VERSION ""

NS_ :

BS_:

BU_:

BO_ 2566642942 DC4: 8 Vector__XXX
 SG_ EnableStatusofDoor21 : 4|2@1+ (1,0) [0|3] "" Vector__XXX
 SG_ EnableStatusofDoor22 : 10|2@1+ (1,0) [0|3] "" Vector__XXX
 SG_ EnableStatusofDoor23 : 16|2@1+ (1,0) [0|3] "" Vector__XXX
 SG_ EnableStatusofDoor24 : 22|2@1+ (1,0) [0|3] "" Vector__XXX
 SG_ EnableStatusofDoor25 : 28|2@1+ (1,0) [0|3] "" Vector__XXX
 SG_ EnableStatusofDoor26 : 34|2@1+ (1,0) [0|3] "" Vector__XXX
 SG_ EnableStatusofDoor27 : 40|2@1+ (1,0) [0|3] "" Vector__XXX
 SG_ EnableStatusofDoor28 : 46|2@1+ (1,0) [0|3] "" Vector__XXX
 SG_ EnableStatusofDoor29 : 52|2@1+ (1,0) [0|3] "" Vector__XXX
 SG_ EnableStatusofDoor30 : 58|2@1+ (1,0) [0|3] "" Vector__XXX
 SG_ LockStatusofDoor21 : 0|2@1+ (1,0) [0|3] "" Vector__XXX
 SG_ LockStatusofDoor22 : 6|2@1+ (1,0) [0|3] "" Vector__XXX
 SG_ LockStatusofDoor23 : 12|2@1+ (1,0) [0|3] "" Vector__XXX
 SG_ LockStatusofDoor24 : 18|2@1+ (1,0) [0|3] "" Vector__XXX
 SG_ LockStatusofDoor25 : 24|2@1+ (1,0) [0|3] "" Vector__XXX
 SG_ LockStatusofDoor26 : 30|2@1+ (1,0) [0|3] "" Vector__XXX
 SG_ LockStatusofDoor27 : 36|2@1+ (1,0) [0|3] "" Vector__XXX
 SG_ LockStatusofDoor28 : 42|2@1+ (1,0) [0|3] "" Vector__XXX
 SG_ LockStatusofDoor29 : 48|2@1+ (1,0) [0|3] "" Vector__XXX
 SG_ LockStatusofDoor30 : 54|2@1+ (1,0) [0|3] "" Vector__XXX
 SG_ OpenStatusofDoor21 : 2|2@1+ (1,0) [0|3] "" Vector__XXX
 SG_ OpenStatusofDoor22 : 8|2@1+ (1,0) [0|3] "" Vector__XXX
 SG_ OpenStatusofDoor23 : 14|2@1+ (1,0) [0|3] "" Vector__XXX
 SG_ OpenStatusofDoor24 : 20|2@1+ (1,0) [0|3] "" Vector__XXX
 SG_ OpenStatusofDoor25 : 26|2@1+ (1,0) [0|3] "" Vector__XXX
 SG_ OpenStatusofDoor26 : 32|2@1+ (1,0) [0|3] "" Vector__XXX
 SG_ OpenStatusofDoor27 : 38|2@1+ (1,0) [0|3] "" Vector__XXX
 SG_ OpenStatusofDoor28 : 44|2@1+ (1,0) [0|3] "" Vector__XXX
 SG_ OpenStatusofDoor29 : 50|2@1+ (1,0) [0|3] "" Vector__XXX
 SG_ OpenStatusofDoor30 : 56|2@1+ (1,0) [0|3] "" Vector__XXX

BO_ 2566643198 DC3: 8 Vector__XXX
 SG_ EnableStatusofDoor11 : 4|2@1+ (1,0) [0|3] "" Vector__XXX
 SG_ EnableStatusofDoor12 : 10|2@1+ (1,0) [0|3] "" Vector__XXX
 SG_ EnableStatusofDoor13 : 16|2@1+ (1,0) [0|3] "" Vector__XXX
 SG_ EnableStatusofDoor14 : 22|2@1+ (1,0) [0|3] "" Vector__XXX
 SG_ EnableStatusofDoor15 : 28|2@1+ (1,0) [0|3] "" Vector__XXX
 SG_ EnableStatusofDoor16 : 34|2@1+ (1,0) [0|3] "" Vector__XXX
 SG_ EnableStatusofDoor17 : 40|2@1+ (1,0) [0|3] "" Vector__XXX
 SG_ EnableStatusofDoor18 : 46|2@1+ (1,0) [0|3] "" Vector__XXX
 SG_ EnableStatusofDoor19 : 52|2@1+ (1,0) [0|3] "" Vector__XXX
 SG_ EnableStatusofDoor20 : 58|2@1+ (1,0) [0|3] "" Vector__XXX
 SG_ LockStatusofDoor11 : 0|2@1+ (1,0) [0|3] "" Vector__XXX
 SG_ LockStatusofDoor12 : 6|2@1+ (1,0) [0|3] "" Vector__XXX
 SG_ LockStatusofDoor13 : 12|2@1+ (1,0) [0|3] "" Vector__XXX
 SG_ LockStatusofDoor14 : 18|2@1+ (1,0) [0|3] "" Vector__XXX
 SG_ LockStatusofDoor15 : 24|2@1+ (1,0) [0|3] "" Vector__XXX
 SG_ LockStatusofDoor16 : 30|2@1+ (1,0) [0|3] "" Vector__XXX
 SG_ LockStatusofDoor17 : 36|2@1+ (1,0) [0|3] "" Vector__XXX
 SG_ LockStatusofDoor18 : 42|2@1+ (1,0) [0|3] "" Vector__XXX
 SG_ LockStatusofDoor19 : 48|2@1+ (1,0) [0|3] "" Vector__XXX
 SG_ LockStatusofDoor20 : 54|2@1+ (1,0) [0|3] "" Vector__XXX
 SG_ OpenStatusofDoor11 : 2|2@1+ (1,0) [0|3] "" Vector__XXX
 SG_ OpenStatusofDoor12 : 8|2@1+ (1,0) [0|3] "" Vector__XXX
 SG_ OpenStatusofDoor13 : 14|2@1+ (1,0) [0|3] "" Vector__XXX
 SG_ OpenStatusofDoor14 : 20|2@1+ (1,0) [0|3] "" Vector__XXX
 SG_ OpenStatusofDoor15 : 26|2@1+ (1,0) [0|3] "" Vector__XXX
 SG_ OpenStatusofDoor16 : 32|2@1+ (1,0) [0|3] "" Vector__XXX
 SG_ OpenStatusofDoor17 : 38|2@1+ (1,0) [0|3] "" Vector__XXX
 SG_ OpenStatusofDoor18 : 44|2@1+ (1,0) [0|3] "" Vector__XXX
 SG_ OpenStatusofDoor19 : 50|2@1+ (1,0) [0|3] "" Vector__XXX
 SG_ OpenStatusofDoor20 : 56|2@1+ (1,0) [0|3] "" Vector__XXX

BO_ 2566643454 ET6: 8 Vector__XXX
 SG_ EngineIntakeCoolantTemperature : 32|16@1+ (0.03125,-273) [-273|1734.96875] "degC" Vector__XXX
 SG_ EngnChrgArClrIntkClntTmprtr : 0|16@1+ (0.03125,-273) [-273|1734.96875] "degC" Vector__XXX
 SG_ EngnChrgArClrOtltClntTmprtr : 16|16@1+ (0.03125,-273) [-273|1734.96875] "degC" Vector__XXX

BO_ 2566643710 IC3: 8 Vector__XXX
 SG_ EngineMixer1IntakePressure : 0|16@1+ (0.1,0) [0|6425.5] "kPa" Vector__XXX
 SG_ EngineMixer2IntakePressure : 16|16@1+ (0.1,0) [0|6425.5] "kPa" Vector__XXX

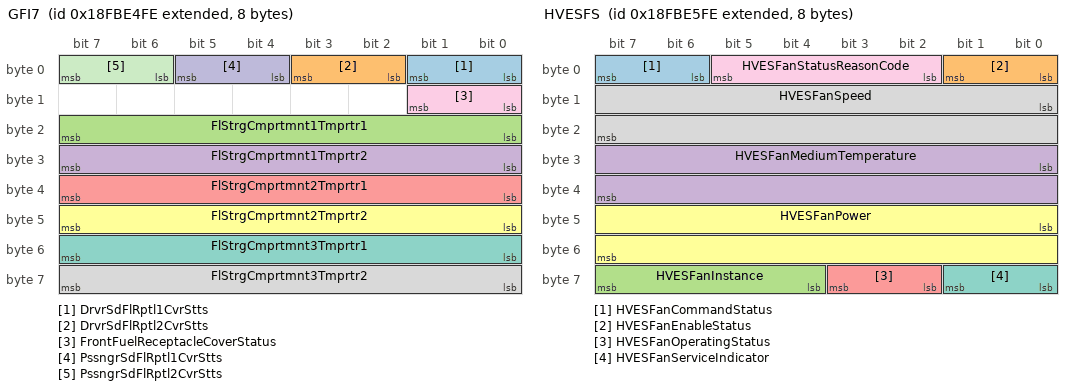
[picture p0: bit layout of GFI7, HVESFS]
BO_ 2566644990 GFI7: 8 Vector__XXX
 SG_ DrvrSdFlRptl1CvrStts : 0|2@1+ (1,0) [0|3] "" Vector__XXX
 SG_ DrvrSdFlRptl2CvrStts : 2|2@1+ (1,0) [0|3] "" Vector__XXX
 SG_ FlStrgCmprtmnt1Tmprtr1 : 16|8@1+ (1,-40) [-40|210] "degC" Vector__XXX
 SG_ FlStrgCmprtmnt1Tmprtr2 : 24|8@1+ (1,-40) [-40|210] "degC" Vector__XXX
 SG_ FlStrgCmprtmnt2Tmprtr1 : 32|8@1+ (1,-40) [-40|210] "degC" Vector__XXX
 SG_ FlStrgCmprtmnt2Tmprtr2 : 40|8@1+ (1,-40) [-40|210] "degC" Vector__XXX
 SG_ FlStrgCmprtmnt3Tmprtr1 : 48|8@1+ (1,-40) [-40|210] "degC" Vector__XXX
 SG_ FlStrgCmprtmnt3Tmprtr2 : 56|8@1+ (1,-40) [-40|210] "degC" Vector__XXX
 SG_ FrontFuelReceptacleCoverStatus : 8|2@1+ (1,0) [0|3] "" Vector__XXX
 SG_ PssngrSdFlRptl1CvrStts : 4|2@1+ (1,0) [0|3] "" Vector__XXX
 SG_ PssngrSdFlRptl2CvrStts : 6|2@1+ (1,0) [0|3] "" Vector__XXX

BO_ 2566645246 HVESFS: 8 Vector__XXX
 SG_ HVESFanCommandStatus : 6|2@1+ (1,0) [0|3] "" Vector__XXX
 SG_ HVESFanEnableStatus : 0|2@1+ (1,0) [0|3] "" Vector__XXX
 SG_ HVESFanInstance : 60|4@1+ (1,0) [0|15] "" Vector__XXX
 SG_ HVESFanMediumTemperature : 24|16@1+ (0.03125,-273) [-273|1734.96875] "degC" Vector__XXX
 SG_ HVESFanOperatingStatus : 58|2@1+ (1,0) [0|3] "" Vector__XXX
 SG_ HVESFanPower : 40|16@1+ (0.5,0) [0|32127.5] "W" Vector__XXX
 SG_ HVESFanServiceIndicator : 56|2@1+ (1,0) [0|3] "" Vector__XXX
 SG_ HVESFanSpeed : 8|16@1+ (0.5,0) [0|32127.5] "rpm" Vector__XXX
 SG_ HVESFanStatusReasonCode : 2|4@1+ (1,0) [0|15] "" Vector__XXX

BO_ 2566646782 ODMCF12: 8 Vector__XXX
 SG_ OlDrsMntrFrrsBn1Cnt : 8|24@1+ (1,0) [0|1.64495E+07] "count" Vector__XXX
 SG_ OlDrsMntrFrrsBn2Cnt : 32|24@1+ (1,0) [0|1.64495E+07] "count" Vector__XXX
 SG_ OlDrsMntrFrrsBns1nd2IdntftnNmr : 0|8@1+ (1,0) [0|250] "count" Vector__XXX

BO_ 2566647038 ODMCF34: 8 Vector__XXX
 SG_ OlDrsMntrFrrsBn3Cnt : 8|24@1+ (1,0) [0|1.64495E+07] "count" Vector__XXX
 SG_ OlDrsMntrFrrsBn4Cnt : 32|24@1+ (1,0) [0|1.64495E+07] "count" Vector__XXX
 SG_ OlDrsMntrFrrsBns3nd4IdntftnNmr : 0|8@1+ (1,0) [0|250] "count" Vector__XXX

BO_ 2566647294 ODMCF56: 8 Vector__XXX
 SG_ OlDrsMntrFrrsBn5Cnt : 8|24@1+ (1,0) [0|1.64495E+07] "count" Vector__XXX
 SG_ OlDrsMntrFrrsBn6Cnt : 32|24@1+ (1,0) [0|1.64495E+07] "count" Vector__XXX
 SG_ OlDrsMntrFrrsBns5nd6IdntftnNmr : 0|8@1+ (1,0) [0|250] "count" Vector__XXX

BO_ 2566647550 ODMCNF12: 8 Vector__XXX
 SG_ ODsMtNFsBs1d2IdttN : 0|8@1+ (1,0) [0|250] "count" Vector__XXX
 SG_ OlDrsMntrNnFrrsBn1Cnt : 8|24@1+ (1,0) [0|1.64495E+07] "count" Vector__XXX
 SG_ OlDrsMntrNnFrrsBn2Cnt : 32|24@1+ (1,0) [0|1.64495E+07] "count" Vector__XXX

BO_ 2566647806 ODMCNF34: 8 Vector__XXX
 SG_ ODsMtNFsBs3d4IdttN : 0|8@1+ (1,0) [0|250] "count" Vector__XXX
 SG_ OlDrsMntrNnFrrsBn3Cnt : 8|24@1+ (1,0) [0|1.64495E+07] "count" Vector__XXX
 SG_ OlDrsMntrNnFrrsBn4Cnt : 32|24@1+ (1,0) [0|1.64495E+07] "count" Vector__XXX

BO_ 2566648062 ODMCNF56: 8 Vector__XXX
 SG_ ODsMtNFsBs5d6IdttN : 0|8@1+ (1,0) [0|250] "count" Vector__XXX
 SG_ OlDrsMntrNnFrrsBn5Cnt : 8|24@1+ (1,0) [0|1.64495E+07] "count" Vector__XXX
 SG_ OlDrsMntrNnFrrsBn6Cnt : 32|24@1+ (1,0) [0|1.64495E+07] "count" Vector__XXX

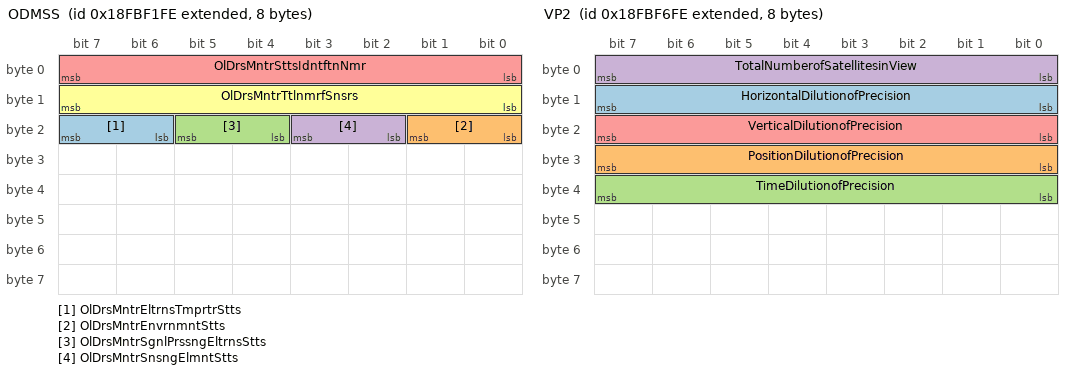
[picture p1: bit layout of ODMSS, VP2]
BO_ 2566648318 ODMSS: 8 Vector__XXX
 SG_ OlDrsMntrEltrnsTmprtrStts : 22|2@1+ (1,0) [0|3] "" Vector__XXX
 SG_ OlDrsMntrEnvrnmntStts : 16|2@1+ (1,0) [0|3] "" Vector__XXX
 SG_ OlDrsMntrSgnlPrssngEltrnsStts : 20|2@1+ (1,0) [0|3] "" Vector__XXX
 SG_ OlDrsMntrSnsngElmntStts : 18|2@1+ (1,0) [0|3] "" Vector__XXX
 SG_ OlDrsMntrSttsIdntftnNmr : 0|8@1+ (1,0) [0|250] "count" Vector__XXX
 SG_ OlDrsMntrTtlnmrfSnsrs : 8|8@1+ (1,0) [0|250] "count" Vector__XXX

BO_ 2566649086 A2DOC2: 8 Vector__XXX
 SG_ Atttt2DOCIttDPFOttDtPss : 32|16@1+ (0.1,0) [0|6425.5] "kPa" Vector__XXX
 SG_ Atttt2DsOxdtCtstItPss : 0|16@1+ (0.1,0) [0|6425.5] "kPa" Vector__XXX
 SG_ Atttt2DsOxdtCtstOttPss : 16|16@1+ (0.1,0) [0|6425.5] "kPa" Vector__XXX

BO_ 2566649342 A1DOC2: 8 Vector__XXX
 SG_ Atttt1DOCIttDPFOttDtPss : 32|16@1+ (0.1,0) [0|6425.5] "kPa" Vector__XXX
 SG_ Atttt1DsOxdtCtstItPss : 0|16@1+ (0.1,0) [0|6425.5] "kPa" Vector__XXX
 SG_ Atttt1DsOxdtCtstOttPss : 16|16@1+ (0.1,0) [0|6425.5] "kPa" Vector__XXX

BO_ 2566649598 VP2: 8 Vector__XXX
 SG_ HorizontalDilutionofPrecision : 8|8@1+ (0.1,0) [0|25] "Ratio" Vector__XXX
 SG_ PositionDilutionofPrecision : 24|8@1+ (0.1,0) [0|25] "Ratio" Vector__XXX
 SG_ TimeDilutionofPrecision : 32|8@1+ (0.1,0) [0|25] "Ratio" Vector__XXX
 SG_ TotalNumberofSatellitesinView : 0|8@1+ (1,0) [0|250] "count" Vector__XXX
 SG_ VerticalDilutionofPrecision : 16|8@1+ (0.1,0) [0|25] "Ratio" Vector__XXX

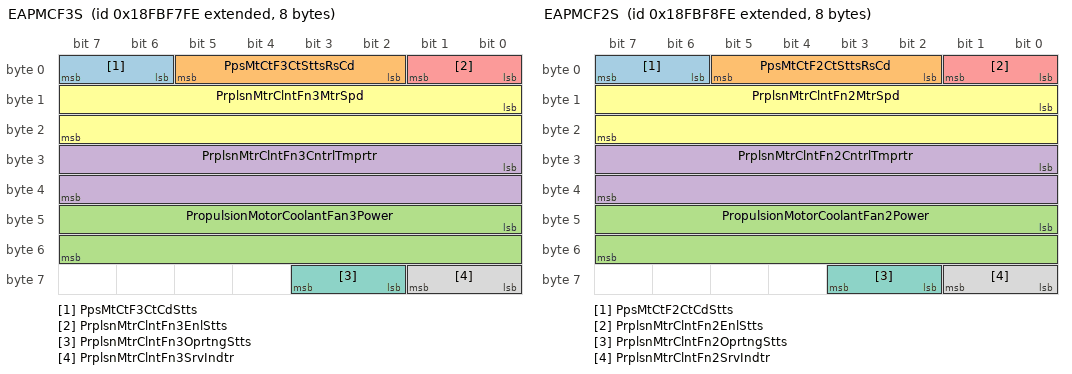
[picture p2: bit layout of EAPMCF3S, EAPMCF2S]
BO_ 2566649854 EAPMCF3S: 8 Vector__XXX
 SG_ PpsMtCtF3CtCdStts : 6|2@1+ (1,0) [0|3] "" Vector__XXX
 SG_ PpsMtCtF3CtSttsRsCd : 2|4@1+ (1,0) [0|15] "" Vector__XXX
 SG_ PropulsionMotorCoolantFan3Power : 40|16@1+ (0.5,0) [0|32127.5] "W" Vector__XXX
 SG_ PrplsnMtrClntFn3CntrlTmprtr : 24|16@1+ (0.03125,-273) [-273|1734.96875] "degC" Vector__XXX
 SG_ PrplsnMtrClntFn3EnlStts : 0|2@1+ (1,0) [0|3] "" Vector__XXX
 SG_ PrplsnMtrClntFn3MtrSpd : 8|16@1+ (0.5,0) [0|32127.5] "rpm" Vector__XXX
 SG_ PrplsnMtrClntFn3OprtngStts : 58|2@1+ (1,0) [0|3] "" Vector__XXX
 SG_ PrplsnMtrClntFn3SrvIndtr : 56|2@1+ (1,0) [0|3] "" Vector__XXX

BO_ 2566650110 EAPMCF2S: 8 Vector__XXX
 SG_ PpsMtCtF2CtCdStts : 6|2@1+ (1,0) [0|3] "" Vector__XXX
 SG_ PpsMtCtF2CtSttsRsCd : 2|4@1+ (1,0) [0|15] "" Vector__XXX
 SG_ PropulsionMotorCoolantFan2Power : 40|16@1+ (0.5,0) [0|32127.5] "W" Vector__XXX
 SG_ PrplsnMtrClntFn2CntrlTmprtr : 24|16@1+ (0.03125,-273) [-273|1734.96875] "degC" Vector__XXX
 SG_ PrplsnMtrClntFn2EnlStts : 0|2@1+ (1,0) [0|3] "" Vector__XXX
 SG_ PrplsnMtrClntFn2MtrSpd : 8|16@1+ (0.5,0) [0|32127.5] "rpm" Vector__XXX
 SG_ PrplsnMtrClntFn2OprtngStts : 58|2@1+ (1,0) [0|3] "" Vector__XXX
 SG_ PrplsnMtrClntFn2SrvIndtr : 56|2@1+ (1,0) [0|3] "" Vector__XXX

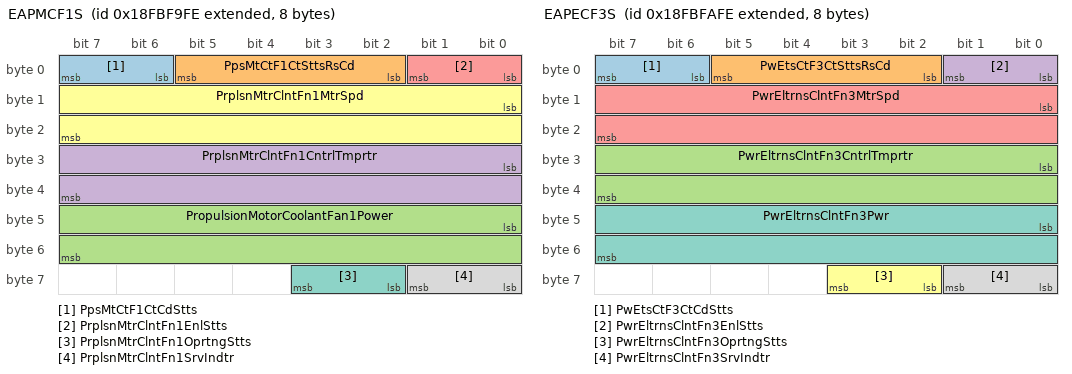
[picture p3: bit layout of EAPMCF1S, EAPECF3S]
BO_ 2566650366 EAPMCF1S: 8 Vector__XXX
 SG_ PpsMtCtF1CtCdStts : 6|2@1+ (1,0) [0|3] "" Vector__XXX
 SG_ PpsMtCtF1CtSttsRsCd : 2|4@1+ (1,0) [0|15] "" Vector__XXX
 SG_ PropulsionMotorCoolantFan1Power : 40|16@1+ (0.5,0) [0|32127.5] "W" Vector__XXX
 SG_ PrplsnMtrClntFn1CntrlTmprtr : 24|16@1+ (0.03125,-273) [-273|1734.96875] "degC" Vector__XXX
 SG_ PrplsnMtrClntFn1EnlStts : 0|2@1+ (1,0) [0|3] "" Vector__XXX
 SG_ PrplsnMtrClntFn1MtrSpd : 8|16@1+ (0.5,0) [0|32127.5] "rpm" Vector__XXX
 SG_ PrplsnMtrClntFn1OprtngStts : 58|2@1+ (1,0) [0|3] "" Vector__XXX
 SG_ PrplsnMtrClntFn1SrvIndtr : 56|2@1+ (1,0) [0|3] "" Vector__XXX

BO_ 2566650622 EAPECF3S: 8 Vector__XXX
 SG_ PwEtsCtF3CtCdStts : 6|2@1+ (1,0) [0|3] "" Vector__XXX
 SG_ PwEtsCtF3CtSttsRsCd : 2|4@1+ (1,0) [0|15] "" Vector__XXX
 SG_ PwrEltrnsClntFn3CntrlTmprtr : 24|16@1+ (0.03125,-273) [-273|1734.96875] "degC" Vector__XXX
 SG_ PwrEltrnsClntFn3EnlStts : 0|2@1+ (1,0) [0|3] "" Vector__XXX
 SG_ PwrEltrnsClntFn3MtrSpd : 8|16@1+ (0.5,0) [0|32127.5] "rpm" Vector__XXX
 SG_ PwrEltrnsClntFn3OprtngStts : 58|2@1+ (1,0) [0|3] "" Vector__XXX
 SG_ PwrEltrnsClntFn3Pwr : 40|16@1+ (0.5,0) [0|32127.5] "W" Vector__XXX
 SG_ PwrEltrnsClntFn3SrvIndtr : 56|2@1+ (1,0) [0|3] "" Vector__XXX

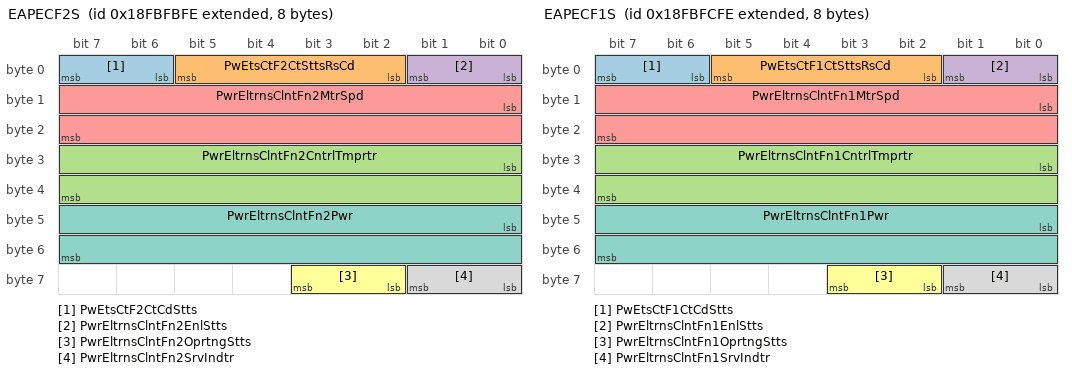
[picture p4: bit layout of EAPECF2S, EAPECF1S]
BO_ 2566650878 EAPECF2S: 8 Vector__XXX
 SG_ PwEtsCtF2CtCdStts : 6|2@1+ (1,0) [0|3] "" Vector__XXX
 SG_ PwEtsCtF2CtSttsRsCd : 2|4@1+ (1,0) [0|15] "" Vector__XXX
 SG_ PwrEltrnsClntFn2CntrlTmprtr : 24|16@1+ (0.03125,-273) [-273|1734.96875] "degC" Vector__XXX
 SG_ PwrEltrnsClntFn2EnlStts : 0|2@1+ (1,0) [0|3] "" Vector__XXX
 SG_ PwrEltrnsClntFn2MtrSpd : 8|16@1+ (0.5,0) [0|32127.5] "rpm" Vector__XXX
 SG_ PwrEltrnsClntFn2OprtngStts : 58|2@1+ (1,0) [0|3] "" Vector__XXX
 SG_ PwrEltrnsClntFn2Pwr : 40|16@1+ (0.5,0) [0|32127.5] "W" Vector__XXX
 SG_ PwrEltrnsClntFn2SrvIndtr : 56|2@1+ (1,0) [0|3] "" Vector__XXX

BO_ 2566651134 EAPECF1S: 8 Vector__XXX
 SG_ PwEtsCtF1CtCdStts : 6|2@1+ (1,0) [0|3] "" Vector__XXX
 SG_ PwEtsCtF1CtSttsRsCd : 2|4@1+ (1,0) [0|15] "" Vector__XXX
 SG_ PwrEltrnsClntFn1CntrlTmprtr : 24|16@1+ (0.03125,-273) [-273|1734.96875] "degC" Vector__XXX
 SG_ PwrEltrnsClntFn1EnlStts : 0|2@1+ (1,0) [0|3] "" Vector__XXX
 SG_ PwrEltrnsClntFn1MtrSpd : 8|16@1+ (0.5,0) [0|32127.5] "rpm" Vector__XXX
 SG_ PwrEltrnsClntFn1OprtngStts : 58|2@1+ (1,0) [0|3] "" Vector__XXX
 SG_ PwrEltrnsClntFn1Pwr : 40|16@1+ (0.5,0) [0|32127.5] "W" Vector__XXX
 SG_ PwrEltrnsClntFn1SrvIndtr : 56|2@1+ (1,0) [0|3] "" Vector__XXX

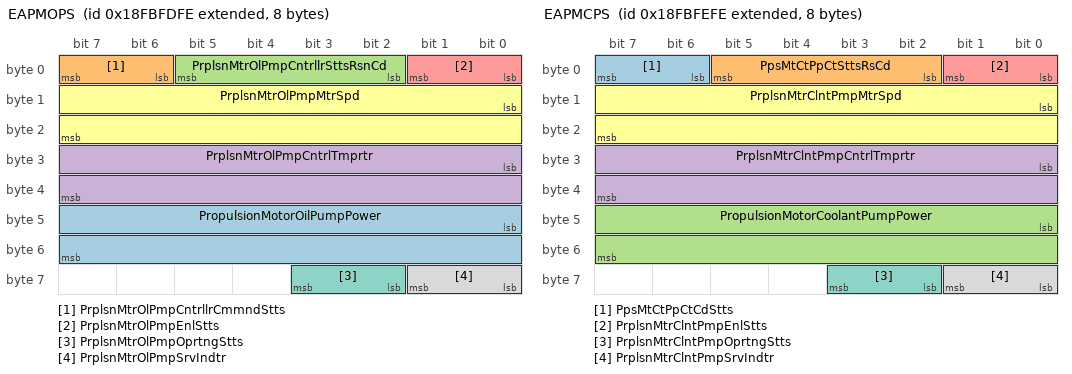
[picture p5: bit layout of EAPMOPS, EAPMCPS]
BO_ 2566651390 EAPMOPS: 8 Vector__XXX
 SG_ PropulsionMotorOilPumpPower : 40|16@1+ (0.5,0) [0|32127.5] "W" Vector__XXX
 SG_ PrplsnMtrOlPmpCntrllrCmmndStts : 6|2@1+ (1,0) [0|3] "" Vector__XXX
 SG_ PrplsnMtrOlPmpCntrllrSttsRsnCd : 2|4@1+ (1,0) [0|15] "" Vector__XXX
 SG_ PrplsnMtrOlPmpCntrlTmprtr : 24|16@1+ (0.03125,-273) [-273|1734.96875] "degC" Vector__XXX
 SG_ PrplsnMtrOlPmpEnlStts : 0|2@1+ (1,0) [0|3] "" Vector__XXX
 SG_ PrplsnMtrOlPmpMtrSpd : 8|16@1+ (0.5,0) [0|32127.5] "rpm" Vector__XXX
 SG_ PrplsnMtrOlPmpOprtngStts : 58|2@1+ (1,0) [0|3] "" Vector__XXX
 SG_ PrplsnMtrOlPmpSrvIndtr : 56|2@1+ (1,0) [0|3] "" Vector__XXX

BO_ 2566651646 EAPMCPS: 8 Vector__XXX
 SG_ PpsMtCtPpCtCdStts : 6|2@1+ (1,0) [0|3] "" Vector__XXX
 SG_ PpsMtCtPpCtSttsRsCd : 2|4@1+ (1,0) [0|15] "" Vector__XXX
 SG_ PropulsionMotorCoolantPumpPower : 40|16@1+ (0.5,0) [0|32127.5] "W" Vector__XXX
 SG_ PrplsnMtrClntPmpCntrlTmprtr : 24|16@1+ (0.03125,-273) [-273|1734.96875] "degC" Vector__XXX
 SG_ PrplsnMtrClntPmpEnlStts : 0|2@1+ (1,0) [0|3] "" Vector__XXX
 SG_ PrplsnMtrClntPmpMtrSpd : 8|16@1+ (0.5,0) [0|32127.5] "rpm" Vector__XXX
 SG_ PrplsnMtrClntPmpOprtngStts : 58|2@1+ (1,0) [0|3] "" Vector__XXX
 SG_ PrplsnMtrClntPmpSrvIndtr : 56|2@1+ (1,0) [0|3] "" Vector__XXX

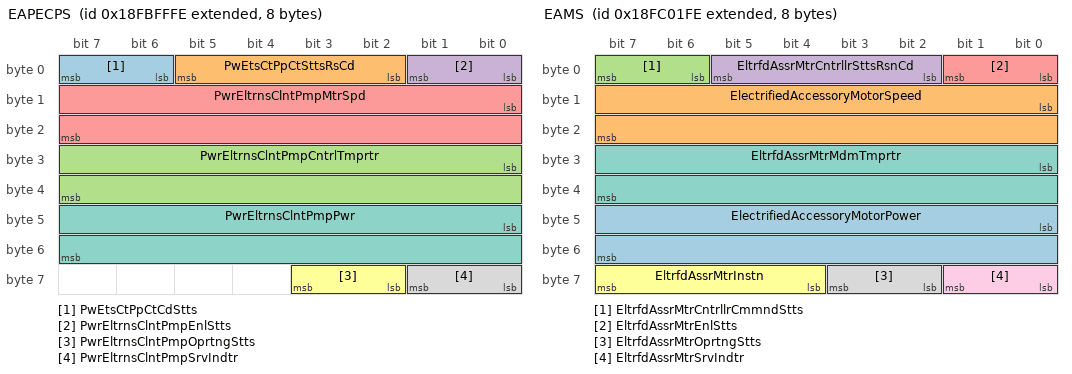
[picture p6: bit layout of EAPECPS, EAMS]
BO_ 2566651902 EAPECPS: 8 Vector__XXX
 SG_ PwEtsCtPpCtCdStts : 6|2@1+ (1,0) [0|3] "" Vector__XXX
 SG_ PwEtsCtPpCtSttsRsCd : 2|4@1+ (1,0) [0|15] "" Vector__XXX
 SG_ PwrEltrnsClntPmpCntrlTmprtr : 24|16@1+ (0.03125,-273) [-273|1734.96875] "degC" Vector__XXX
 SG_ PwrEltrnsClntPmpEnlStts : 0|2@1+ (1,0) [0|3] "" Vector__XXX
 SG_ PwrEltrnsClntPmpMtrSpd : 8|16@1+ (0.5,0) [0|32127.5] "rpm" Vector__XXX
 SG_ PwrEltrnsClntPmpOprtngStts : 58|2@1+ (1,0) [0|3] "" Vector__XXX
 SG_ PwrEltrnsClntPmpPwr : 40|16@1+ (0.5,0) [0|32127.5] "W" Vector__XXX
 SG_ PwrEltrnsClntPmpSrvIndtr : 56|2@1+ (1,0) [0|3] "" Vector__XXX

BO_ 2566652414 EAMS: 8 Vector__XXX
 SG_ ElectrifiedAccessoryMotorPower : 40|16@1+ (0.5,0) [0|32127.5] "W" Vector__XXX
 SG_ ElectrifiedAccessoryMotorSpeed : 8|16@1+ (0.5,0) [0|32127.5] "rpm" Vector__XXX
 SG_ EltrfdAssrMtrCntrllrCmmndStts : 6|2@1+ (1,0) [0|3] "" Vector__XXX
 SG_ EltrfdAssrMtrCntrllrSttsRsnCd : 2|4@1+ (1,0) [0|15] "" Vector__XXX
 SG_ EltrfdAssrMtrEnlStts : 0|2@1+ (1,0) [0|3] "" Vector__XXX
 SG_ EltrfdAssrMtrInstn : 60|4@1+ (1,0) [0|15] "" Vector__XXX
 SG_ EltrfdAssrMtrMdmTmprtr : 24|16@1+ (0.03125,-273) [-273|1734.96875] "degC" Vector__XXX
 SG_ EltrfdAssrMtrOprtngStts : 58|2@1+ (1,0) [0|3] "" Vector__XXX
 SG_ EltrfdAssrMtrSrvIndtr : 56|2@1+ (1,0) [0|3] "" Vector__XXX

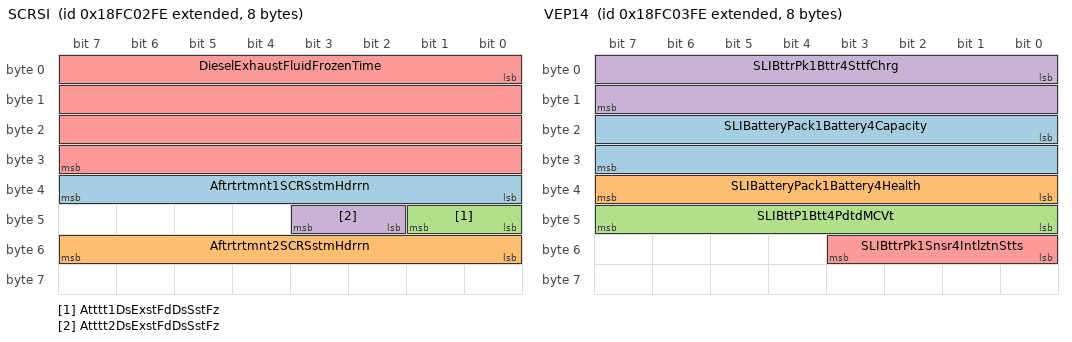
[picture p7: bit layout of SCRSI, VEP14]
BO_ 2566652670 SCRSI: 8 Vector__XXX
 SG_ Aftrtrtmnt1SCRSstmHdrrn : 32|8@1+ (1,0) [0|250] "%" Vector__XXX
 SG_ Aftrtrtmnt2SCRSstmHdrrn : 48|8@1+ (1,0) [0|250] "%" Vector__XXX
 SG_ Atttt1DsExstFdDsSstFz : 40|2@1+ (1,0) [0|3] "" Vector__XXX
 SG_ Atttt2DsExstFdDsSstFz : 42|2@1+ (1,0) [0|3] "" Vector__XXX
 SG_ DieselExhaustFluidFrozenTime : 0|32@1+ (1,0) [0|4.21108E+09] "s" Vector__XXX

BO_ 2566652926 VEP14: 8 Vector__XXX
 SG_ SLIBatteryPack1Battery4Capacity : 16|16@1+ (1,0) [0|64255] "Ah" Vector__XXX
 SG_ SLIBatteryPack1Battery4Health : 32|8@1+ (0.5,0) [0|125] "%" Vector__XXX
 SG_ SLIBttP1Btt4PdtdMCVt : 40|8@1+ (0.2,0) [0|50] "V" Vector__XXX
 SG_ SLIBttrPk1Bttr4SttfChrg : 0|16@1+ (0.0025,0) [0|160.6375] "%" Vector__XXX
 SG_ SLIBttrPk1Snsr4IntlztnStts : 48|4@1+ (1,0) [0|15] "" Vector__XXX

BO_ 2566653182 VEP13: 8 Vector__XXX
 SG_ SLIBatteryPack1Battery4Voltage : 24|16@1+ (0.05,0) [0|3212.75] "V" Vector__XXX
 SG_ SLIBttrPk1Bttr4NtCrrnt : 0|16@1+ (0.05,-1600) [-1600|1612.75] "A" Vector__XXX
 SG_ SLIBttrPk1Bttr4Tmprtr : 16|8@1+ (1,-40) [-40|210] "degC" Vector__XXX

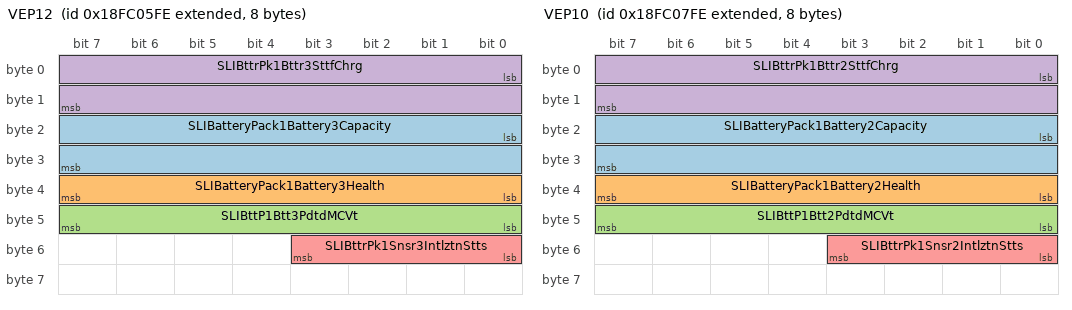
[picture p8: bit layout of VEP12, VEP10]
BO_ 2566653438 VEP12: 8 Vector__XXX
 SG_ SLIBatteryPack1Battery3Capacity : 16|16@1+ (1,0) [0|64255] "Ah" Vector__XXX
 SG_ SLIBatteryPack1Battery3Health : 32|8@1+ (0.5,0) [0|125] "%" Vector__XXX
 SG_ SLIBttP1Btt3PdtdMCVt : 40|8@1+ (0.2,0) [0|50] "V" Vector__XXX
 SG_ SLIBttrPk1Bttr3SttfChrg : 0|16@1+ (0.0025,0) [0|160.6375] "%" Vector__XXX
 SG_ SLIBttrPk1Snsr3IntlztnStts : 48|4@1+ (1,0) [0|15] "" Vector__XXX

BO_ 2566653694 VEP11: 8 Vector__XXX
 SG_ SLIBatteryPack1Battery3Voltage : 24|16@1+ (0.05,0) [0|3212.75] "V" Vector__XXX
 SG_ SLIBttrPk1Bttr3NtCrrnt : 0|16@1+ (0.05,-1600) [-1600|1612.75] "A" Vector__XXX
 SG_ SLIBttrPk1Bttr3Tmprtr : 16|8@1+ (1,-40) [-40|210] "degC" Vector__XXX

BO_ 2566653950 VEP10: 8 Vector__XXX
 SG_ SLIBatteryPack1Battery2Capacity : 16|16@1+ (1,0) [0|64255] "Ah" Vector__XXX
 SG_ SLIBatteryPack1Battery2Health : 32|8@1+ (0.5,0) [0|125] "%" Vector__XXX
 SG_ SLIBttP1Btt2PdtdMCVt : 40|8@1+ (0.2,0) [0|50] "V" Vector__XXX
 SG_ SLIBttrPk1Bttr2SttfChrg : 0|16@1+ (0.0025,0) [0|160.6375] "%" Vector__XXX
 SG_ SLIBttrPk1Snsr2IntlztnStts : 48|4@1+ (1,0) [0|15] "" Vector__XXX

BO_ 2566654206 VEP9: 8 Vector__XXX
 SG_ SLIBatteryPack1Battery2Voltage : 24|16@1+ (0.05,0) [0|3212.75] "V" Vector__XXX
 SG_ SLIBttrPk1Bttr2NtCrrnt : 0|16@1+ (0.05,-1600) [-1600|1612.75] "A" Vector__XXX
 SG_ SLIBttrPk1Bttr2Tmprtr : 16|8@1+ (1,-40) [-40|210] "degC" Vector__XXX

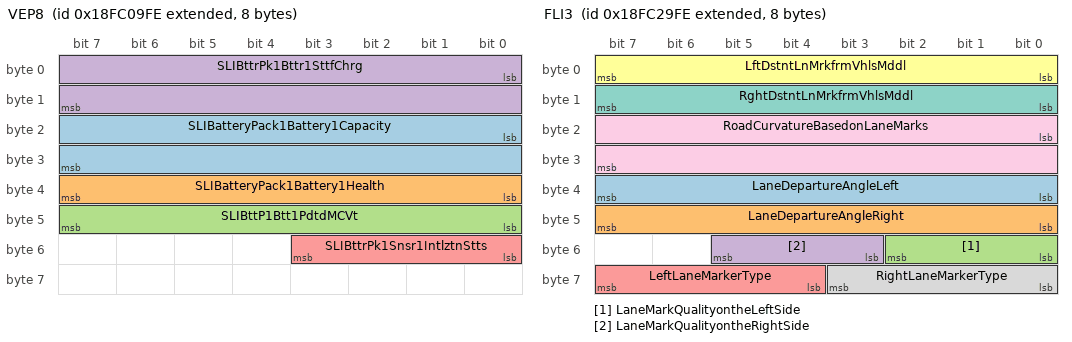
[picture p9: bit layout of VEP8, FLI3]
BO_ 2566654462 VEP8: 8 Vector__XXX
 SG_ SLIBatteryPack1Battery1Capacity : 16|16@1+ (1,0) [0|64255] "Ah" Vector__XXX
 SG_ SLIBatteryPack1Battery1Health : 32|8@1+ (0.5,0) [0|125] "%" Vector__XXX
 SG_ SLIBttP1Btt1PdtdMCVt : 40|8@1+ (0.2,0) [0|50] "V" Vector__XXX
 SG_ SLIBttrPk1Bttr1SttfChrg : 0|16@1+ (0.0025,0) [0|160.6375] "%" Vector__XXX
 SG_ SLIBttrPk1Snsr1IntlztnStts : 48|4@1+ (1,0) [0|15] "" Vector__XXX

BO_ 2566654718 VEP7: 8 Vector__XXX
 SG_ SLIBatteryPack1Battery1Voltage : 24|16@1+ (0.05,0) [0|3212.75] "V" Vector__XXX
 SG_ SLIBttrPk1Bttr1NtCrrnt : 0|16@1+ (0.05,-1600) [-1600|1612.75] "A" Vector__XXX
 SG_ SLIBttrPk1Bttr1Tmprtr : 16|8@1+ (1,-40) [-40|210] "degC" Vector__XXX

BO_ 2566654974 EEC20: 8 Vector__XXX
 SG_ AtlMxmmAvllEngnPrntFl : 16|8@1+ (0.4,0) [0|100] "%" Vector__XXX
 SG_ EsttdEPstLsssPtTqHRst : 0|16@1+ (0.0015625,0) [0|100.3984375] "%" Vector__XXX

BO_ 2566655742 PHRPS: 8 Vector__XXX
 SG_ RearHitchPitchSensitivity : 8|8@1+ (0.4,0) [0|100] "%" Vector__XXX
 SG_ RearHitchRollSensitivity : 0|8@1+ (0.4,0) [0|100] "%" Vector__XXX

BO_ 2566656254 AMB3: 8 Vector__XXX
 SG_ BarometricAbsolutePressure2 : 0|16@1+ (0.1,0) [0|6425.5] "kPa" Vector__XXX
 SG_ EngineIntake2AirTemperature : 16|8@1+ (1,-40) [-40|210] "degC" Vector__XXX

BO_ 2566656510 TGFI: 8 Vector__XXX
 SG_ EngnTtlGssFlVlmUsd : 0|32@1+ (0.5,0) [0|2105540607.5] "m*m*m" Vector__XXX
 SG_ EngnTtlGssIdlFlVlmUsd : 32|32@1+ (0.5,0) [0|2105540607.5] "m*m*m" Vector__XXX

BO_ 2566658302 PLST2: 8 Vector__XXX
 SG_ TotalPayloadTransactionCount : 0|32@1+ (1,0) [0|4.21108E+09] "count" Vector__XXX

BO_ 2566658558 PLST1: 8 Vector__XXX
 SG_ TotalDeliveredPayloadWeight : 0|32@1+ (100,0) [0|4E+11] "kg" Vector__XXX
 SG_ TotalHaulCycleCount : 32|32@1+ (1,0) [0|4.21108E+09] "count" Vector__XXX

BO_ 2566661118 LFC2: 8 Vector__XXX
 SG_ EngineTotalDieselFuelDemand : 0|32@1+ (0.5,0) [0|2105540607.5] "l" Vector__XXX

BO_ 2566661374 AT2T1I2: 8 Vector__XXX
 SG_ Aftrtrtmnt2DslExhstFldTnkHtr2 : 16|8@1+ (0.4,0) [0|100] "%" Vector__XXX
 SG_ Aftrtrtmnt2DslExhstFldTnkVlm2 : 0|8@1+ (0.4,0) [0|100] "%" Vector__XXX
 SG_ Atttt2DsExstFdTTpt2 : 8|8@1+ (1,-40) [-40|210] "degC" Vector__XXX

BO_ 2566661630 AT1T1I2: 8 Vector__XXX
 SG_ Aftrtrtmnt1DslExhstFldTnkHtr2 : 16|8@1+ (0.4,0) [0|100] "%" Vector__XXX
 SG_ Aftrtrtmnt1DslExhstFldTnkVlm2 : 0|8@1+ (0.4,0) [0|100] "%" Vector__XXX
 SG_ Atttt1DsExstFdTTpt2 : 8|8@1+ (1,-40) [-40|210] "degC" Vector__XXX

BO_ 2566661886 A2DEFI2: 8 Vector__XXX
 SG_ Atttt2DsExstFdCt2Tpt : 8|8@1+ (1,-40) [-40|210] "degC" Vector__XXX
 SG_ Atttt2DsExstFdCtTpt : 0|8@1+ (1,-40) [-40|210] "degC" Vector__XXX

BO_ 2566662142 A1DEFI2: 8 Vector__XXX
 SG_ Atttt1DsExstFdCt1Tpt : 0|8@1+ (1,-40) [-40|210] "degC" Vector__XXX
 SG_ Atttt1DsExstFdCt2Tpt : 8|8@1+ (1,-40) [-40|210] "degC" Vector__XXX

BO_ 2566662654 FLI3: 8 Vector__XXX
 SG_ LaneDepartureAngleLeft : 32|8@1+ (0.1,-12.5) [-12.5|12.5] "deg" Vector__XXX
 SG_ LaneDepartureAngleRight : 40|8@1+ (0.1,-12.5) [-12.5|12.5] "deg" Vector__XXX
 SG_ LaneMarkQualityontheLeftSide : 48|3@1+ (1,0) [0|7] "" Vector__XXX
 SG_ LaneMarkQualityontheRightSide : 51|3@1+ (1,0) [0|7] "" Vector__XXX
 SG_ LeftLaneMarkerType : 60|4@1+ (1,0) [0|15] "" Vector__XXX
 SG_ LftDstntLnMrkfrmVhlsMddl : 0|8@1+ (0.02,0) [0|5] "m" Vector__XXX
 SG_ RghtDstntLnMrkfrmVhlsMddl : 8|8@1+ (0.02,0) [0|5] "m" Vector__XXX
 SG_ RightLaneMarkerType : 56|4@1+ (1,0) [0|15] "" Vector__XXX
 SG_ RoadCurvatureBasedonLaneMarks : 16|16@1+ (0.0078125,-250) [-250|251.992] "1/km" Vector__XXX

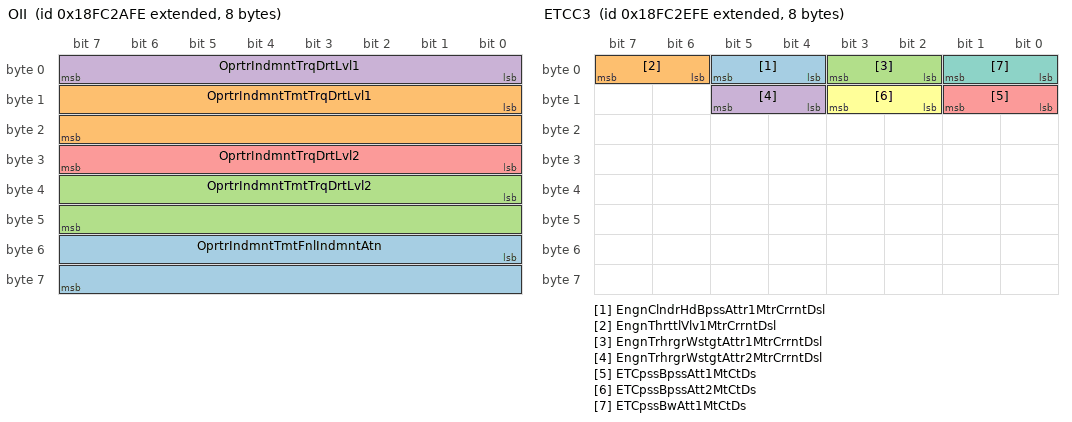
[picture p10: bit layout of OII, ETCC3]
BO_ 2566662910 OII: 8 Vector__XXX
 SG_ OprtrIndmntTmtFnlIndmntAtn : 48|16@1+ (1,0) [0|64255] "min" Vector__XXX
 SG_ OprtrIndmntTmtTrqDrtLvl1 : 8|16@1+ (1,0) [0|64255] "min" Vector__XXX
 SG_ OprtrIndmntTmtTrqDrtLvl2 : 32|16@1+ (1,0) [0|64255] "min" Vector__XXX
 SG_ OprtrIndmntTrqDrtLvl1 : 0|8@1+ (1,0) [0|250] "%" Vector__XXX
 SG_ OprtrIndmntTrqDrtLvl2 : 24|8@1+ (1,0) [0|250] "%" Vector__XXX

BO_ 2566663166 CCVS4: 8 Vector__XXX
 SG_ AppldVhlSpdLmtHghRsltn : 0|16@1+ (0.00390625,0) [0|250.996] "km/h" Vector__XXX
 SG_ CrsCntrlAdjstdMxmmSpd : 16|16@1+ (0.00390625,0) [0|250.996] "km/h" Vector__XXX
 SG_ EngnExtrnlIdlRqstFdk : 32|2@1+ (1,0) [0|3] "" Vector__XXX
 SG_ SAddssCtDvSttCsCt : 40|8@1+ (1,0) [0|255] "SA" Vector__XXX

BO_ 2566663422 BCLC: 8 Vector__XXX
 SG_ TrlrBrkClprLnngClrnAxl1Lft : 20|2@1+ (1,0) [0|3] "" Vector__XXX
 SG_ TrlrBrkClprLnngClrnAxl1Rght : 22|2@1+ (1,0) [0|3] "" Vector__XXX
 SG_ TrlrBrkClprLnngClrnAxl2Lft : 24|2@1+ (1,0) [0|3] "" Vector__XXX
 SG_ TrlrBrkClprLnngClrnAxl2Rght : 26|2@1+ (1,0) [0|3] "" Vector__XXX
 SG_ TrlrBrkClprLnngClrnAxl3Lft : 28|2@1+ (1,0) [0|3] "" Vector__XXX
 SG_ TrlrBrkClprLnngClrnAxl3Rght : 30|2@1+ (1,0) [0|3] "" Vector__XXX
 SG_ TrlrBrkClprLnngClrnAxl4Lft : 32|2@1+ (1,0) [0|3] "" Vector__XXX
 SG_ TrlrBrkClprLnngClrnAxl4Rght : 34|2@1+ (1,0) [0|3] "" Vector__XXX
 SG_ TrlrBrkClprLnngClrnAxl5Lft : 36|2@1+ (1,0) [0|3] "" Vector__XXX
 SG_ TrlrBrkClprLnngClrnAxl5Rght : 38|2@1+ (1,0) [0|3] "" Vector__XXX
 SG_ TrtrBrkClprLnngClrnAxl1Lft : 0|2@1+ (1,0) [0|3] "" Vector__XXX
 SG_ TrtrBrkClprLnngClrnAxl1Rght : 2|2@1+ (1,0) [0|3] "" Vector__XXX
 SG_ TrtrBrkClprLnngClrnAxl2Lft : 4|2@1+ (1,0) [0|3] "" Vector__XXX
 SG_ TrtrBrkClprLnngClrnAxl2Rght : 6|2@1+ (1,0) [0|3] "" Vector__XXX
 SG_ TrtrBrkClprLnngClrnAxl3Lft : 8|2@1+ (1,0) [0|3] "" Vector__XXX
 SG_ TrtrBrkClprLnngClrnAxl3Rght : 10|2@1+ (1,0) [0|3] "" Vector__XXX
 SG_ TrtrBrkClprLnngClrnAxl4Lft : 12|2@1+ (1,0) [0|3] "" Vector__XXX
 SG_ TrtrBrkClprLnngClrnAxl4Rght : 14|2@1+ (1,0) [0|3] "" Vector__XXX
 SG_ TrtrBrkClprLnngClrnAxl5Lft : 16|2@1+ (1,0) [0|3] "" Vector__XXX
 SG_ TrtrBrkClprLnngClrnAxl5Rght : 18|2@1+ (1,0) [0|3] "" Vector__XXX

BO_ 2566663678 AF5: 8 Vector__XXX
 SG_ EngnFl2InjtrMtrngRl1Tmprtr2 : 32|8@1+ (1,-40) [-40|210] "degC" Vector__XXX
 SG_ LNGTank1VaporPressure : 0|16@1+ (0.1,0) [0|6425.5] "kPa" Vector__XXX
 SG_ LNGTank2VaporPressure : 16|16@1+ (0.1,0) [0|6425.5] "kPa" Vector__XXX

BO_ 2566663934 ETCC3: 8 Vector__XXX
 SG_ EngnClndrHdBpssAttr1MtrCrrntDsl : 4|2@1+ (1,0) [0|3] "" Vector__XXX
 SG_ EngnThrttlVlv1MtrCrrntDsl : 6|2@1+ (1,0) [0|3] "" Vector__XXX
 SG_ EngnTrhrgrWstgtAttr1MtrCrrntDsl : 2|2@1+ (1,0) [0|3] "" Vector__XXX
 SG_ EngnTrhrgrWstgtAttr2MtrCrrntDsl : 12|2@1+ (1,0) [0|3] "" Vector__XXX
 SG_ ETCpssBpssAtt1MtCtDs : 8|2@1+ (1,0) [0|3] "" Vector__XXX
 SG_ ETCpssBpssAtt2MtCtDs : 10|2@1+ (1,0) [0|3] "" Vector__XXX
 SG_ ETCpssBwAtt1MtCtDs : 0|2@1+ (1,0) [0|3] "" Vector__XXX

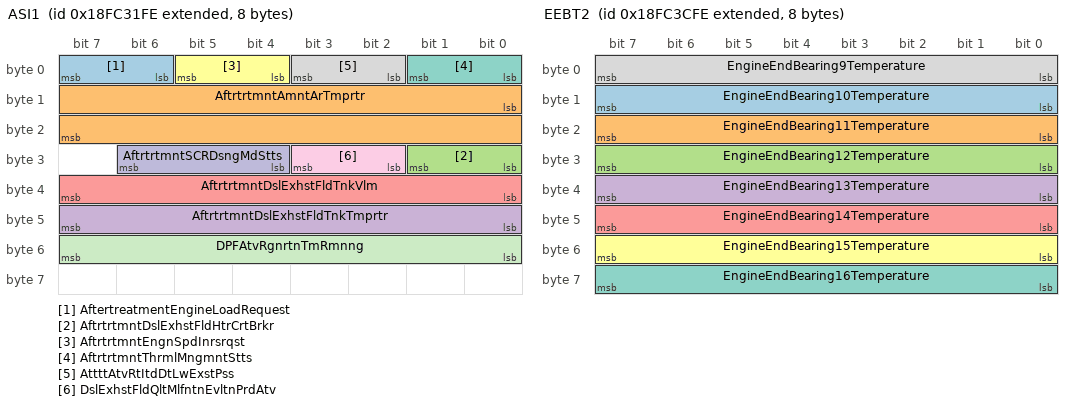
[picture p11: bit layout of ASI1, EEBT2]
BO_ 2566664702 ASI1: 8 Vector__XXX
 SG_ AftertreatmentEngineLoadRequest : 6|2@1+ (1,0) [0|3] "" Vector__XXX
 SG_ AftrtrtmntAmntArTmprtr : 8|16@1+ (0.03125,-273) [-273|1734.96875] "degC" Vector__XXX
 SG_ AftrtrtmntDslExhstFldHtrCrtBrkr : 24|2@1+ (1,0) [0|3] "" Vector__XXX
 SG_ AftrtrtmntDslExhstFldTnkTmprtr : 40|8@1+ (1,-40) [-40|210] "degC" Vector__XXX
 SG_ AftrtrtmntDslExhstFldTnkVlm : 32|8@1+ (0.4,0) [0|100] "%" Vector__XXX
 SG_ AftrtrtmntEngnSpdInrsrqst : 4|2@1+ (1,0) [0|3] "" Vector__XXX
 SG_ AftrtrtmntThrmlMngmntStts : 0|2@1+ (1,0) [0|3] "" Vector__XXX
 SG_ AttttAtvRtItdDtLwExstPss : 2|2@1+ (1,0) [0|3] "" Vector__XXX
 SG_ DslExhstFldQltMlfntnEvltnPrdAtv : 26|2@1+ (1,0) [0|3] "" Vector__XXX
 SG_ AftrtrtmntSCRDsngMdStts : 28|3@1+ (1,0) [0|7] "" Vector__XXX
 SG_ DPFAtvRgnrtnTmRmnng : 48|8@1+ (1,0) [0|250] "min" Vector__XXX

BO_ 2566665726 AT2P1I: 8 Vector__XXX
 SG_ Aftrtrtmnt2DslExhstFldPmpHtr : 0|8@1+ (0.4,0) [0|100] "%" Vector__XXX
 SG_ Atttt2DsExstFdPp2MtSpd : 8|16@1+ (0.5,0) [0|32127.5] "rpm" Vector__XXX

BO_ 2566667262 EEBT3: 8 Vector__XXX
 SG_ EngineEndBearing17Temperature : 0|8@1+ (1,-40) [-40|210] "degC" Vector__XXX
 SG_ EngineEndBearing18Temperature : 8|8@1+ (1,-40) [-40|210] "degC" Vector__XXX
 SG_ EngineEndBearing19Temperature : 16|8@1+ (1,-40) [-40|210] "degC" Vector__XXX
 SG_ EngineEndBearing20Temperature : 24|8@1+ (1,-40) [-40|210] "degC" Vector__XXX

BO_ 2566667518 EEBT2: 8 Vector__XXX
 SG_ EngineEndBearing10Temperature : 8|8@1+ (1,-40) [-40|210] "degC" Vector__XXX
 SG_ EngineEndBearing11Temperature : 16|8@1+ (1,-40) [-40|210] "degC" Vector__XXX
 SG_ EngineEndBearing12Temperature : 24|8@1+ (1,-40) [-40|210] "degC" Vector__XXX
 SG_ EngineEndBearing13Temperature : 32|8@1+ (1,-40) [-40|210] "degC" Vector__XXX
 SG_ EngineEndBearing14Temperature : 40|8@1+ (1,-40) [-40|210] "degC" Vector__XXX
 SG_ EngineEndBearing15Temperature : 48|8@1+ (1,-40) [-40|210] "degC" Vector__XXX
 SG_ EngineEndBearing16Temperature : 56|8@1+ (1,-40) [-40|210] "degC" Vector__XXX
 SG_ EngineEndBearing9Temperature : 0|8@1+ (1,-40) [-40|210] "degC" Vector__XXX

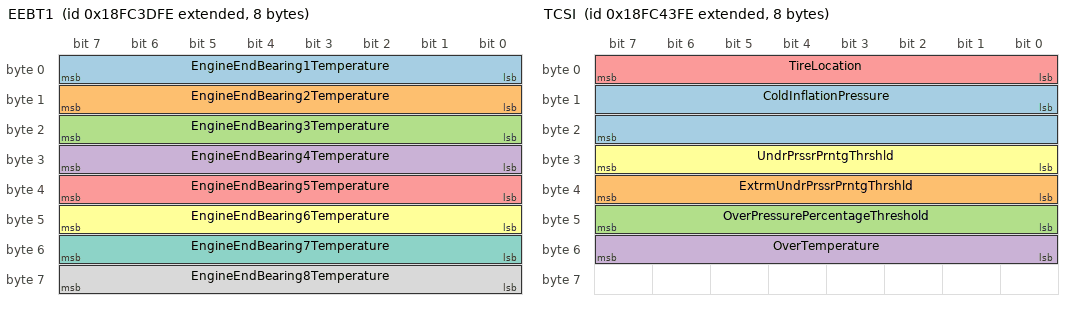
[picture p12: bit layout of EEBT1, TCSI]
BO_ 2566667774 EEBT1: 8 Vector__XXX
 SG_ EngineEndBearing1Temperature : 0|8@1+ (1,-40) [-40|210] "degC" Vector__XXX
 SG_ EngineEndBearing2Temperature : 8|8@1+ (1,-40) [-40|210] "degC" Vector__XXX
 SG_ EngineEndBearing3Temperature : 16|8@1+ (1,-40) [-40|210] "degC" Vector__XXX
 SG_ EngineEndBearing4Temperature : 24|8@1+ (1,-40) [-40|210] "degC" Vector__XXX
 SG_ EngineEndBearing5Temperature : 32|8@1+ (1,-40) [-40|210] "degC" Vector__XXX
 SG_ EngineEndBearing6Temperature : 40|8@1+ (1,-40) [-40|210] "degC" Vector__XXX
 SG_ EngineEndBearing7Temperature : 48|8@1+ (1,-40) [-40|210] "degC" Vector__XXX
 SG_ EngineEndBearing8Temperature : 56|8@1+ (1,-40) [-40|210] "degC" Vector__XXX

BO_ 2566668030 HEDPI: 8 Vector__XXX
 SG_ HeatExchangerDebrisPurgeStatus : 0|2@1+ (1,0) [0|3] "" Vector__XXX
 SG_ HtExhngrDrsPrgApprhng : 2|2@1+ (1,0) [0|3] "" Vector__XXX

BO_ 2566668286 ETCC2: 8 Vector__XXX
 SG_ EngnStgdTrhrgrSlndStts : 0|8@1+ (0.4,0) [0|100] "%" Vector__XXX

BO_ 2566668542 EHF2PC: 8 Vector__XXX
 SG_ EngnFl2PmpHdrlDrtnlVlv : 16|8@1+ (0.4,0) [0|100] "%" Vector__XXX
 SG_ EngnFl2PmpHdrlFlwCntrlVlv : 0|8@1+ (0.4,0) [0|100] "%" Vector__XXX
 SG_ EngnFl2PmpHdrlPrssr : 24|16@1+ (2,0) [0|128510] "kPa" Vector__XXX
 SG_ EngnFl2PmpHdrlSwshPltAngl : 8|8@1+ (0.4,0) [0|100] "%" Vector__XXX

BO_ 2566668798 AF4: 8 Vector__XXX
 SG_ EngnFl2InjtrMtrngRl1Prssr : 0|16@1+ (2,0) [0|128510] "kPa" Vector__XXX
 SG_ EngnFl2InjtrMtrngRl1Prssr2 : 48|16@1+ (2,0) [0|128510] "kPa" Vector__XXX
 SG_ EngnFl2InjtrMtrngRl1Tmprtr : 32|8@1+ (1,-40) [-40|210] "degC" Vector__XXX
 SG_ EngnFl2InjtrMtrngRl2Prssr : 16|16@1+ (2,0) [0|128510] "kPa" Vector__XXX
 SG_ EngnFl2InjtrMtrngRl2Tmprtr : 40|8@1+ (1,-40) [-40|210] "degC" Vector__XXX

BO_ 2566669054 TIRE2: 8 Vector__XXX
 SG_ RequiredTirePressure : 24|16@1+ (1,0) [0|64255] "kPa" Vector__XXX
 SG_ TireLocation : 0|8@1+ (8,0) [0|0] "bit-mapped" Vector__XXX
 SG_ TirePressureExtendedRange : 8|16@1+ (1,0) [0|64255] "kPa" Vector__XXX

BO_ 2566669310 TCSI: 8 Vector__XXX
 SG_ ColdInflationPressure : 8|16@1+ (1,0) [0|64255] "kPa" Vector__XXX
 SG_ ExtrmUndrPrssrPrntgThrshld : 32|8@1+ (0.5,0) [0|125] "%" Vector__XXX
 SG_ OverPressurePercentageThreshold : 40|8@1+ (0.5,0) [0|125] "%" Vector__XXX
 SG_ OverTemperature : 48|8@1+ (1,-40) [-40|210] "degC" Vector__XXX
 SG_ TireLocation : 0|8@1+ (8,0) [0|0] "bit-mapped" Vector__XXX
 SG_ UndrPrssrPrntgThrshld : 24|8@1+ (0.5,0) [0|125] "%" Vector__XXX

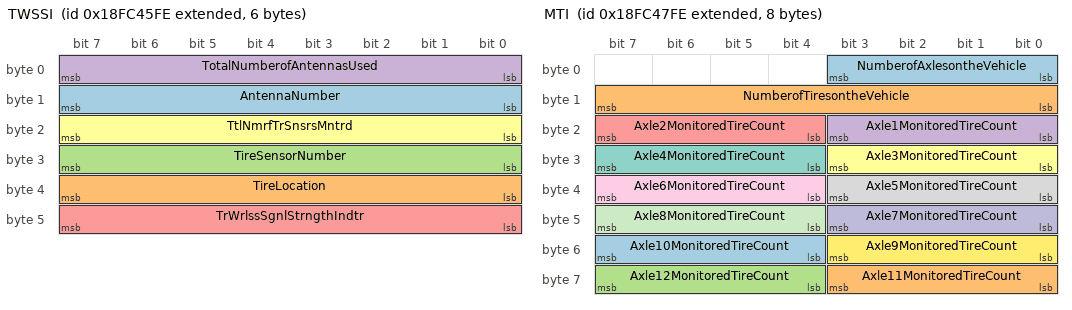
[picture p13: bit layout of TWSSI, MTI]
BO_ 2566669822 TWSSI: 6 Vector__XXX
 SG_ AntennaNumber : 8|8@1+ (1,0) [0|250] "count" Vector__XXX
 SG_ TireLocation : 32|8@1+ (8,0) [0|0] "bit-mapped" Vector__XXX
 SG_ TireSensorNumber : 24|8@1+ (1,0) [0|250] "count" Vector__XXX
 SG_ TotalNumberofAntennasUsed : 0|8@1+ (1,0) [0|250] "count" Vector__XXX
 SG_ TrWrlssSgnlStrngthIndtr : 40|8@1+ (0.5,-125) [-125|0] "dBm" Vector__XXX
 SG_ TtlNmrfTrSnsrsMntrd : 16|8@1+ (1,0) [0|250] "count" Vector__XXX

BO_ 2566670078 TSIS: 200 Vector__XXX
 SG_ NumberofTireSensors : 0|8@1+ (1,0) [0|250] "count" Vector__XXX
 SG_ TireLocation : 16|8@1+ (1,0) [0|255] "count" Vector__XXX
 SG_ TireNumber : 8|8@1+ (1,0) [0|250] "count" Vector__XXX
 SG_ TireSensorIdentificationNumber : 24|8@1+ (1,0) [0|255] "ASCII" Vector__XXX

BO_ 2566670334 MTI: 8 Vector__XXX
 SG_ Axle10MonitoredTireCount : 52|4@1+ (1,0) [0|13] "count" Vector__XXX
 SG_ Axle11MonitoredTireCount : 56|4@1+ (1,0) [0|13] "count" Vector__XXX
 SG_ Axle12MonitoredTireCount : 60|4@1+ (1,0) [0|13] "count" Vector__XXX
 SG_ Axle1MonitoredTireCount : 16|4@1+ (1,0) [0|13] "count" Vector__XXX
 SG_ Axle2MonitoredTireCount : 20|4@1+ (1,0) [0|13] "count" Vector__XXX
 SG_ Axle3MonitoredTireCount : 24|4@1+ (1,0) [0|13] "count" Vector__XXX
 SG_ Axle4MonitoredTireCount : 28|4@1+ (1,0) [0|13] "count" Vector__XXX
 SG_ Axle5MonitoredTireCount : 32|4@1+ (1,0) [0|13] "count" Vector__XXX
 SG_ Axle6MonitoredTireCount : 36|4@1+ (1,0) [0|13] "count" Vector__XXX
 SG_ Axle7MonitoredTireCount : 40|4@1+ (1,0) [0|13] "count" Vector__XXX
 SG_ Axle8MonitoredTireCount : 44|4@1+ (1,0) [0|13] "count" Vector__XXX
 SG_ Axle9MonitoredTireCount : 48|4@1+ (1,0) [0|13] "count" Vector__XXX
 SG_ NumberofAxlesontheVehicle : 0|4@1+ (1,0) [0|13] "count" Vector__XXX
 SG_ NumberofTiresontheVehicle : 8|8@1+ (1,0) [0|250] "count" Vector__XXX

BO_ 2566670590 AT2HI2: 24 Vector__XXX
 SG_ Atttt2SCRSstAvDstBtwSstCEvts : 160|32@1+ (0.125,0) [0|526385151.875] "km" Vector__XXX
 SG_ Atttt2SCRSstAvTBtwSstCEvts : 128|32@1+ (1,0) [0|4.21108E+09] "s" Vector__XXX
 SG_ Atttt2SCRSstTtNSstCEvts : 32|32@1+ (1,0) [0|4.21108E+09] "count" Vector__XXX
 SG_ Atttt2SCRSstTtNSstCItRqsts : 64|32@1+ (1,0) [0|4.21108E+09] "count" Vector__XXX
 SG_ Atttt2SCRSstTtNSstCMRqsts : 96|32@1+ (1,0) [0|4.21108E+09] "count" Vector__XXX
 SG_ Atttt2SCRSstTtSstCT : 0|32@1+ (1,0) [0|4.21108E+09] "s" Vector__XXX

BO_ 2566670846 AT1HI2: 28 Vector__XXX
 SG_ Aftrtrtmnt1SCRSstmTtlClnngTm : 0|32@1+ (1,0) [0|4.21108E+09] "s" Vector__XXX
 SG_ Atttt1SCRSstAvDstBtwSstCEvts : 160|32@1+ (0.125,0) [0|526385151.875] "km" Vector__XXX
 SG_ Atttt1SCRSstAvTBtwSstCEvts : 128|32@1+ (1,0) [0|4.21108E+09] "s" Vector__XXX
 SG_ Atttt1SCRSstTtNSstCEvts : 32|32@1+ (1,0) [0|4.21108E+09] "count" Vector__XXX
 SG_ Atttt1SCRSstTtNSstCItRqsts : 64|32@1+ (1,0) [0|4.21108E+09] "count" Vector__XXX
 SG_ Atttt1SCRSstTtNSstCMRqsts : 96|32@1+ (1,0) [0|4.21108E+09] "count" Vector__XXX
 SG_ TtlAftrtrtmntOprtngHrs : 192|32@1+ (1,0) [0|4.21108E+09] "s" Vector__XXX

BO_ 2566671102 SCRSC: 8 Vector__XXX
 SG_ Atttt1SCRSstCdtsNtMtAtvC : 60|2@1+ (1,0) [0|3] "" Vector__XXX
 SG_ SCRSstCItdDtAtPdOId : 26|2@1+ (1,0) [0|3] "" Vector__XXX
 SG_ SCRSstCItdDtLwExstTpt : 34|2@1+ (1,0) [0|3] "" Vector__XXX
 SG_ SCRSstCItdDtPtSstLt : 42|2@1+ (1,0) [0|3] "" Vector__XXX
 SG_ SCRSstCItdDtVSpdAvAwdSpd : 30|2@1+ (1,0) [0|3] "" Vector__XXX
 SG_ SCRSstCItdDtVSpdBwAwdSpd : 46|2@1+ (1,0) [0|3] "" Vector__XXX
 SG_ SCRSstmClnngAtmtInttnCnfgrtn : 48|2@1+ (1,0) [0|3] "" Vector__XXX
 SG_ SCRSstmClnngInhtdDtClthDsnggd : 20|2@1+ (1,0) [0|3] "" Vector__XXX
 SG_ SCRSstmClnngInhtdDtEngnNtWrmdUp : 44|2@1+ (1,0) [0|3] "" Vector__XXX
 SG_ SCRSstmClnngInhtdDtInhtSwth : 18|2@1+ (1,0) [0|3] "" Vector__XXX
 SG_ SCRSstmClnngInhtdDtOtfNtrl : 28|2@1+ (1,0) [0|3] "" Vector__XXX
 SG_ SCRSstmClnngInhtdDtPrkngBrkNtSt : 32|2@1+ (1,0) [0|3] "" Vector__XXX
 SG_ SCRSstmClnngInhtdDtPTOAtv : 24|2@1+ (1,0) [0|3] "" Vector__XXX
 SG_ SCRSstmClnngInhtdDtSrvBrkAtv : 22|2@1+ (1,0) [0|3] "" Vector__XXX
 SG_ SCRSstmClnngInhtdDtSstmFltAtv : 36|2@1+ (1,0) [0|3] "" Vector__XXX
 SG_ SCRSstmClnngInhtdDtSstmTmt : 38|2@1+ (1,0) [0|3] "" Vector__XXX
 SG_ SCRSstmClnngInhtdDtTmprrSstmLkt : 40|2@1+ (1,0) [0|3] "" Vector__XXX
 SG_ SCRSstmClnngInhtdStts : 16|2@1+ (1,0) [0|3] "" Vector__XXX
 SG_ SCRSystemCleaningForcedStatus : 53|3@1+ (1,0) [0|7] "" Vector__XXX
 SG_ SCRSystemCleaningLampCommand : 0|3@1+ (1,0) [0|7] "" Vector__XXX
 SG_ SCRSystemCleaningStatus : 10|2@1+ (1,0) [0|3] "" Vector__XXX

BO_ 2566671358 EEC17: 8 Vector__XXX
 SG_ CylinderFuelRate : 48|16@1+ (0.03125,0) [0|2007.96875] "mg/stroke" Vector__XXX
 SG_ EngineExhaustFlowRate : 32|16@1+ (0.2,0) [0|12851] "kg/h" Vector__XXX
 SG_ PEMSEngineFuelMassFlowRate : 0|16@1+ (0.02,0) [0|1285.1] "g/s" Vector__XXX
 SG_ VehicleFuelRate : 16|16@1+ (0.02,0) [0|1285.1] "g/s" Vector__XXX

BO_ 2566671614 SCROII3: 8 Vector__XXX
 SG_ NSCROptIdtOvdEvtsR : 24|8@1+ (1,0) [0|250] "count" Vector__XXX
 SG_ SCROprtrIndmntOvrrdEnl : 0|2@1+ (1,0) [0|3] "" Vector__XXX
 SG_ SCROprtrIndmntOvrrdTmRmnng : 8|16@1+ (1,0) [0|64255] "s" Vector__XXX
 SG_ TtlNmrfSCROprtrIndmntOvrrdEvnts : 32|16@1+ (1,0) [0|64255] "count" Vector__XXX

BO_ 2566671870 A2SCRDSI3: 8 Vector__XXX
 SG_ Aftrtrtmnt2DslExhstFldDsr2Prssr : 24|8@1+ (4,0) [0|1000] "kPa" Vector__XXX
 SG_ Aftrtrtmnt2DslExhstFldDsrPrssr : 0|8@1+ (4,0) [0|1000] "kPa" Vector__XXX
 SG_ Atttt2DsExstFdDs2AstPss : 8|8@1+ (8,0) [0|2000] "kPa" Vector__XXX
 SG_ Atttt2DsExstFdDs2Tpt : 16|8@1+ (1,-40) [-40|210] "degC" Vector__XXX

BO_ 2566672126 A1SCRDSI3: 8 Vector__XXX
 SG_ Aftrtrtmnt1DslExhstFldDsr2Prssr : 24|8@1+ (4,0) [0|1000] "kPa" Vector__XXX
 SG_ Aftrtrtmnt1DslExhstFldDsrPrssr : 0|8@1+ (4,0) [0|1000] "kPa" Vector__XXX
 SG_ Atttt1DsExstFdDs2AstPss : 8|8@1+ (8,0) [0|2000] "kPa" Vector__XXX
 SG_ Atttt1DsExstFdDs2Tpt : 16|8@1+ (1,-40) [-40|210] "degC" Vector__XXX

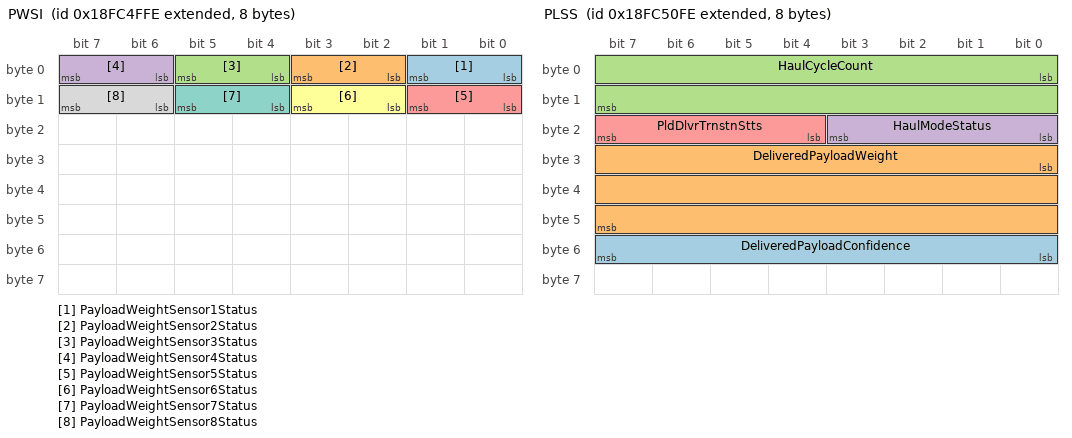
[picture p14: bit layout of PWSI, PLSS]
BO_ 2566672382 PWSI: 8 Vector__XXX
 SG_ PayloadWeightSensor1Status : 0|2@1+ (1,0) [0|3] "" Vector__XXX
 SG_ PayloadWeightSensor2Status : 2|2@1+ (1,0) [0|3] "" Vector__XXX
 SG_ PayloadWeightSensor3Status : 4|2@1+ (1,0) [0|3] "" Vector__XXX
 SG_ PayloadWeightSensor4Status : 6|2@1+ (1,0) [0|3] "" Vector__XXX
 SG_ PayloadWeightSensor5Status : 8|2@1+ (1,0) [0|3] "" Vector__XXX
 SG_ PayloadWeightSensor6Status : 10|2@1+ (1,0) [0|3] "" Vector__XXX
 SG_ PayloadWeightSensor7Status : 12|2@1+ (1,0) [0|3] "" Vector__XXX
 SG_ PayloadWeightSensor8Status : 14|2@1+ (1,0) [0|3] "" Vector__XXX

BO_ 2566672638 PLSS: 8 Vector__XXX
 SG_ DeliveredPayloadConfidence : 48|8@1+ (0.5,0) [0|125] "%" Vector__XXX
 SG_ DeliveredPayloadWeight : 24|24@1+ (2,0) [0|3E+07] "kg" Vector__XXX
 SG_ HaulCycleCount : 0|16@1+ (1,0) [0|64255] "count" Vector__XXX
 SG_ HaulModeStatus : 16|4@1+ (1,0) [0|15] "" Vector__XXX
 SG_ PldDlvrTrnstnStts : 20|4@1+ (1,0) [0|15] "" Vector__XXX

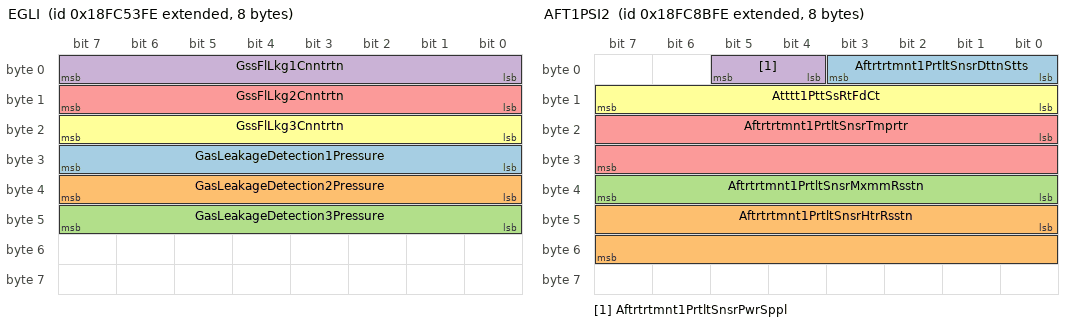
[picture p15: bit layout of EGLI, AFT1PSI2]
BO_ 2566673406 EGLI: 8 Vector__XXX
 SG_ GasLeakageDetection1Pressure : 24|8@1+ (4,0) [0|1000] "kPa" Vector__XXX
 SG_ GasLeakageDetection2Pressure : 32|8@1+ (4,0) [0|1000] "kPa" Vector__XXX
 SG_ GasLeakageDetection3Pressure : 40|8@1+ (4,0) [0|1000] "kPa" Vector__XXX
 SG_ GssFlLkg1Cnntrtn : 0|8@1+ (0.5,0) [0|125] "%" Vector__XXX
 SG_ GssFlLkg2Cnntrtn : 8|8@1+ (0.5,0) [0|125] "%" Vector__XXX
 SG_ GssFlLkg3Cnntrtn : 16|8@1+ (0.5,0) [0|125] "%" Vector__XXX

BO_ 2566674174 SCROII2: 8 Vector__XXX
 SG_ AftrtrtmntSCRMlfntnTm : 0|32@1+ (1,0) [0|4.21108E+09] "s" Vector__XXX
 SG_ SCROperatorInducementTotalTime : 32|32@1+ (1,0) [0|4.21108E+09] "s" Vector__XXX

BO_ 2566674430 SCROII1: 8 Vector__XXX
 SG_ DslExhstFldQltMlfntnTm : 32|32@1+ (1,0) [0|4.21108E+09] "s" Vector__XXX
 SG_ DslExhstFldTnk1EmptTm : 0|32@1+ (1,0) [0|4.21108E+09] "s" Vector__XXX

BO_ 2566674686 TCI7: 8 Vector__XXX
 SG_ EngnTrhrgr2LOlPrssr : 0|8@1+ (4,0) [0|1000] "kPa" Vector__XXX
 SG_ EngnTrhrgr2OlTmprtr : 24|16@1+ (0.03125,-273) [-273|1734.96875] "degC" Vector__XXX
 SG_ EngnTrhrgr3LOlPrssr : 8|8@1+ (4,0) [0|1000] "kPa" Vector__XXX
 SG_ EngnTrhrgr4LOlPrssr : 16|8@1+ (4,0) [0|1000] "kPa" Vector__XXX

BO_ 2566675966 HVES1CFG: 16 Vector__XXX
 SG_ HVES1CellMaximumVoltageLimit : 112|8@1+ (0.02044,0) [0|5.11] "V" Vector__XXX
 SG_ HVES1CellMinimumVoltageLimit : 120|8@1+ (0.02044,0) [0|5.11] "V" Vector__XXX
 SG_ HVES1NominalVoltage : 0|16@1+ (0.05,0) [0|3212.75] "V" Vector__XXX
 SG_ HVES1RmmnddMnmmOprtngTmprtr : 96|16@1+ (0.03125,-273) [-273|1734.96875] "degC" Vector__XXX
 SG_ HVES1RmmnddMnmmOprtngVltg : 16|16@1+ (0.05,0) [0|3212.75] "V" Vector__XXX
 SG_ HVES1RmmnddMnmmSttOfChrg : 48|16@1+ (0.0015625,0) [0|100.3984375] "%" Vector__XXX
 SG_ HVES1RmmnddMxmmOprtngTmprtr : 80|16@1+ (0.03125,-273) [-273|1734.96875] "degC" Vector__XXX
 SG_ HVES1RmmnddMxmmOprtngVltg : 32|16@1+ (0.05,0) [0|3212.75] "V" Vector__XXX
 SG_ HVES1RmmnddMxmmSttOfChrg : 64|16@1+ (0.0015625,0) [0|100.3984375] "%" Vector__XXX

BO_ 2566687742 AFT1PSI2: 8 Vector__XXX
 SG_ Aftrtrtmnt1PrtltSnsrDttnStts : 0|4@1+ (1,0) [0|15] "" Vector__XXX
 SG_ Aftrtrtmnt1PrtltSnsrHtrRsstn : 40|16@1+ (0.1,0) [0|6425.5] "ohm" Vector__XXX
 SG_ Aftrtrtmnt1PrtltSnsrMxmmRsstn : 32|8@1+ (250,0) [0|62500] "kohm" Vector__XXX
 SG_ Aftrtrtmnt1PrtltSnsrPwrSppl : 4|2@1+ (1,0) [0|3] "" Vector__XXX
 SG_ Aftrtrtmnt1PrtltSnsrTmprtr : 16|16@1+ (0.03125,-273) [-273|1734.96875] "degC" Vector__XXX
 SG_ Atttt1PttSsRtFdCt : 8|8@1+ (1,0) [0|250] "count" Vector__XXX

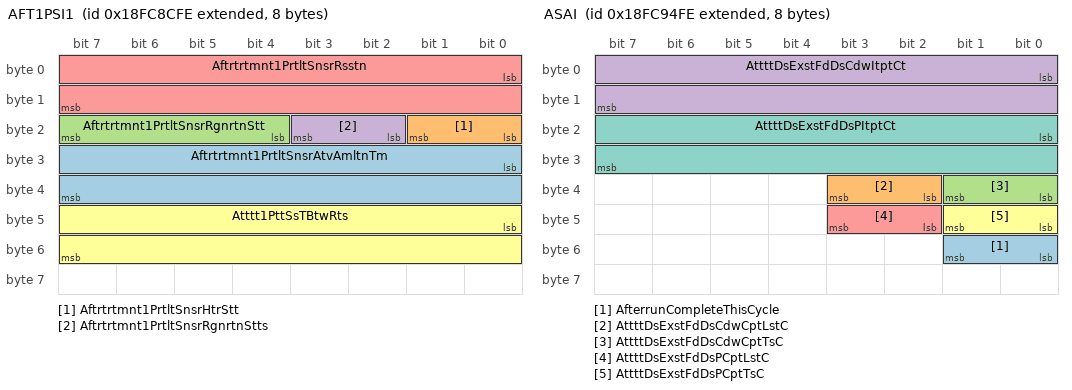
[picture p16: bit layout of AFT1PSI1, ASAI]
BO_ 2566687998 AFT1PSI1: 8 Vector__XXX
 SG_ Aftrtrtmnt1PrtltSnsrAtvAmltnTm : 24|16@1+ (6,0) [0|385530] "s" Vector__XXX
 SG_ Aftrtrtmnt1PrtltSnsrHtrStt : 16|2@1+ (1,0) [0|3] "" Vector__XXX
 SG_ Aftrtrtmnt1PrtltSnsrRgnrtnStt : 20|4@1+ (1,0) [0|15] "" Vector__XXX
 SG_ Aftrtrtmnt1PrtltSnsrRgnrtnStts : 18|2@1+ (1,0) [0|3] "" Vector__XXX
 SG_ Aftrtrtmnt1PrtltSnsrRsstn : 0|16@1+ (1,0) [0|64255] "kohm" Vector__XXX
 SG_ Atttt1PttSsTBtwRts : 40|16@1+ (6,0) [0|385530] "s" Vector__XXX

BO_ 2566689278 EEN: 8 Vector__XXX
 SG_ EngineExhaustDesiredNOx : 16|16@1+ (0.05,-200) [-200|3012.75] "ppm" Vector__XXX
 SG_ EngineExhaustNOx : 0|16@1+ (0.05,-200) [-200|3012.75] "ppm" Vector__XXX
 SG_ EngnExhstNOxSnsrPwrSppl : 32|2@1+ (1,0) [0|3] "" Vector__XXX

BO_ 2566689534 AFR: 8 Vector__XXX
 SG_ EngineMainChamberAirFuelRatio : 0|16@1+ (0.001,0) [0|64.255] "Ratio" Vector__XXX
 SG_ EnginePrechamberAirFuelRatio : 32|16@1+ (0.001,0) [0|64.255] "Ratio" Vector__XXX
 SG_ EngnMnChmrDsrdArFlRt : 16|16@1+ (0.001,0) [0|64.255] "Ratio" Vector__XXX
 SG_ EngnPrhmrDsrdArFlRt : 48|16@1+ (0.001,0) [0|64.255] "Ratio" Vector__XXX

BO_ 2566689790 GFP2: 8 Vector__XXX
 SG_ EngnMnChmrFlAsltPrssr : 0|16@1+ (0.1,0) [0|6425.5] "kPa" Vector__XXX
 SG_ EngnMnChmrFlDsrdAsltPrssr : 16|16@1+ (0.1,0) [0|6425.5] "kPa" Vector__XXX
 SG_ EngnPrhmrFlAsltPrssr : 32|16@1+ (0.1,0) [0|6425.5] "kPa" Vector__XXX
 SG_ EngnPrhmrFlDsrdAsltPrssr : 48|16@1+ (0.1,0) [0|6425.5] "kPa" Vector__XXX

BO_ 2566690046 ASAI: 8 Vector__XXX
 SG_ AfterrunCompleteThisCycle : 48|2@1+ (1,0) [0|3] "" Vector__XXX
 SG_ AttttDsExstFdDsCdwCptLstC : 34|2@1+ (1,0) [0|3] "" Vector__XXX
 SG_ AttttDsExstFdDsCdwCptTsC : 32|2@1+ (1,0) [0|3] "" Vector__XXX
 SG_ AttttDsExstFdDsCdwItptCt : 0|16@1+ (1,0) [0|64255] "count" Vector__XXX
 SG_ AttttDsExstFdDsPCptLstC : 42|2@1+ (1,0) [0|3] "" Vector__XXX
 SG_ AttttDsExstFdDsPCptTsC : 40|2@1+ (1,0) [0|3] "" Vector__XXX
 SG_ AttttDsExstFdDsPItptCt : 16|16@1+ (1,0) [0|64255] "count" Vector__XXX

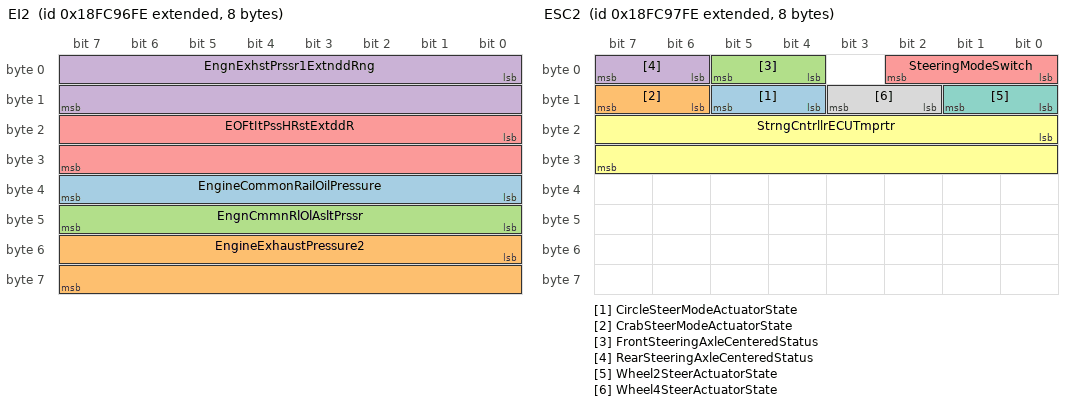
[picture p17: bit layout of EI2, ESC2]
BO_ 2566690558 EI2: 8 Vector__XXX
 SG_ EngineCommonRailOilPressure : 32|8@1+ (4,0) [0|1000] "kPa" Vector__XXX
 SG_ EngineExhaustPressure2 : 48|16@1+ (0.0078125,-250) [-250|251.99] "kPa" Vector__XXX
 SG_ EngnCmmnRlOlAsltPrssr : 40|8@1+ (4,0) [0|1000] "kPa" Vector__XXX
 SG_ EngnExhstPrssr1ExtnddRng : 0|16@1+ (0.125,0) [0|8031.875] "kPa" Vector__XXX
 SG_ EOFtItPssHRstExtddR : 16|16@1+ (0.1,0) [0|6425.5] "kPa" Vector__XXX

BO_ 2566690814 ESC2: 8 Vector__XXX
 SG_ CircleSteerModeActuatorState : 12|2@1+ (1,0) [0|3] "" Vector__XXX
 SG_ CrabSteerModeActuatorState : 14|2@1+ (1,0) [0|3] "" Vector__XXX
 SG_ FrontSteeringAxleCenteredStatus : 4|2@1+ (1,0) [0|3] "" Vector__XXX
 SG_ RearSteeringAxleCenteredStatus : 6|2@1+ (1,0) [0|3] "" Vector__XXX
 SG_ SteeringModeSwitch : 0|3@1+ (1,0) [0|7] "" Vector__XXX
 SG_ StrngCntrllrECUTmprtr : 16|16@1+ (0.03125,-273) [-273|1734.96875] "degC" Vector__XXX
 SG_ Wheel2SteerActuatorState : 8|2@1+ (1,0) [0|3] "" Vector__XXX
 SG_ Wheel4SteerActuatorState : 10|2@1+ (1,0) [0|3] "" Vector__XXX

BO_ 2566691326 AUI: 200 Vector__XXX
 SG_ AssemblyUnitIdentification : 8|8@1+ (1,0) [0|255] "ASCII" Vector__XXX
 SG_ NmrfAssmlUntIdntftnFlds : 0|8@1+ (1,0) [0|250] "count" Vector__XXX

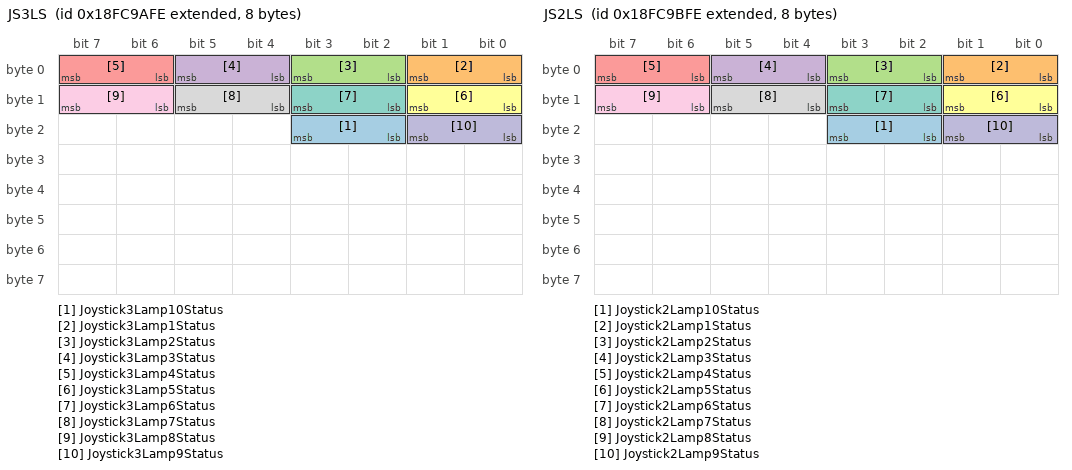
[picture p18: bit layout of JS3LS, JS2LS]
BO_ 2566691582 JS3LS: 8 Vector__XXX
 SG_ Joystick3Lamp10Status : 18|2@1+ (1,0) [0|3] "" Vector__XXX
 SG_ Joystick3Lamp1Status : 0|2@1+ (1,0) [0|3] "" Vector__XXX
 SG_ Joystick3Lamp2Status : 2|2@1+ (1,0) [0|3] "" Vector__XXX
 SG_ Joystick3Lamp3Status : 4|2@1+ (1,0) [0|3] "" Vector__XXX
 SG_ Joystick3Lamp4Status : 6|2@1+ (1,0) [0|3] "" Vector__XXX
 SG_ Joystick3Lamp5Status : 8|2@1+ (1,0) [0|3] "" Vector__XXX
 SG_ Joystick3Lamp6Status : 10|2@1+ (1,0) [0|3] "" Vector__XXX
 SG_ Joystick3Lamp7Status : 12|2@1+ (1,0) [0|3] "" Vector__XXX
 SG_ Joystick3Lamp8Status : 14|2@1+ (1,0) [0|3] "" Vector__XXX
 SG_ Joystick3Lamp9Status : 16|2@1+ (1,0) [0|3] "" Vector__XXX

BO_ 2566691838 JS2LS: 8 Vector__XXX
 SG_ Joystick2Lamp10Status : 18|2@1+ (1,0) [0|3] "" Vector__XXX
 SG_ Joystick2Lamp1Status : 0|2@1+ (1,0) [0|3] "" Vector__XXX
 SG_ Joystick2Lamp2Status : 2|2@1+ (1,0) [0|3] "" Vector__XXX
 SG_ Joystick2Lamp3Status : 4|2@1+ (1,0) [0|3] "" Vector__XXX
 SG_ Joystick2Lamp4Status : 6|2@1+ (1,0) [0|3] "" Vector__XXX
 SG_ Joystick2Lamp5Status : 8|2@1+ (1,0) [0|3] "" Vector__XXX
 SG_ Joystick2Lamp6Status : 10|2@1+ (1,0) [0|3] "" Vector__XXX
 SG_ Joystick2Lamp7Status : 12|2@1+ (1,0) [0|3] "" Vector__XXX
 SG_ Joystick2Lamp8Status : 14|2@1+ (1,0) [0|3] "" Vector__XXX
 SG_ Joystick2Lamp9Status : 16|2@1+ (1,0) [0|3] "" Vector__XXX

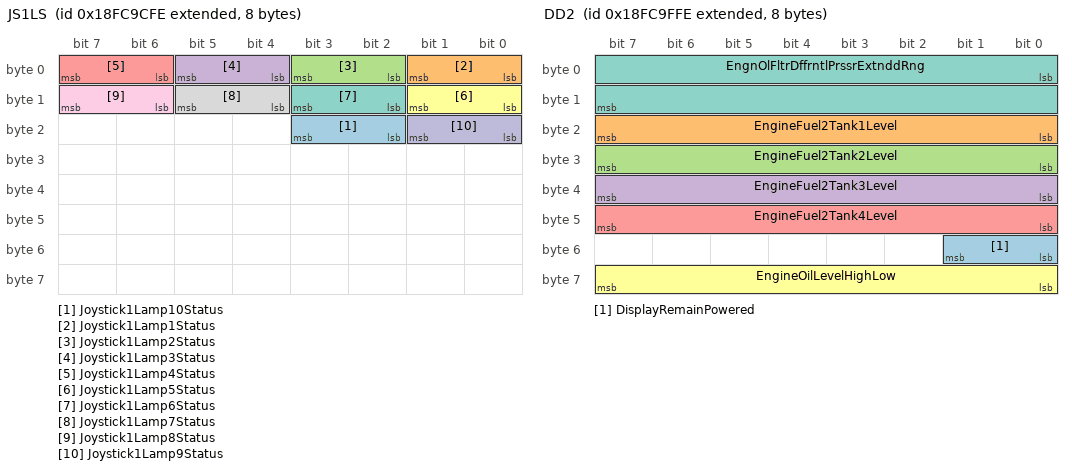
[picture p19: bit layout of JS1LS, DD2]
BO_ 2566692094 JS1LS: 8 Vector__XXX
 SG_ Joystick1Lamp10Status : 18|2@1+ (1,0) [0|3] "" Vector__XXX
 SG_ Joystick1Lamp1Status : 0|2@1+ (1,0) [0|3] "" Vector__XXX
 SG_ Joystick1Lamp2Status : 2|2@1+ (1,0) [0|3] "" Vector__XXX
 SG_ Joystick1Lamp3Status : 4|2@1+ (1,0) [0|3] "" Vector__XXX
 SG_ Joystick1Lamp4Status : 6|2@1+ (1,0) [0|3] "" Vector__XXX
 SG_ Joystick1Lamp5Status : 8|2@1+ (1,0) [0|3] "" Vector__XXX
 SG_ Joystick1Lamp6Status : 10|2@1+ (1,0) [0|3] "" Vector__XXX
 SG_ Joystick1Lamp7Status : 12|2@1+ (1,0) [0|3] "" Vector__XXX
 SG_ Joystick1Lamp8Status : 14|2@1+ (1,0) [0|3] "" Vector__XXX
 SG_ Joystick1Lamp9Status : 16|2@1+ (1,0) [0|3] "" Vector__XXX

BO_ 2566692862 DD2: 8 Vector__XXX
 SG_ DisplayRemainPowered : 48|2@1+ (1,0) [0|3] "" Vector__XXX
 SG_ EngineFuel2Tank1Level : 16|8@1+ (0.4,0) [0|100] "%" Vector__XXX
 SG_ EngineFuel2Tank2Level : 24|8@1+ (0.4,0) [0|100] "%" Vector__XXX
 SG_ EngineFuel2Tank3Level : 32|8@1+ (0.4,0) [0|100] "%" Vector__XXX
 SG_ EngineFuel2Tank4Level : 40|8@1+ (0.4,0) [0|100] "%" Vector__XXX
 SG_ EngineOilLevelHighLow : 56|8@1+ (0.5,-62.5) [-62.5|62.5] "l" Vector__XXX
 SG_ EngnOlFltrDffrntlPrssrExtnddRng : 0|16@1+ (0.0078125,-250) [-250|251.99] "kPa" Vector__XXX

BO_ 2566697470 ICMSTS: 8 Vector__XXX
 SG_ EngnIgntnCntrlMdl1Stt : 16|3@1+ (1,0) [0|7] "" Vector__XXX
 SG_ EngnIgntnCntrlMdl1Tmprtr : 0|8@1+ (1,-40) [-40|210] "degC" Vector__XXX
 SG_ EngnIgntnCntrlMdl2Stt : 19|3@1+ (1,0) [0|7] "" Vector__XXX
 SG_ EngnIgntnCntrlMdl2Tmprtr : 8|8@1+ (1,-40) [-40|210] "degC" Vector__XXX

BO_ 2566697726 SPOC1: 64 Vector__XXX
 SG_ SwitchedOutput10Current : 144|16@1+ (0.005,0) [0|321.275] "A" Vector__XXX
 SG_ SwitchedOutput11Current : 160|16@1+ (0.005,0) [0|321.275] "A" Vector__XXX
 SG_ SwitchedOutput12Current : 176|16@1+ (0.005,0) [0|321.275] "A" Vector__XXX
 SG_ SwitchedOutput13Current : 192|16@1+ (0.005,0) [0|321.275] "A" Vector__XXX
 SG_ SwitchedOutput14Current : 208|16@1+ (0.005,0) [0|321.275] "A" Vector__XXX
 SG_ SwitchedOutput15Current : 224|16@1+ (0.005,0) [0|321.275] "A" Vector__XXX
 SG_ SwitchedOutput16Current : 240|16@1+ (0.005,0) [0|321.275] "A" Vector__XXX
 SG_ SwitchedOutput17Current : 256|16@1+ (0.005,0) [0|321.275] "A" Vector__XXX
 SG_ SwitchedOutput18Current : 272|16@1+ (0.005,0) [0|321.275] "A" Vector__XXX
 SG_ SwitchedOutput19Current : 288|16@1+ (0.005,0) [0|321.275] "A" Vector__XXX
 SG_ SwitchedOutput1Current : 0|16@1+ (0.005,0) [0|321.275] "A" Vector__XXX
 SG_ SwitchedOutput20Current : 304|16@1+ (0.005,0) [0|321.275] "A" Vector__XXX
 SG_ SwitchedOutput21Current : 320|16@1+ (0.005,0) [0|321.275] "A" Vector__XXX
 SG_ SwitchedOutput22Current : 336|16@1+ (0.005,0) [0|321.275] "A" Vector__XXX
 SG_ SwitchedOutput23Current : 352|16@1+ (0.005,0) [0|321.275] "A" Vector__XXX
 SG_ SwitchedOutput24Current : 368|16@1+ (0.005,0) [0|321.275] "A" Vector__XXX
 SG_ SwitchedOutput25Current : 384|16@1+ (0.005,0) [0|321.275] "A" Vector__XXX
 SG_ SwitchedOutput26Current : 400|16@1+ (0.005,0) [0|321.275] "A" Vector__XXX
 SG_ SwitchedOutput27Current : 416|16@1+ (0.005,0) [0|321.275] "A" Vector__XXX
 SG_ SwitchedOutput28Current : 432|16@1+ (0.005,0) [0|321.275] "A" Vector__XXX
 SG_ SwitchedOutput29Current : 448|16@1+ (0.005,0) [0|321.275] "A" Vector__XXX
 SG_ SwitchedOutput2Current : 16|16@1+ (0.005,0) [0|321.275] "A" Vector__XXX
 SG_ SwitchedOutput30Current : 464|16@1+ (0.005,0) [0|321.275] "A" Vector__XXX
 SG_ SwitchedOutput31Current : 480|16@1+ (0.005,0) [0|321.275] "A" Vector__XXX
 SG_ SwitchedOutput32Current : 496|16@1+ (0.005,0) [0|321.275] "A" Vector__XXX
 SG_ SwitchedOutput3Current : 32|16@1+ (0.005,0) [0|321.275] "A" Vector__XXX
 SG_ SwitchedOutput4Current : 48|16@1+ (0.005,0) [0|321.275] "A" Vector__XXX
 SG_ SwitchedOutput5Current : 64|16@1+ (0.005,0) [0|321.275] "A" Vector__XXX
 SG_ SwitchedOutput6Current : 80|16@1+ (0.005,0) [0|321.275] "A" Vector__XXX
 SG_ SwitchedOutput7Current : 96|16@1+ (0.005,0) [0|321.275] "A" Vector__XXX
 SG_ SwitchedOutput8Current : 112|16@1+ (0.005,0) [0|321.275] "A" Vector__XXX
 SG_ SwitchedOutput9Current : 128|16@1+ (0.005,0) [0|321.275] "A" Vector__XXX

CM_ BO_ 2566642942 "Door Control 4";
CM_ SG_ 2566642942 EnableStatusofDoor21 "Enable status of bus door 21.  Enabled means the bus doors are able to be automatically opened or closed.00b = Door disabled01b = Door enabled10b = Error11b = N…";
CM_ SG_ 2566642942 EnableStatusofDoor22 "Enable status of bus door 22.  Enabled means the bus doors are able to be automatically opened or closed.00b = Door disabled01b = Door enabled10b = Error11b = N…";
CM_ SG_ 2566642942 EnableStatusofDoor23 "Enable status of bus door 23.  Enabled means the bus doors are able to be automatically opened or closed.00b = Door disabled01b = Door enabled10b = Error11b = N…";
CM_ SG_ 2566642942 EnableStatusofDoor24 "Enable status of bus door 24.  Enabled means the bus doors are able to be automatically opened or closed.00b = Door disabled01b = Door enabled10b = Error11b = N…";
CM_ SG_ 2566642942 EnableStatusofDoor25 "Enable status of bus door 25.  Enabled means the bus doors are able to be automatically opened or closed.00b = Door disabled01b = Door enabled10b = Error11b = N…";
CM_ SG_ 2566642942 EnableStatusofDoor26 "Enable status of bus door 26.  Enabled means the bus doors are able to be automatically opened or closed.00b = Door disabled01b = Door enabled10b = Error11b = N…";
CM_ SG_ 2566642942 EnableStatusofDoor27 "Enable status of bus door 27.  Enabled means the bus doors are able to be automatically opened or closed.00b = Door disabled01b = Door enabled10b = Error11b = N…";
CM_ SG_ 2566642942 EnableStatusofDoor28 "Enable status of bus door 28.  Enabled means the bus doors are able to be automatically opened or closed.00b = Door disabled01b = Door enabled10b = Error11b = N…";
CM_ SG_ 2566642942 EnableStatusofDoor29 "Enable status of bus door 29.  Enabled means the bus doors are able to be automatically opened or closed.00b = Door disabled01b = Door enabled10b = Error11b = N…";
CM_ SG_ 2566642942 EnableStatusofDoor30 "Enable status of bus door 30.  Enabled means the bus doors are able to be automatically opened or closed.00b = Door disabled01b = Door enabled10b = Error11b = N…";
CM_ SG_ 2566642942 LockStatusofDoor21 "Lock status of bus door 2100b = Unlocked01b = Locked10b = Error11b = Not available…";
CM_ SG_ 2566642942 LockStatusofDoor22 "Lock status of bus door 2200b = Unlocked01b = Locked10b = Error11b = Not available…";
CM_ SG_ 2566642942 LockStatusofDoor23 "Lock status of bus door 2300b = Unlocked01b = Locked10b = Error11b = Not available…";
CM_ SG_ 2566642942 LockStatusofDoor24 "Lock status of bus door 2400b = Unlocked01b = Locked10b = Error11b = Not available…";
CM_ SG_ 2566642942 LockStatusofDoor25 "Lock status of bus door 2500b = Unlocked01b = Locked10b = Error11b = Not available…";
CM_ SG_ 2566642942 LockStatusofDoor26 "Lock status of bus door 2600b = Unlocked01b = Locked10b = Error11b = Not available…";
CM_ SG_ 2566642942 LockStatusofDoor27 "Lock status of bus door 2700b = Unlocked01b = Locked10b = Error11b = Not available…";
CM_ SG_ 2566642942 LockStatusofDoor28 "Lock status of bus door 2800b = Unlocked01b = Locked10b = Error11b = Not available…";
CM_ SG_ 2566642942 LockStatusofDoor29 "Lock status of bus door 2900b = Unlocked01b = Locked10b = Error11b = Not available…";
CM_ SG_ 2566642942 LockStatusofDoor30 "Lock status of bus door 3000b = Unlocked01b = Locked10b = Error11b = Not available…";
CM_ SG_ 2566642942 OpenStatusofDoor21 "Open status of bus door 2100b = Door closed01b = Door opened10b = Error11b = Not available…";
CM_ SG_ 2566642942 OpenStatusofDoor22 "Open status of bus door 2200b = Door closed01b = Door opened10b = Error11b = Not available…";
CM_ SG_ 2566642942 OpenStatusofDoor23 "Open status of bus door 2300b = Door closed01b = Door opened10b = Error11b = Not available…";
CM_ SG_ 2566642942 OpenStatusofDoor24 "Open status of bus door 2400b = Door closed01b = Door opened10b = Error11b = Not available…";
CM_ SG_ 2566642942 OpenStatusofDoor25 "Open status of bus door 2500b = Door closed01b = Door opened10b = Error11b = Not available…";
CM_ SG_ 2566642942 OpenStatusofDoor26 "Open status of bus door 2600b = Door closed01b = Door opened10b = Error11b = Not available…";
CM_ SG_ 2566642942 OpenStatusofDoor27 "Open status of bus door 2700b = Door closed01b = Door opened10b = Error11b = Not available…";
CM_ SG_ 2566642942 OpenStatusofDoor28 "Open status of bus door 2800b = Door closed01b = Door opened10b = Error11b = Not available…";
CM_ SG_ 2566642942 OpenStatusofDoor29 "Open status of bus door 2900b = Door closed01b = Door opened10b = Error11b = Not available…";
CM_ SG_ 2566642942 OpenStatusofDoor30 "Open status of bus door 3000b = Door closed01b = Door opened10b = Error11b = Not available…";
CM_ BO_ 2566643198 "Door Control 3";
CM_ SG_ 2566643198 EnableStatusofDoor11 "Enable status of bus door 11.  Enabled means the bus doors are able to be automatically opened or closed.00b = Door disabled01b = Door enabled10b = Error11b = N…";
CM_ SG_ 2566643198 EnableStatusofDoor12 "Enable status of bus door 12.  Enabled means the bus doors are able to be automatically opened or closed.00b = Door disabled01b = Door enabled10b = Error11b = N…";
CM_ SG_ 2566643198 EnableStatusofDoor13 "Enable status of bus door 13.  Enabled means the bus doors are able to be automatically opened or closed.00b = Door disabled01b = Door enabled10b = Error11b = N…";
CM_ SG_ 2566643198 EnableStatusofDoor14 "Enable status of bus door 14.  Enabled means the bus doors are able to be automatically opened or closed.00b = Door disabled01b = Door enabled10b = Error11b = N…";
CM_ SG_ 2566643198 EnableStatusofDoor15 "Enable status of bus door 15.  Enabled means the bus doors are able to be automatically opened or closed.00b = Door disabled01b = Door enabled10b = Error11b = N…";
CM_ SG_ 2566643198 EnableStatusofDoor16 "Enable status of bus door 16.  Enabled means the bus doors are able to be automatically opened or closed.00b = Door disabled01b = Door enabled10b = Error11b = N…";
CM_ SG_ 2566643198 EnableStatusofDoor17 "Enable status of bus door 17.  Enabled means the bus doors are able to be automatically opened or closed.00b = Door disabled01b = Door enabled10b = Error11b = N…";
CM_ SG_ 2566643198 EnableStatusofDoor18 "Enable status of bus door 18.  Enabled means the bus doors are able to be automatically opened or closed.00b = Door disabled01b = Door enabled10b = Error11b = N…";
CM_ SG_ 2566643198 EnableStatusofDoor19 "Enable status of bus door 19.  Enabled means the bus doors are able to be automatically opened or closed.00b = Door disabled01b = Door enabled10b = Error11b = N…";
CM_ SG_ 2566643198 EnableStatusofDoor20 "Enable status of bus door 20.  Enabled means the bus doors are able to be automatically opened or closed.00b = Door disabled01b = Door enabled10b = Error11b = N…";
CM_ SG_ 2566643198 LockStatusofDoor11 "Lock status of bus door 1100b = Unlocked 01b = Locked10b = Error11b = Not available…";
CM_ SG_ 2566643198 LockStatusofDoor12 "Lock status of bus door 1200b = Unlocked01b = Locked10b = Error11b = Not available…";
CM_ SG_ 2566643198 LockStatusofDoor13 "Lock status of bus door 1300b = Unlocked01b = Locked10b = Error11b = Not available…";
CM_ SG_ 2566643198 LockStatusofDoor14 "Lock status of bus door 1400b = Unlocked01b = Locked10b = Error11b = Not available…";
CM_ SG_ 2566643198 LockStatusofDoor15 "Lock status of bus door 1500b = Unlocked01b = Locked10b = Error11b = Not available…";
CM_ SG_ 2566643198 LockStatusofDoor16 "Lock status of bus door 1600b = Unlocked01b = Locked10b = Error11b = Not available…";
CM_ SG_ 2566643198 LockStatusofDoor17 "Lock status of bus door 1700b = Unlocked01b = Locked10b = Error11b = Not available…";
CM_ SG_ 2566643198 LockStatusofDoor18 "Lock status of bus door 1800b = Unlocked01b = Locked10b = Error11b = Not available…";
CM_ SG_ 2566643198 LockStatusofDoor19 "Lock status of bus door 1900b = Unlocked01b = Locked10b = Error11b = Not available…";
CM_ SG_ 2566643198 LockStatusofDoor20 "Lock status of bus door 2000b = Unlocked01b = Locked10b = Error11b = Not available…";
CM_ SG_ 2566643198 OpenStatusofDoor11 "Open status of bus door 1100b = Door closed01b = Door opened10b = Error11b = Not available…";
CM_ SG_ 2566643198 OpenStatusofDoor12 "Open status of bus door 1200b = Door closed01b = Door opened10b = Error11b = Not available…";
CM_ SG_ 2566643198 OpenStatusofDoor13 "Open status of bus door 1300b = Door closed01b = Door opened10b = Error11b = Not available…";
CM_ SG_ 2566643198 OpenStatusofDoor14 "Open status of bus door 1400b = Door closed01b = Door opened10b = Error11b = Not available…";
CM_ SG_ 2566643198 OpenStatusofDoor15 "Open status of bus door 1500b = Door closed01b = Door opened10b = Error11b = Not available…";
CM_ SG_ 2566643198 OpenStatusofDoor16 "Open status of bus door 1600b = Door closed01b = Door opened10b = Error11b = Not available…";
CM_ SG_ 2566643198 OpenStatusofDoor17 "Open status of bus door 1700b = Door closed01b = Door opened10b = Error11b = Not available…";
CM_ SG_ 2566643198 OpenStatusofDoor18 "Open status of bus door 1800b = Door closed01b = Door opened10b = Error11b = Not available…";
CM_ SG_ 2566643198 OpenStatusofDoor19 "Open status of bus door 1900b = Door closed01b = Door opened10b = Error11b = Not available…";
CM_ SG_ 2566643198 OpenStatusofDoor20 "Open status of bus door 2000b = Door closed01b = Door opened10b = Error11b = Not available…";
CM_ BO_ 2566643454 "Engine Temperature 6";
CM_ SG_ 2566643454 EngineIntakeCoolantTemperature "Temperature of the coolant at the intake of the engine block.…";
CM_ SG_ 2566643454 EngnChrgArClrIntkClntTmprtr "Temperature of the fluid in the low temperature circuit measured at the fluid intake of the charge air cooler.…";
CM_ SG_ 2566643454 EngnChrgArClrOtltClntTmprtr "Temperature of the fluid in the low temperature circuit measured at the fluid outlet of the charge air cooler.…";
CM_ BO_ 2566643710 "Intake/Exhaust Conditions 3";
CM_ SG_ 2566643710 EngineMixer1IntakePressure "The pressure at the intake of the air and fuel mixer.…";
CM_ SG_ 2566643710 EngineMixer2IntakePressure "The pressure at the intake of the second air and fuel mixer.…";
CM_ BO_ 2566644990 "Fuel Information 7 (Gaseous)";
CM_ SG_ 2566644990 DrvrSdFlRptl1CvrStts "Indicates if the cover for the first fuel receptacle on the driver side is attached or detached.00b = Receptacle cover is detached01b = Receptacle cover is atta…";
CM_ SG_ 2566644990 DrvrSdFlRptl2CvrStts "Indicates if the cover for the second fuel receptacle on the driver side is attached or detached.00b = Receptacle cover is detached01b = Receptacle cover is att…";
CM_ SG_ 2566644990 FlStrgCmprtmnt1Tmprtr1 "The ambient temperature in the first fuel storage compartment.  If there is more than 1 sensor, then this is the first sensor. Note that this is not the tempera…";
CM_ SG_ 2566644990 FlStrgCmprtmnt1Tmprtr2 "The ambient temperature as measured by the second temperature sensor in the first fuel storage compartment. Note that this is not the temperature of the fuel in…";
CM_ SG_ 2566644990 FlStrgCmprtmnt2Tmprtr1 "The ambient temperature in the second fuel storage compartment.  If there is more than 1 sensor, then this is the first sensor. Note that this is not the temper…";
CM_ SG_ 2566644990 FlStrgCmprtmnt2Tmprtr2 "The ambient temperature as measured by the second temperature sensor in the second fuel storage compartment. Note that this is not the temperature of the fuel i…";
CM_ SG_ 2566644990 FlStrgCmprtmnt3Tmprtr1 "The ambient temperature in the third fuel storage compartment.  If there is more than 1 sensor, then this is the first sensor. Note that this is not the tempera…";
CM_ SG_ 2566644990 FlStrgCmprtmnt3Tmprtr2 "The ambient temperature as measured by the second temperature sensor in the third fuel storage compartment. Note that this is not the temperature of the fuel in…";
CM_ SG_ 2566644990 FrontFuelReceptacleCoverStatus "Indicates if the cover for the fuel receptacle at the front of the vehicle is attached or detached.00b = Receptacle cover is detached01b = Receptacle cover is a…";
CM_ SG_ 2566644990 PssngrSdFlRptl1CvrStts "Indicates if the cover for the first fuel receptacle on the passenger side is attached or detached.00b = Receptacle cover is detached01b = Receptacle cover is a…";
CM_ SG_ 2566644990 PssngrSdFlRptl2CvrStts "Indicates if the cover for the second fuel receptacle on the passenger side is attached or detached.00b = Receptacle cover is detached01b = Receptacle cover is …";
CM_ BO_ 2566645246 "High Voltage Energy Storage Fan Status";
CM_ SG_ 2566645246 HVESFanCommandStatus "Indicates the source of the speed command to this HVES fan.00b is communicated when the fan is self-controlled (e.g. based on a temperature sensor).  01b is com…";
CM_ SG_ 2566645246 HVESFanEnableStatus "Enable and direction status of this HVES fan.00b = Fan Off01b = Fan On - Normal, Forward, or Default Direction10b = Fan On - Reverse Direction11b = Not availabl…";
CM_ SG_ 2566645246 HVESFanInstance "Indicates the instance of the HVES fan that is providing status in systems controlled by a master ECU.0000b = Instance 10001b = Instance 20010b = Instance 30011…";
CM_ SG_ 2566645246 HVESFanMediumTemperature "A temperature measured and reported by the device.  It may be used for direct or remote (e.g. by another controller) control of the pump.  For example, this may…";
CM_ SG_ 2566645246 HVESFanOperatingStatus "Indicates the operating status of this HVES fan.  This parameter is used to inform other devices that this system or component is no longer performing to its op…";
CM_ SG_ 2566645246 HVESFanPower "Calculated electrical power consumed by this HVES fan.…";
CM_ SG_ 2566645246 HVESFanServiceIndicator "Indicates that service is required for this HVES fan.  An active indication may convey a need for component replacement or periodic service.  The HVES Fan Statu…";
CM_ SG_ 2566645246 HVESFanSpeed "Speed of this HVES fan. …";
CM_ SG_ 2566645246 HVESFanStatusReasonCode "Provides the reason code describing the unique failure of this HVES fan.  If a detailed reason code is not used by the supporting application, or this reason co…";
CM_ BO_ 2566646782 "Oil Debris Monitor Counts Ferrous Bins 1 & 2";
CM_ SG_ 2566646782 OlDrsMntrFrrsBn1Cnt "Total number of particles detected in Ferrous bin 1. Bin sizes are application specific.…";
CM_ SG_ 2566646782 OlDrsMntrFrrsBn2Cnt "Total number of particles detected in Ferrous bin 2. Bin sizes are application specific.…";
CM_ SG_ 2566646782 OlDrsMntrFrrsBns1nd2IdntftnNmr "Identification number of the Oil Debris Monitoring (ODM) sensor being reported for Ferrous bins 1 and 2. Identification numbers are application specific.…";
CM_ BO_ 2566647038 "Oil Debris Monitor Counts Ferrous Bins 3 & 4";
CM_ SG_ 2566647038 OlDrsMntrFrrsBn3Cnt "Total number of particles detected in Ferrous bin 3. Bin sizes are application specific.…";
CM_ SG_ 2566647038 OlDrsMntrFrrsBn4Cnt "Total number of particles detected in Ferrous bin 4. Bin sizes are application specific.…";
CM_ SG_ 2566647038 OlDrsMntrFrrsBns3nd4IdntftnNmr "Identification number of the Oil Debris Monitoring (ODM) sensor being reported for Ferrous bins 3 and 4. Identification numbers are application specific.…";
CM_ BO_ 2566647294 "Oil Debris Monitor Counts Ferrous Bins 5 & 6";
CM_ SG_ 2566647294 OlDrsMntrFrrsBn5Cnt "Total number of particles detected in Ferrous bin 5. Bin sizes are application specific.…";
CM_ SG_ 2566647294 OlDrsMntrFrrsBn6Cnt "Total number of particles detected in Ferrous bin 6. Bin sizes are application specific.…";
CM_ SG_ 2566647294 OlDrsMntrFrrsBns5nd6IdntftnNmr "Identification number of the Oil Debris Monitoring (ODM) sensor being reported for Ferrous bins 5 and 6. Identification numbers are application specific.…";
CM_ BO_ 2566647550 "Oil Debris Monitor Counts Non-Ferrous Bins 1 & 2";
CM_ SG_ 2566647550 ODsMtNFsBs1d2IdttN "Identification number of the Oil Debris Monitoring (ODM) sensor being reported for Non-Ferrous bins 1 and 2.  Identification numbers are application specific.…";
CM_ SG_ 2566647550 OlDrsMntrNnFrrsBn1Cnt "Total number of particles detected in Non-Ferrous bin 1. Bin sizes are application specific.…";
CM_ SG_ 2566647550 OlDrsMntrNnFrrsBn2Cnt "Total number of particles detected in Non-Ferrous bin 2. Bin sizes are application specific.…";
CM_ BO_ 2566647806 "Oil Debris Monitor Counts Non-Ferrous Bins 3 & 4";
CM_ SG_ 2566647806 ODsMtNFsBs3d4IdttN "Identification number of the Oil Debris Monitoring (ODM) sensor being reported for Non-Ferrous bins 3 and 4. Identification numbers are application specific.…";
CM_ SG_ 2566647806 OlDrsMntrNnFrrsBn3Cnt "Total number of particles detected in Non-Ferrous bin 3. Bin sizes are application specific.…";
CM_ SG_ 2566647806 OlDrsMntrNnFrrsBn4Cnt "Total number of particles detected in Non-Ferrous bin 4. Bin sizes are application specific.…";
CM_ BO_ 2566648062 "Oil Debris Monitor Counts Non-Ferrous Bins 5 & 6";
CM_ SG_ 2566648062 ODsMtNFsBs5d6IdttN "Identification number of the Oil Debris Monitoring (ODM) sensor being reported for Non-Ferrous bins 5 and 6. Identification numbers are application specific.…";
CM_ SG_ 2566648062 OlDrsMntrNnFrrsBn5Cnt "Total number of particles detected in Non-Ferrous bin 5. Bin sizes are application specific.…";
CM_ SG_ 2566648062 OlDrsMntrNnFrrsBn6Cnt "Total number of particles detected in Non-Ferrous bin 6. Bin sizes are application specific.…";
CM_ BO_ 2566648318 "Oil Debris Monitoring System Status";
CM_ SG_ 2566648318 OlDrsMntrEltrnsTmprtrStts "Temperature indicator for the Oil Debris Monitor (ODM) Electronics.00b = Acceptable temperature01b = Temperature is outside of limits10b = Reserved11b = Not ava…";
CM_ SG_ 2566648318 OlDrsMntrEnvrnmntStts "Status of the electrical and mechanical environment surrounding the Oil Debris Monitor (ODM) Sensor.00b = Acceptable environment01b = Excessive noise in signal1…";
CM_ SG_ 2566648318 OlDrsMntrSgnlPrssngEltrnsStts "Status of the Oil Debris Monitor (ODM) signal processing electronics.00b = Electronics functioning normally01b = Fault in electronics10b = Reserved11b = Not ava…";
CM_ SG_ 2566648318 OlDrsMntrSnsngElmntStts "Status of the Oil Debris Monitor (ODM) sensing element.00b = Sensing element OK01b = Fault with sensing element10b = Reserved11b = Not available…";
CM_ SG_ 2566648318 OlDrsMntrSttsIdntftnNmr "Identification number of the Oil Debris Monitoring (ODM) sensor being reported. Identification numbers are application specific.…";
CM_ SG_ 2566648318 OlDrsMntrTtlnmrfSnsrs "Total number of Oil Debris Monitoring (ODM) sensors configured for this application.…";
CM_ BO_ 2566649086 "Aftertreatment 2 Diesel Oxidation Catalyst 2";
CM_ SG_ 2566649086 Atttt2DOCIttDPFOttDtPss "Aftertreatment 2 Diesel Oxidation Catalyst intake to Diesel Particulate Filter outlet differential pressure in exhaust bank 1.…";
CM_ SG_ 2566649086 Atttt2DsOxdtCtstItPss "Aftertreatment 2 Diesel Oxidation Catalyst absolute pressure measured at the DOC intake in exhaust bank 1.…";
CM_ SG_ 2566649086 Atttt2DsOxdtCtstOttPss "Aftertreatment 2 Diesel Oxidation Catalyst absolute pressure measured at the DOC outlet in exhaust bank 1.…";
CM_ BO_ 2566649342 "Aftertreatment 1 Diesel Oxidation Catalyst 2";
CM_ SG_ 2566649342 Atttt1DOCIttDPFOttDtPss "Aftertreatment 1 Diesel Oxidation Catalyst intake to Diesel Particulate Filter outlet differential pressure in exhaust bank 1.…";
CM_ SG_ 2566649342 Atttt1DsOxdtCtstItPss "Aftertreatment 1 Diesel Oxidation Catalyst absolute pressure measured at the DOC intake in exhaust bank 1.…";
CM_ SG_ 2566649342 Atttt1DsOxdtCtstOttPss "Aftertreatment 1 Diesel Oxidation Catalyst absolute pressure measured at the DOC outlet in exhaust bank 1.…";
CM_ BO_ 2566649598 "Vehicle Position 2";
CM_ SG_ 2566649598 HorizontalDilutionofPrecision "Provides the dilution of precision in the horizontal (X-Y plane axis) direction as calculated by the positioning and locating system receiver. The dilution of p…";
CM_ SG_ 2566649598 PositionDilutionofPrecision "Provides the dilution of precision for the overall position (X-Y-Z coordinate system) as calculated by the positioning and locating system receiver. The dilutio…";
CM_ SG_ 2566649598 TimeDilutionofPrecision "Provides the estimated receiver clock error as calculated by the positioning and locating system receiver from the satellites’ clock data. The dilution of preci…";
CM_ SG_ 2566649598 TotalNumberofSatellitesinView "Indicates the number of satellites in view of the positioning and locating system receiver.…";
CM_ SG_ 2566649598 VerticalDilutionofPrecision "Provides the dilution of precision in the vertical (Z axis) direction as calculated by the positioning and locating system receiver. The dilution of precision f…";
CM_ BO_ 2566649854 "Electrified Accessory Propulsion Motor Coolant Fan 3 Status";
CM_ SG_ 2566649854 PpsMtCtF3CtCdStts "Indicates the source of the speed command to the Propulsion Motor Coolant Fan 3 system or component.00b is communicated when the controller is self-controlled  …";
CM_ SG_ 2566649854 PpsMtCtF3CtSttsRsCd "Provides the reason code describing the unique failure of the Propulsion Motor Coolant Fan 3 system or component.If a detailed reason code is not used by the su…";
CM_ SG_ 2566649854 PropulsionMotorCoolantFan3Power "Calculated electrical power consumed by the Propulsion Motor Coolant Fan 3.…";
CM_ SG_ 2566649854 PrplsnMtrClntFn3CntrlTmprtr "A temperature measured and reported by the device.  It may be used for direct or remote (by another controller) control of the Fan 3.  For example, this may be …";
CM_ SG_ 2566649854 PrplsnMtrClntFn3EnlStts "Enable and direction status of the Propulsion Motor Coolant Fan 3 system or component.00b = Accessory Motor Off01b = Accessory Motor On - Normal, Forward, or De…";
CM_ SG_ 2566649854 PrplsnMtrClntFn3MtrSpd "Motor Speed of the Propulsion Motor Coolant Fan 3. …";
CM_ SG_ 2566649854 PrplsnMtrClntFn3OprtngStts "Indicates the operating status of the Propulsion Motor Coolant Fan 3 system or component.This parameter is used to inform other devices that this system or comp…";
CM_ SG_ 2566649854 PrplsnMtrClntFn3SrvIndtr "Indicates that service is required for the Propulsion Motor Coolant Fan 3 system or component.An active indication may convey a need for component replacement o…";
CM_ BO_ 2566650110 "Electrified Accessory Propulsion Motor Coolant Fan 2 Status";
CM_ SG_ 2566650110 PpsMtCtF2CtCdStts "Indicates the source of the speed command to the Propulsion Motor Coolant Fan 2 system or component.00b is communicated when the controller is self-controlled  …";
CM_ SG_ 2566650110 PpsMtCtF2CtSttsRsCd "Provides the reason code describing the unique failure of the Propulsion Motor Coolant Fan 2 system or component.If a detailed reason code is not used by the su…";
CM_ SG_ 2566650110 PropulsionMotorCoolantFan2Power "Calculated electrical power consumed by the Propulsion Motor Coolant Fan 2.…";
CM_ SG_ 2566650110 PrplsnMtrClntFn2CntrlTmprtr "A temperature measured and reported by the device.  It may be used for direct or remote (by another controller) control of the Fan 2.  For example, this may be …";
CM_ SG_ 2566650110 PrplsnMtrClntFn2EnlStts "Enable and direction status of the Propulsion Motor Coolant Fan 2 system or component.00b = Accessory Motor Off01b = Accessory Motor On - Normal, Forward, or De…";
CM_ SG_ 2566650110 PrplsnMtrClntFn2MtrSpd "Motor Speed of the Propulsion Motor Coolant Fan 2. …";
CM_ SG_ 2566650110 PrplsnMtrClntFn2OprtngStts "Indicates the operating status of the Propulsion Motor Coolant Fan 2 system or component.This parameter is used to inform other devices that this system or comp…";
CM_ SG_ 2566650110 PrplsnMtrClntFn2SrvIndtr "Indicates that service is required for the Propulsion Motor Coolant Fan 2 system or component.An active indication may convey a need for component replacement o…";
CM_ BO_ 2566650366 "Electrified Accessory Propulsion Motor Coolant Fan 1 Status";
CM_ SG_ 2566650366 PpsMtCtF1CtCdStts "Indicates the source of the speed command to the Propulsion Motor Coolant Fan 1 system or component.00b is communicated when the controller is self-controlled  …";
CM_ SG_ 2566650366 PpsMtCtF1CtSttsRsCd "Provides the reason code describing the unique failure of the Propulsion Motor Coolant Fan 1 system or component.If a detailed reason code is not used by the su…";
CM_ SG_ 2566650366 PropulsionMotorCoolantFan1Power "Calculated electrical power consumed by the Propulsion Motor Coolant Fan 1.…";
CM_ SG_ 2566650366 PrplsnMtrClntFn1CntrlTmprtr "A temperature measured and reported by the device.  It may be used for direct or remote (by another controller) control of the Fan 1.  For example, this may be …";
CM_ SG_ 2566650366 PrplsnMtrClntFn1EnlStts "Enable and direction status of the Propulsion Motor Coolant Fan 1 system or component.00b = Accessory Motor Off01b = Accessory Motor On - Normal, Forward, or De…";
CM_ SG_ 2566650366 PrplsnMtrClntFn1MtrSpd "Motor Speed of the Propulsion Motor Coolant Fan 1. …";
CM_ SG_ 2566650366 PrplsnMtrClntFn1OprtngStts "Indicates the operating status of the Propulsion Motor Coolant Fan 1 system or component.This parameter is used to inform other devices that this system or comp…";
CM_ SG_ 2566650366 PrplsnMtrClntFn1SrvIndtr "Indicates that service is required for the Propulsion Motor Coolant Fan 1 system or component.An active indication may convey a need for component replacement o…";
CM_ BO_ 2566650622 "Electrified Accessory Power Electronics Coolant Fan 3 Status";
CM_ SG_ 2566650622 PwEtsCtF3CtCdStts "Indicates the source of the speed command to the Power Electronics Coolant Fan 3 system or component.00b is communicated when the controller is self-controlled …";
CM_ SG_ 2566650622 PwEtsCtF3CtSttsRsCd "Provides the reason code describing the unique failure of the Power Electronics Coolant Fan 3 system or component.  If a detailed reason code is not used by the…";
CM_ SG_ 2566650622 PwrEltrnsClntFn3CntrlTmprtr "A temperature measured and reported by the device.  It may be used for direct or remote (by another controller) control of the Fan 3.  For example, this may be …";
CM_ SG_ 2566650622 PwrEltrnsClntFn3EnlStts "Enable and direction status of the Power Electronics Coolant Fan 3 system or component.00b = Accessory Motor Off01b = Accessory Motor On - Normal, Forward, or D…";
CM_ SG_ 2566650622 PwrEltrnsClntFn3MtrSpd "Motor Speed of the Power Electronics Coolant Fan 3. …";
CM_ SG_ 2566650622 PwrEltrnsClntFn3OprtngStts "Indicates the operating status of the Power Electronics Coolant Fan 3 system or component.This parameter is used to inform other devices that this system or com…";
CM_ SG_ 2566650622 PwrEltrnsClntFn3Pwr "Calculated electrical power consumed by the Power Electronics Coolant Fan 3.…";
CM_ SG_ 2566650622 PwrEltrnsClntFn3SrvIndtr "Indicates that service is required for the Power Electronics Coolant Fan 3 system or component.An active indication may convey a need for component replacement …";
CM_ BO_ 2566650878 "Electrified Accessory Power Electronics Coolant Fan 2 Status";
CM_ SG_ 2566650878 PwEtsCtF2CtCdStts "Indicates the source of the speed command to the Power Electronics Coolant Fan 2 system or component.00b is communicated when the controller is self-controlled …";
CM_ SG_ 2566650878 PwEtsCtF2CtSttsRsCd "Provides the reason code describing the unique failure of the Power Electronics Coolant Fan 2 system or component.If a detailed reason code is not used by the s…";
CM_ SG_ 2566650878 PwrEltrnsClntFn2CntrlTmprtr "A temperature measured and reported by the device.  It may be used for direct or remote (by another controller) control of the Fan 2.  For example, this may be …";
CM_ SG_ 2566650878 PwrEltrnsClntFn2EnlStts "Enable and direction status of the Power Electronics Coolant Fan 2 system or component.00b = Accessory Motor Off01b = Accessory Motor On - Normal, Forward, or D…";
CM_ SG_ 2566650878 PwrEltrnsClntFn2MtrSpd "Motor Speed of the Power Electronics Coolant Fan 2. …";
CM_ SG_ 2566650878 PwrEltrnsClntFn2OprtngStts "Indicates the operating status of the Power Electronics Coolant Fan 2 system or component.This parameter is used to inform other devices that this system or com…";
CM_ SG_ 2566650878 PwrEltrnsClntFn2Pwr "Calculated electrical power consumed by the Power Electronics Coolant Fan 2.…";
CM_ SG_ 2566650878 PwrEltrnsClntFn2SrvIndtr "Indicates that service is required for the Power Electronics Coolant Fan 2 system or component.An active indication may convey a need for component replacement …";
CM_ BO_ 2566651134 "Electrified Accessory Power Electronics Coolant Fan 1 Status";
CM_ SG_ 2566651134 PwEtsCtF1CtCdStts "Indicates the source of the speed command to the Power Electronics Coolant Fan 1 system or component.00b is communicated when the controller is self-controlled …";
CM_ SG_ 2566651134 PwEtsCtF1CtSttsRsCd "Provides the reason code describing the unique failure of the Power Electronics Coolant Fan 1 system or component.If a detailed reason code is not used by the s…";
CM_ SG_ 2566651134 PwrEltrnsClntFn1CntrlTmprtr "A temperature measured and reported by the device.  It may be used for direct or remote (by another controller) control of the Fan 1.  For example, this may be …";
CM_ SG_ 2566651134 PwrEltrnsClntFn1EnlStts "Enable and direction status of the Power Electronics Coolant Fan 1 system or component.00b = Accessory Motor Off01b = Accessory Motor On - Normal, Forward, or D…";
CM_ SG_ 2566651134 PwrEltrnsClntFn1MtrSpd "Motor Speed of the Power Electronics Coolant Fan 1. …";
CM_ SG_ 2566651134 PwrEltrnsClntFn1OprtngStts "Indicates the operating status of the Power Electronics Coolant Fan 1 system or component.This parameter is used to inform other devices that this system or com…";
CM_ SG_ 2566651134 PwrEltrnsClntFn1Pwr "Calculated electrical power consumed by the Power Electronics Coolant Fan 1.…";
CM_ SG_ 2566651134 PwrEltrnsClntFn1SrvIndtr "Indicates that service is required for the Power Electronics Coolant Fan 1 system or component.An active indication may convey a need for component replacement …";
CM_ BO_ 2566651390 "Electrified Accessory Propulsion Motor Oil Pump Status";
CM_ SG_ 2566651390 PropulsionMotorOilPumpPower "Calculated electrical power consumed by the Propulsion Motor Oil Pump.…";
CM_ SG_ 2566651390 PrplsnMtrOlPmpCntrllrCmmndStts "Indicates the source of the speed command to the Propulsion Motor Oil Pump system or component.00b is communicated when the controller is self-controlled  (e.g.…";
CM_ SG_ 2566651390 PrplsnMtrOlPmpCntrllrSttsRsnCd "Provides the reason code describing the unique failure of the Propulsion Motor Oil Pump system or component.If a detailed reason code is not used by the support…";
CM_ SG_ 2566651390 PrplsnMtrOlPmpCntrlTmprtr "A temperature measured and reported by the device.  It may be used for direct or remote (e.g. by another controller) control of the pump.  For example, this may…";
CM_ SG_ 2566651390 PrplsnMtrOlPmpEnlStts "Enable and direction status of the Propulsion Motor Oil Pump system or component.00b = Accessory Motor Off01b = Accessory Motor On - Normal, Forward, or Default…";
CM_ SG_ 2566651390 PrplsnMtrOlPmpMtrSpd "Motor Speed of the Propulsion Motor Oil Pump. …";
CM_ SG_ 2566651390 PrplsnMtrOlPmpOprtngStts "Indicates the operating status of the Propulsion Motor Oil Pump system or component.This parameter is used to inform other devices that this system or component…";
CM_ SG_ 2566651390 PrplsnMtrOlPmpSrvIndtr "Indicates that service is required for the Propulsion Motor Oil Pump system or component.An active indication may convey a need for component replacement or per…";
CM_ BO_ 2566651646 "Electrified Accessory Propulsion Motor Coolant Pump Status";
CM_ SG_ 2566651646 PpsMtCtPpCtCdStts "Indicates the source of the speed command to the Propulsion Motor Coolant Pump system or component.00b is communicated when the controller is self-controlled  (…";
CM_ SG_ 2566651646 PpsMtCtPpCtSttsRsCd "Provides the reason code describing the unique failure of the Propulsion Motor Coolant Pump system or component.If a detailed reason code is not used by the sup…";
CM_ SG_ 2566651646 PropulsionMotorCoolantPumpPower "Calculated electrical power consumed by the Propulsion Motor Coolant Pump.…";
CM_ SG_ 2566651646 PrplsnMtrClntPmpCntrlTmprtr "A temperature measured and reported by the device.  It may be used for direct or remote (e.g. by another controller) control of the pump.  For example, this may…";
CM_ SG_ 2566651646 PrplsnMtrClntPmpEnlStts "Enable and direction status of the Propulsion Motor Coolant Pump system or component.00b = Accessory Motor Off01b = Accessory Motor On - Normal, Forward, or Def…";
CM_ SG_ 2566651646 PrplsnMtrClntPmpMtrSpd "Motor Speed of the Propulsion Motor Coolant Pump. …";
CM_ SG_ 2566651646 PrplsnMtrClntPmpOprtngStts "Indicates the operating status of the Propulsion Motor Coolant Pump system or component.This parameter is used to inform other devices that this system or compo…";
CM_ SG_ 2566651646 PrplsnMtrClntPmpSrvIndtr "Indicates that service is required for the Propulsion Motor Coolant Pump system or component.An active indication may convey a need for component replacement or…";
CM_ BO_ 2566651902 "Electrified Accessory Power Electronics Coolant Pump Status";
CM_ SG_ 2566651902 PwEtsCtPpCtCdStts "Indicates the source of the speed command to the Power Electronics Coolant Pump system or component.00b is communicated when the controller is self-controlled  …";
CM_ SG_ 2566651902 PwEtsCtPpCtSttsRsCd "Provides the reason code describing the unique failure of the Power Electronics Coolant Pump system or component.If a detailed reason code is not used by the su…";
CM_ SG_ 2566651902 PwrEltrnsClntPmpCntrlTmprtr "A temperature measured and reported by the device.  It may be used for direct or remote (e.g. by another controller) control of the pump.  For example, this may…";
CM_ SG_ 2566651902 PwrEltrnsClntPmpEnlStts "Enable and direction status of the Power Electronics Coolant Pump system or component.00b = Accessory Motor Off01b = Accessory Motor On - Normal, Forward, or De…";
CM_ SG_ 2566651902 PwrEltrnsClntPmpMtrSpd "Motor Speed of the Power Electronics Coolant Pump. …";
CM_ SG_ 2566651902 PwrEltrnsClntPmpOprtngStts "Indicates the operating status of the Power Electronics Coolant Pump system or component.This parameter is used to inform other devices that this system or comp…";
CM_ SG_ 2566651902 PwrEltrnsClntPmpPwr "Calculated electrical power consumed by the Power Electronics Coolant Pump.…";
CM_ SG_ 2566651902 PwrEltrnsClntPmpSrvIndtr "Indicates that service is required for the Power Electronics Coolant Pump system or component.An active indication may convey a need for component replacement o…";
CM_ BO_ 2566652414 "Electrified Accessory Motor Status";
CM_ SG_ 2566652414 ElectrifiedAccessoryMotorPower "Calculated electrical power consumed by this Electrified Accessory Motor.…";
CM_ SG_ 2566652414 ElectrifiedAccessoryMotorSpeed "Speed of this Electrified Accessory Motor. …";
CM_ SG_ 2566652414 EltrfdAssrMtrCntrllrCmmndStts "Indicates the source of the speed command to this Electrified Accessory Motor system or component.00b is communicated when the controller is self-controlled (e.…";
CM_ SG_ 2566652414 EltrfdAssrMtrCntrllrSttsRsnCd "Provides the reason code describing the unique failure of this Electrified Accessory Motor system or component.If a detailed reason code is not used by the supp…";
CM_ SG_ 2566652414 EltrfdAssrMtrEnlStts "Enable and direction status of this Electrified Accessory Motor system or component.00b = Accessory Motor Off01b = Accessory Motor On - Normal, Forward, or Defa…";
CM_ SG_ 2566652414 EltrfdAssrMtrInstn "Indicates the electrified accessory instance that is providing status.0000b = Instance 10001b = Instance 20010b = Instance 30011b = Instance 40100b = Instance 5…";
CM_ SG_ 2566652414 EltrfdAssrMtrMdmTmprtr "A temperature measured and reported by the device.  It may be used for direct or remote (e.g. by another controller) control of the pump.  For example, this may…";
CM_ SG_ 2566652414 EltrfdAssrMtrOprtngStts "Indicates the operating status of this Electrified Accessory Motor system or component.  This parameter is used to inform other devices that this system or comp…";
CM_ SG_ 2566652414 EltrfdAssrMtrSrvIndtr "Indicates that service is required for this Electrified Accessory Motor system or component.  An active indication may convey a need for component replacement o…";
CM_ BO_ 2566652670 "SCR System Information";
CM_ SG_ 2566652670 Aftrtrtmnt1SCRSstmHdrrn "The ratio of the mass of hydrocarbon present in the aftertreatment system compared to the maximum allowable mass of hydrocarbon for the aftertreatment system. 1…";
CM_ SG_ 2566652670 Aftrtrtmnt2SCRSstmHdrrn "The ratio of the mass of hydrocarbon present in the aftertreatment 2 system compared to the maximum allowable mass of hydrocarbon for the aftertreatment system.…";
CM_ SG_ 2566652670 Atttt1DsExstFdDsSstFz "All or part of the diesel exhaust fluid system (DEF tank, DEF supply lines, DEF pump, and DEF doser, etc.) in bank 1 is frozen.In situations where it is desired…";
CM_ SG_ 2566652670 Atttt2DsExstFdDsSstFz "All or part of the diesel exhaust fluid system (DEF tank, DEF supply lines, DEF pump, and DEF doser, etc.) in bank 2 is frozen.In situations where it is desired…";
CM_ SG_ 2566652670 DieselExhaustFluidFrozenTime "Indicates the amount of time the diesel exhaust fluid is frozen while key switch is on. This will accumulate over the life of the product, and will never be res…";
CM_ BO_ 2566652926 "Vehicle Electrical Power 14";
CM_ SG_ 2566652926 SLIBatteryPack1Battery4Capacity "Total reserve capacity of the fourth battery in the first battery pack used for starting the engine, for lighting, and for ignition (SLI).  This value could be …";
CM_ SG_ 2566652926 SLIBatteryPack1Battery4Health "Capacity of the fourth battery in the first battery pack relative to its original specification for the battery pack used for starting the engine, for lighting,…";
CM_ SG_ 2566652926 SLIBttP1Btt4PdtdMCVt "Prediction of the minimum battery voltage of the fourth battery in the first battery pack used for starting the engine, for lighting, and for ignition (SLI) dur…";
CM_ SG_ 2566652926 SLIBttrPk1Bttr4SttfChrg "Indicates the remaining charge of the fourth battery in the first battery pack used for starting the engine, for lighting, and for ignition (SLI). 0% means no c…";
CM_ SG_ 2566652926 SLIBttrPk1Snsr4IntlztnStts "The battery sensor may go through an initialization process when it is first connected to a battery.  This parameter reports the battery sensor's progress throu…";
CM_ BO_ 2566653182 "Vehicle Electrical Power 13";
CM_ SG_ 2566653182 SLIBatteryPack1Battery4Voltage "Voltage of the fourth battery in the first set of batteries (battery pack) used for starting the engine, for lighting, and for ignition (SLI). The relation to p…";
CM_ SG_ 2566653182 SLIBttrPk1Bttr4NtCrrnt "Net flow of electrical current into/out of the fourth battery in the first set of batteries (battery pack) used for starting the engine, for lighting, and for i…";
CM_ SG_ 2566653182 SLIBttrPk1Bttr4Tmprtr "Temperature of the fourth battery in the first set of batteries (battery pack) used for starting the engine, for lighting, and for ignition (SLI). The relation …";
CM_ BO_ 2566653438 "Vehicle Electrical Power 12";
CM_ SG_ 2566653438 SLIBatteryPack1Battery3Capacity "Total reserve capacity of the third battery in the first battery pack used for starting the engine, for lighting, and for ignition (SLI).  This value could be t…";
CM_ SG_ 2566653438 SLIBatteryPack1Battery3Health "Capacity of the third battery in the first battery pack relative to its original specification for the battery pack used for starting the engine, for lighting, …";
CM_ SG_ 2566653438 SLIBttP1Btt3PdtdMCVt "Prediction of the minimum battery voltage of the third battery in the first battery pack used for starting the engine, for lighting, and for ignition (SLI) duri…";
CM_ SG_ 2566653438 SLIBttrPk1Bttr3SttfChrg "Indicates the remaining charge of the third battery in the first battery pack used for starting the engine, for lighting, and for ignition (SLI). 0% means no ch…";
CM_ SG_ 2566653438 SLIBttrPk1Snsr3IntlztnStts "The battery sensor may go through an initialization process when it is first connected to a battery.  This parameter reports the battery sensor's progress throu…";
CM_ BO_ 2566653694 "Vehicle Electrical Power 11";
CM_ SG_ 2566653694 SLIBatteryPack1Battery3Voltage "Voltage of the third battery in the first set of batteries (battery pack) used for starting the engine, for lighting, and for ignition (SLI). The relation to ph…";
CM_ SG_ 2566653694 SLIBttrPk1Bttr3NtCrrnt "Net flow of electrical current into/out of the third battery in the first set of batteries (battery pack) used for starting the engine, for lighting, and for ig…";
CM_ SG_ 2566653694 SLIBttrPk1Bttr3Tmprtr "Temperature of the third battery in the first set of batteries (battery pack) used for starting the engine, for lighting, and for ignition (SLI). The relation t…";
CM_ BO_ 2566653950 "Vehicle Electrical Power 10";
CM_ SG_ 2566653950 SLIBatteryPack1Battery2Capacity "Total reserve capacity of the second battery in the first battery pack used for starting the engine, for lighting, and for ignition (SLI).  This value could be …";
CM_ SG_ 2566653950 SLIBatteryPack1Battery2Health "Capacity of the second battery in the first battery pack relative to its original specification for the battery pack used for starting the engine, for lighting,…";
CM_ SG_ 2566653950 SLIBttP1Btt2PdtdMCVt "Prediction of the minimum battery voltage of the second battery in the first battery pack used for starting the engine, for lighting, and for ignition (SLI) dur…";
CM_ SG_ 2566653950 SLIBttrPk1Bttr2SttfChrg "Indicates the remaining charge of the second battery in the first battery pack used for starting the engine, for lighting, and for ignition (SLI). 0% means no c…";
CM_ SG_ 2566653950 SLIBttrPk1Snsr2IntlztnStts "The battery sensor may go through an initialization process when it is first connected to a battery.  This parameter reports the battery sensor's progress throu…";
CM_ BO_ 2566654206 "Vehicle Electrical Power 9";
CM_ SG_ 2566654206 SLIBatteryPack1Battery2Voltage "Voltage of the second battery in the first set of batteries (battery pack) used for starting the engine, for lighting, and for ignition (SLI). The relation to p…";
CM_ SG_ 2566654206 SLIBttrPk1Bttr2NtCrrnt "Net flow of electrical current into/out of the second battery in the first set of batteries (battery pack) used for starting the engine, for lighting, and for i…";
CM_ SG_ 2566654206 SLIBttrPk1Bttr2Tmprtr "Temperature of the second battery in the first set of batteries (battery pack) used for starting the engine, for lighting, and for ignition (SLI). The relation …";
CM_ BO_ 2566654462 "Vehicle Electrical Power 8";
CM_ SG_ 2566654462 SLIBatteryPack1Battery1Capacity "Total reserve capacity of the first battery in the first battery pack used for starting the engine, for lighting, and for ignition (SLI).  This value could be t…";
CM_ SG_ 2566654462 SLIBatteryPack1Battery1Health "Capacity of the first battery in the first battery pack relative to its original specification for the battery pack used for starting the engine, for lighting, …";
CM_ SG_ 2566654462 SLIBttP1Btt1PdtdMCVt "Prediction of the minimum battery voltage of the first battery in the first battery pack used for starting the engine, for lighting, and for ignition (SLI) duri…";
CM_ SG_ 2566654462 SLIBttrPk1Bttr1SttfChrg "Indicates the remaining charge of the first battery in the first battery pack used for starting the engine, for lighting, and for ignition (SLI). 0% means no ch…";
CM_ SG_ 2566654462 SLIBttrPk1Snsr1IntlztnStts "The battery sensor may go through an initialization process when it is first connected to a battery.  This parameter reports the battery sensor's progress throu…";
CM_ BO_ 2566654718 "Vehicle Electrical Power 7";
CM_ SG_ 2566654718 SLIBatteryPack1Battery1Voltage "Voltage of the first battery in the first set of batteries (battery pack) used for starting the engine, for lighting, and for ignition (SLI). The relation to ph…";
CM_ SG_ 2566654718 SLIBttrPk1Bttr1NtCrrnt "Net flow of electrical current into/out of the first battery in the first set of batteries (battery pack) used for starting the engine, for lighting, and for ig…";
CM_ SG_ 2566654718 SLIBttrPk1Bttr1Tmprtr "Temperature of the first battery in the first set of batteries (battery pack) used for starting the engine, for lighting, and for ignition (SLI). The relation t…";
CM_ BO_ 2566654974 "Electronic Engine Controller 20";
CM_ SG_ 2566654974 AtlMxmmAvllEngnPrntFl "The percent of torque limited fuel relative to the engine standard torque fuel.  The torque limited fuel in the Actual Maximum Available Engine - Percent Fuel s…";
CM_ SG_ 2566654974 EsttdEPstLsssPtTqHRst "Indicates the estimated amount of torque loss due to engine parasitics, such as cooling fan, air compressor, air conditioning, etc. It is expressed as a percent…";
CM_ BO_ 2566655742 "Primary or Rear Hitch Roll and Pitch Sensitivity";
CM_ SG_ 2566655742 RearHitchPitchSensitivity "The current sensitivity of the rear hitch pitch control expressed as a percentage of the maximum gain.  0% indicates minimal gain in the control loop; 100%, the…";
CM_ SG_ 2566655742 RearHitchRollSensitivity "The current sensitivity of the rear hitch roll control expressed as a percentage of the maximum gain.  0% indicates minimal gain in the control loop; 100%, the …";
CM_ BO_ 2566656254 "Ambient Conditions 3";
CM_ SG_ 2566656254 BarometricAbsolutePressure2 "Second absolute air pressure measurement of the atmosphere.See SPN 108 or SPN 5685 as the primary barometric pressure measurement.…";
CM_ SG_ 2566656254 EngineIntake2AirTemperature "Temperature of air entering through a second vehicle air induction system.…";
CM_ BO_ 2566656510 "Total Gaseous Fuel Information";
CM_ SG_ 2566656510 EngnTtlGssFlVlmUsd "Accumulated volume of engine gaseous fuel used during vehicle operation, in standard cubic meters.See SPN 1040 for alternate units.…";
CM_ SG_ 2566656510 EngnTtlGssIdlFlVlmUsd "Accumulated volume of engine gaseous fuel used during vehicle operation under idle conditions, in standard cubic meters.…";
CM_ BO_ 2566658302 "Payload System Totals 2";
CM_ SG_ 2566658302 TotalPayloadTransactionCount "The accumulated number of completed payload delivery transactions over the life of the product.If transaction status monitoring is supported via Payload Deliver…";
CM_ BO_ 2566658558 "Payload System Totals 1";
CM_ SG_ 2566658558 TotalDeliveredPayloadWeight "The accumulated delivered payload mass over the life of the product.This should be a monotonically increasing number that sums delivered payload weights (SPN 68…";
CM_ SG_ 2566658558 TotalHaulCycleCount "The total accumulated number of haul cycles over the life of the product.This should be a monotonically increasing number that sums Haul Cycle Count (SPN 6847).…";
CM_ BO_ 2566661118 "Fuel Consumption (Liquid) 2";
CM_ SG_ 2566661118 EngineTotalDieselFuelDemand "Accumulated amount of liquid fuel that would have been used during engine operation, including actual diesel fuel used and the diesel fuel that was displaced by…";
CM_ BO_ 2566661374 "Aftertreatment 2 Diesel Exhaust Fluid Tank 1 Information 2";
CM_ SG_ 2566661374 Aftrtrtmnt2DslExhstFldTnkHtr2 "Percentage of heating applied to the second diesel exhaust fluid tank heater on aftertreatment 2. A value of 0% means no heating applied, a value of 100% means …";
CM_ SG_ 2566661374 Aftrtrtmnt2DslExhstFldTnkVlm2 "Second measurement of the ratio of volume of diesel exhaust fluid to the total volume of the diesel exhaust fluid storage container for aftertreatment system 2 …";
CM_ SG_ 2566661374 Atttt2DsExstFdTTpt2 "The second temperature of aftertreatment 2 diesel exhaust fluid in the storage tank.…";
CM_ BO_ 2566661630 "Aftertreatment 1 Diesel Exhaust Fluid Tank 1 Information 2";
CM_ SG_ 2566661630 Aftrtrtmnt1DslExhstFldTnkHtr2 "Percentage of heating applied to the second diesel exhaust fluid tank heater on aftertreatment 1. A value of 0% means no heating applied, a value of 100% means …";
CM_ SG_ 2566661630 Aftrtrtmnt1DslExhstFldTnkVlm2 "Second measurement of the ratio of volume of diesel exhaust fluid to the total volume of the diesel exhaust fluid storage container for aftertreatment system 1 …";
CM_ SG_ 2566661630 Atttt1DsExstFdTTpt2 "The second temperature of aftertreatment 1 diesel exhaust fluid in the storage tank.…";
CM_ BO_ 2566661886 "Aftertreatment 2 Diesel Exhaust Fluid Information 2";
CM_ SG_ 2566661886 Atttt2DsExstFdCt2Tpt "Temperature of the diesel exhaust fluid at the aftertreatment 2 diesel exhaust fluid controller 2.…";
CM_ SG_ 2566661886 Atttt2DsExstFdCtTpt "Temperature of the diesel exhaust fluid at the aftertreatment 2 diesel exhaust fluid controller.…";
CM_ BO_ 2566662142 "Aftertreatment 1 Diesel Exhaust Fluid Information 2";
CM_ SG_ 2566662142 Atttt1DsExstFdCt1Tpt "Temperature of the diesel exhaust fluid at the aftertreatment 1 diesel exhaust fluid controller.For controllers that have more exhaust emissions control functio…";
CM_ SG_ 2566662142 Atttt1DsExstFdCt2Tpt "Temperature of the diesel exhaust fluid at the aftertreatment 1 diesel exhaust fluid controller 2.…";
CM_ BO_ 2566662654 "Forward Lane Image 3";
CM_ SG_ 2566662654 LaneDepartureAngleLeft "Angle between left lane mark and vehicle driving direction. The angle is positive while vehicle is moving towards the lane marks, and negative if not. Measured …";
CM_ SG_ 2566662654 LaneDepartureAngleRight "Angle between right lane mark and vehicle driving direction. The angle is positive while vehicle is moving towards the lane marks, and negative if not. Measured…";
CM_ SG_ 2566662654 LaneMarkQualityontheLeftSide "The quality of the nearest lane mark on the left side of the vehicle.000b = no lane marks detected001b = low reliablity of detected lane marks010b = good reliab…";
CM_ SG_ 2566662654 LaneMarkQualityontheRightSide "The quality of the nearest lane mark on the right side of the vehicle.000b = no lane marks detected001b = low reliablity of detected lane marks010b = good relia…";
CM_ SG_ 2566662654 LeftLaneMarkerType "Indicates the type of lane marker detected by the Forward Lane Imager on the left side. 0000b = Processing or not identified0001b = Solid0010b = Road edge0011b …";
CM_ SG_ 2566662654 LftDstntLnMrkfrmVhlsMddl "Distance between middle of the vehicle front and the inner/right edge of the nearest lane mark on the left side as measured from the Forward Lane Imager. The va…";
CM_ SG_ 2566662654 RghtDstntLnMrkfrmVhlsMddl "Distance between middle of the vehicle front and the inner/left edge of the nearest lane mark on the right side as measured from the Forward Lane Imager. The va…";
CM_ SG_ 2566662654 RightLaneMarkerType "Indicates the type of lane marker detected by the Forward Lane Imager on the right side. 0000b = Processing or not identified0001b = Solid0010b = Road edge0011b…";
CM_ SG_ 2566662654 RoadCurvatureBasedonLaneMarks "The road curvature parameter is based on lane marks as measured by the FLI.  It is the mean value of the road curvature of the lane marks on the left and right …";
CM_ BO_ 2566662910 "Operator Inducement Information";
CM_ SG_ 2566662910 OprtrIndmntTmtFnlIndmntAtn "Indicates the time until the inducement strategy enforces the final level of engine emissions operator inducement. The final level of inducement can include der…";
CM_ SG_ 2566662910 OprtrIndmntTmtTrqDrtLvl1 "This parameter provides the time until Operator Inducement Torque Derate Level 1 (SPN 7425) is activated.When operator inducement is not active, this parameter …";
CM_ SG_ 2566662910 OprtrIndmntTmtTrqDrtLvl2 "This parameter provides the time until Operator Inducement Torque Derate Level 2 (SPN 7427) is activated.When operator inducement is not active or if a second l…";
CM_ SG_ 2566662910 OprtrIndmntTrqDrtLvl1 "This is the first torque derate that will be applied to the engine operation due to operator inducement.  The torque derate indicated in this parameter will be …";
CM_ SG_ 2566662910 OprtrIndmntTrqDrtLvl2 "This is the second torque derate that will be applied to the engine operation due to operator inducement. The torque derate level indicated in this parameter wi…";
CM_ BO_ 2566663166 "Cruise Control / Vehicle Speed 4";
CM_ SG_ 2566663166 AppldVhlSpdLmtHghRsltn "The vehicle speed limit in effect.See SPN 2595 for alternate resolution.Note:  If a maximum vehicle speed limit is not selected, then the first byte of this par…";
CM_ SG_ 2566663166 CrsCntrlAdjstdMxmmSpd "Present maximum vehicle velocity at which cruise can be set. This parameter is expected to change during run-time due to functionality that could influence the …";
CM_ SG_ 2566663166 EngnExtrnlIdlRqstFdk "Indicates that the engine is altering the idle speed due to a request from an external source. 00b = No Idle Alteration Active - standard idle speed01b = Idle A…";
CM_ SG_ 2566663166 SAddssCtDvSttCsCt "The source address of the SAE J1939 device that is currently sending the Cruise Control Set Command (SPN 9843).If there are multiple devices sending Cruise Cont…";
CM_ BO_ 2566663422 "Brake Caliper Lining Clearance";
CM_ SG_ 2566663422 TrlrBrkClprLnngClrnAxl1Lft "Brake caliper lining clearance for left brake on trailer axle 1.00b = Caliper lining clearance is adequate01b = Caliper lining clearance is low10b = Error11b = …";
CM_ SG_ 2566663422 TrlrBrkClprLnngClrnAxl1Rght "Brake caliper lining clearance for right brake on trailer axle 1.00b = Caliper lining clearance is adequate01b = Caliper lining clearance is low10b = Error11b =…";
CM_ SG_ 2566663422 TrlrBrkClprLnngClrnAxl2Lft "Brake caliper lining clearance for left brake on trailer axle 2.00b = Caliper lining clearance is adequate01b = Caliper lining clearance is low10b = Error11b = …";
CM_ SG_ 2566663422 TrlrBrkClprLnngClrnAxl2Rght "Brake caliper lining clearance for right brake on trailer axle 2.00b = Caliper lining clearance is adequate01b = Caliper lining clearance is low10b = Error11b =…";
CM_ SG_ 2566663422 TrlrBrkClprLnngClrnAxl3Lft "Brake caliper lining clearance for left brake on trailer axle 3.00b = Caliper lining clearance is adequate01b = Caliper lining clearance is low10b = Error11b = …";
CM_ SG_ 2566663422 TrlrBrkClprLnngClrnAxl3Rght "Brake caliper lining clearance for right brake on trailer axle 3.00b = Caliper lining clearance is adequate01b = Caliper lining clearance is low10b = Error11b =…";
CM_ SG_ 2566663422 TrlrBrkClprLnngClrnAxl4Lft "Brake caliper lining clearance for left brake on trailer axle 4.00b = Caliper lining clearance is adequate01b = Caliper lining clearance is low10b = Error11b = …";
CM_ SG_ 2566663422 TrlrBrkClprLnngClrnAxl4Rght "Brake caliper lining clearance for right brake on trailer axle 4.00b = Caliper lining clearance is adequate01b = Caliper lining clearance is low10b = Error11b =…";
CM_ SG_ 2566663422 TrlrBrkClprLnngClrnAxl5Lft "Brake caliper lining clearance for left brake on trailer axle 5.00b = Caliper lining clearance is adequate01b = Caliper lining clearance is low10b = Error11b = …";
CM_ SG_ 2566663422 TrlrBrkClprLnngClrnAxl5Rght "Brake caliper lining clearance for right brake on trailer axle 5.00b = Caliper lining clearance is adequate01b = Caliper lining clearance is low10b = Error11b =…";
CM_ SG_ 2566663422 TrtrBrkClprLnngClrnAxl1Lft "Brake caliper lining clearance for left brake on tractor axle 1.00b = Caliper lining clearance is adequate01b = Caliper lining clearance is low10b = Error11b = …";
CM_ SG_ 2566663422 TrtrBrkClprLnngClrnAxl1Rght "Brake caliper lining clearance for right brake on tractor axle 1.00b = Caliper lining clearance is adequate01b = Caliper lining clearance is low10b = Error11b =…";
CM_ SG_ 2566663422 TrtrBrkClprLnngClrnAxl2Lft "Brake caliper lining clearance for left brake on tractor axle 2.00b = Caliper lining clearance is adequate01b = Caliper lining clearance is low10b = Error11b = …";
CM_ SG_ 2566663422 TrtrBrkClprLnngClrnAxl2Rght "Brake caliper lining clearance for right brake on tractor axle 2.00b = Caliper lining clearance is adequate01b = Caliper lining clearance is low10b = Error11b =…";
CM_ SG_ 2566663422 TrtrBrkClprLnngClrnAxl3Lft "Brake caliper lining clearance for left brake on tractor axle 3.00b = Caliper lining clearance is adequate01b = Caliper lining clearance is low10b = Error11b = …";
CM_ SG_ 2566663422 TrtrBrkClprLnngClrnAxl3Rght "Brake caliper lining clearance for right brake on tractor axle 3.00b = Caliper lining clearance is adequate01b = Caliper lining clearance is low10b = Error11b =…";
CM_ SG_ 2566663422 TrtrBrkClprLnngClrnAxl4Lft "Brake caliper lining clearance for left brake on tractor axle 4.00b = Caliper lining clearance is adequate01b = Caliper lining clearance is low10b = Error11b = …";
CM_ SG_ 2566663422 TrtrBrkClprLnngClrnAxl4Rght "Brake caliper lining clearance for right brake on tractor axle 4.00b = Caliper lining clearance is adequate01b = Caliper lining clearance is low10b = Error11b =…";
CM_ SG_ 2566663422 TrtrBrkClprLnngClrnAxl5Lft "Brake caliper lining clearance for left brake on tractor axle 5.00b = Caliper lining clearance is adequate01b = Caliper lining clearance is low10b = Error11b = …";
CM_ SG_ 2566663422 TrtrBrkClprLnngClrnAxl5Rght "Brake caliper lining clearance for right brake on tractor axle 5.00b = Caliper lining clearance is adequate01b = Caliper lining clearance is low10b = Error11b =…";
CM_ BO_ 2566663678 "Alternate Fuel 5";
CM_ SG_ 2566663678 EngnFl2InjtrMtrngRl1Tmprtr2 "The second temperature of fuel 2 measured by first rail temperature sensor in the primary, or first, metering rail as delivered from the supply pump to the inje…";
CM_ SG_ 2566663678 LNGTank1VaporPressure "Gage pressure of the vapor in the first tank in a multi-tank system (or unique tank if single-tank system).…";
CM_ SG_ 2566663678 LNGTank2VaporPressure "Gage pressure of the vapor in the second tank in a multi-tank system.…";
CM_ BO_ 2566663934 "Engine Turbocharger Control 3";
CM_ SG_ 2566663934 EngnClndrHdBpssAttr1MtrCrrntDsl "Command to disable power to motor in the actuator to prevent unnecessary load on the component.00b = Do Not Disable01b = Disable10b = Reserved11b = Don't Care/T…";
CM_ SG_ 2566663934 EngnThrttlVlv1MtrCrrntDsl "Command to disable power to motor in the actuator to prevent unnecessary load on the component.00b = Do Not Disable01b = Disable10b = Reserved11b = Don't Care/T…";
CM_ SG_ 2566663934 EngnTrhrgrWstgtAttr1MtrCrrntDsl "Command to disable power to motor in the actuator to prevent unnecessary load on the component.00b = Do Not Disable01b = Disable10b = Reserved11b = Don't Care/T…";
CM_ SG_ 2566663934 EngnTrhrgrWstgtAttr2MtrCrrntDsl "Command to disable power to motor in wastegate actuator 2 to prevent unnecessary load on the component.00b = Do Not Disable01b = Disable10b = Reserved11b = Don'…";
CM_ SG_ 2566663934 ETCpssBpssAtt1MtCtDs "Command to disable power to motor in bypass actuator 1 to prevent unnecessary load on the component.00b = Do Not Disable01b = Disable10b = Reserved11b = Don't C…";
CM_ SG_ 2566663934 ETCpssBpssAtt2MtCtDs "Command to disable power to motor in bypass actuator 2 to prevent unnecessary load on the component.00b = Do Not Disable01b = Disable10b = Reserved11b = Don't C…";
CM_ SG_ 2566663934 ETCpssBwAtt1MtCtDs "Command to disable power to motor in the actuator to prevent unnecessary load on the component.00b = Do Not Disable01b = Disable10b = Reserved11b = Don't Care/T…";
CM_ BO_ 2566664702 "Aftertreatment System Information 1";
CM_ SG_ 2566664702 AftertreatmentEngineLoadRequest "Indicates whether the aftertreatment desires engine load to be applied. This is meant to notify the operator that the aftertreatment is requesting engine load f…";
CM_ SG_ 2566664702 AftrtrtmntAmntArTmprtr "Temperature of ambient air near the aftertreatment components such as DEF tank and DEF lines.…";
CM_ SG_ 2566664702 AftrtrtmntDslExhstFldHtrCrtBrkr "The status of the circuit breaker that is used to heat the diesel exhaust fluid.00b = off01b = on10b = error11b = not available…";
CM_ SG_ 2566664702 AftrtrtmntDslExhstFldTnkTmprtr "The derived diesel exhaust fluid tank temperature in applications with multiple temperature sensors in a single tank. The SPN data will be derived from all temp…";
CM_ SG_ 2566664702 AftrtrtmntDslExhstFldTnkVlm "The derived diesel exhaust fluid tank volume in applications with multiple level sensors in a single tank. The SPN data will be derived from all level sensors i…";
CM_ SG_ 2566664702 AftrtrtmntEngnSpdInrsrqst "Indicates whether the aftertreatment desires engine speed control in order to increase the engine speed. This is meant to notify the operator that the aftertrea…";
CM_ SG_ 2566664702 AftrtrtmntThrmlMngmntStts "Indicates whether Aftertreatment Thermal Management process is active.Aftertreatment Thermal Management indicates that the exhaust temperatures have been contro…";
CM_ SG_ 2566664702 AttttAtvRtItdDtLwExstPss "The state of aftertreatment active regeneration inhibition due to low exhaust pressure.Aftertreatment Regeneration is a process of increasing the temperature at…";
CM_ SG_ 2566664702 DslExhstFldQltMlfntnEvltnPrdAtv "This parameter is used to notify the operator that a DEF Quality and DEF Level evaluation period, also known as a judgement period, is currently active.The judg…";
CM_ SG_ 2566664702 AftrtrtmntSCRDsngMdStts "Indicates that the aftertreatment system is dosing in standard or reduced mode.Standard indicates that the system will dose at maximum capacity where the reduce…";
CM_ SG_ 2566664702 DPFAtvRgnrtnTmRmnng "Indicates approximate remaining time of the parked active DPF Regeneration. This time is not for passive regeneration.If active regeneration is not in progress,…";
CM_ BO_ 2566665726 "Aftertreatment 2 Diesel Exhaust Fluid Pump 1 Information";
CM_ SG_ 2566665726 Aftrtrtmnt2DslExhstFldPmpHtr "Percentage of heating applied to the aftertreatment 2 diesel exhaust fluid pump heater.  A value of 0% means no heating applied, a value of 100% means full heat…";
CM_ SG_ 2566665726 Atttt2DsExstFdPp2MtSpd "Rotational speed of the motor driving the second pump for the diesel exhaust fluid used in aftertreatment system 2 (exhaust bank 2).…";
CM_ BO_ 2566667262 "Engine End Bearing Temperature 3";
CM_ SG_ 2566667262 EngineEndBearing17Temperature "Temperature of end bearing of the connecting rod for cylinder 17 on the engine…";
CM_ SG_ 2566667262 EngineEndBearing18Temperature "Temperature of end bearing of the connecting rod for cylinder 18 on the engine…";
CM_ SG_ 2566667262 EngineEndBearing19Temperature "Temperature of end bearing of the connecting rod for cylinder 19 on the engine…";
CM_ SG_ 2566667262 EngineEndBearing20Temperature "Temperature of end bearing of the connecting rod for cylinder 20 on the engine…";
CM_ BO_ 2566667518 "Engine End Bearing Temperature 2";
CM_ SG_ 2566667518 EngineEndBearing10Temperature "Temperature of end bearing of the connecting rod for cylinder 10 on the engine…";
CM_ SG_ 2566667518 EngineEndBearing11Temperature "Temperature of end bearing of the connecting rod for cylinder 11 on the engine…";
CM_ SG_ 2566667518 EngineEndBearing12Temperature "Temperature of end bearing of the connecting rod for cylinder 12 on the engine…";
CM_ SG_ 2566667518 EngineEndBearing13Temperature "Temperature of end bearing of the connecting rod for cylinder 13 on the engine…";
CM_ SG_ 2566667518 EngineEndBearing14Temperature "Temperature of end bearing of the connecting rod for cylinder 14 on the engine…";
CM_ SG_ 2566667518 EngineEndBearing15Temperature "Temperature of end bearing of the connecting rod for cylinder 15 on the engine…";
CM_ SG_ 2566667518 EngineEndBearing16Temperature "Temperature of end bearing of the connecting rod for cylinder 16 on the engine…";
CM_ SG_ 2566667518 EngineEndBearing9Temperature "Temperature of end bearing of the connecting rod for cylinder 9 on the engine…";
CM_ BO_ 2566667774 "Engine End Bearing Temperature 1";
CM_ SG_ 2566667774 EngineEndBearing1Temperature "Temperature of end bearing of the connecting rod for cylinder 1 on the engine…";
CM_ SG_ 2566667774 EngineEndBearing2Temperature "Temperature of end bearing of the connecting rod for cylinder 2 on the engine…";
CM_ SG_ 2566667774 EngineEndBearing3Temperature "Temperature of end bearing of the connecting rod for cylinder 3 on the engine…";
CM_ SG_ 2566667774 EngineEndBearing4Temperature "Temperature of end bearing of the connecting rod for cylinder 4 on the engine…";
CM_ SG_ 2566667774 EngineEndBearing5Temperature "Temperature of end bearing of the connecting rod for cylinder 5 on the engine…";
CM_ SG_ 2566667774 EngineEndBearing6Temperature "Temperature of end bearing of the connecting rod for cylinder 6 on the engine…";
CM_ SG_ 2566667774 EngineEndBearing7Temperature "Temperature of end bearing of the connecting rod for cylinder 7 on the engine…";
CM_ SG_ 2566667774 EngineEndBearing8Temperature "Temperature of end bearing of the connecting rod for cylinder 8 on the engine…";
CM_ BO_ 2566668030 "Heat Exchanger Debris Purge Information";
CM_ SG_ 2566668030 HeatExchangerDebrisPurgeStatus "Indicates whether the system is currently purging debris from the heat exchanger.00b = Inactive01b = Active10b = SAE reserved11b = Not available…";
CM_ SG_ 2566668030 HtExhngrDrsPrgApprhng "Status signal which indicates that purging the debris from the heat exchanger is imminent.00b = Not approaching01b = Approaching10b = SAE reserved11b = Not avai…";
CM_ BO_ 2566668286 "Engine Turbocharger Control 2";
CM_ SG_ 2566668286 EngnStgdTrhrgrSlndStts "Current state of the staged turbocharger solenoid, normalized to percent, 0% represents not actuated and 100% represents fully actuated.…";
CM_ BO_ 2566668542 "Engine Hydraulic Fuel 2 Pump Status";
CM_ SG_ 2566668542 EngnFl2PmpHdrlDrtnlVlv "Position of hydraulic directional valve to control application of hydraulic oil flow.  0% is no flow to the appliance; 100% is full flow to the appliance.…";
CM_ SG_ 2566668542 EngnFl2PmpHdrlFlwCntrlVlv "Position of hydraulic pump flow control valve opening; 0% = fully closed, 100% = fully open.…";
CM_ SG_ 2566668542 EngnFl2PmpHdrlPrssr "Hydraulic pressure in the lines of the hydraulically driven fuel 2 pump.…";
CM_ SG_ 2566668542 EngnFl2PmpHdrlSwshPltAngl "Position of hydraulic swash plate angle within hydraulic pump.  0% represents the lowest possible flow, 100% represents the maximum flow.…";
CM_ BO_ 2566668798 "Alternate Fuel 4";
CM_ SG_ 2566668798 EngnFl2InjtrMtrngRl1Prssr "The pressure of fuel 2 measured by first rail pressure sensor in the primary, or first, metering rail as delivered from the supply pump to the injector metering…";
CM_ SG_ 2566668798 EngnFl2InjtrMtrngRl1Prssr2 "The second pressure of fuel 2 measured by first rail pressure sensor in the primary, or first, metering rail as delivered from the supply pump to the injector m…";
CM_ SG_ 2566668798 EngnFl2InjtrMtrngRl1Tmprtr "The temperature of fuel 2 measured by first rail temperature sensor in the primary, or first, metering rail as delivered from the supply pump to the injector me…";
CM_ SG_ 2566668798 EngnFl2InjtrMtrngRl2Prssr "The pressure of fuel 2 measured by first rail pressure sensor in the metering rail 2 as delivered from the supply pump to the injector metering intake.…";
CM_ SG_ 2566668798 EngnFl2InjtrMtrngRl2Tmprtr "The temperature of fuel 2 measured by first rail temperature sensor in the metering rail 2 as delivered from the supply pump to the injector metering intake.…";
CM_ BO_ 2566669054 "Tire Condition Message 2";
CM_ SG_ 2566669054 RequiredTirePressure "The required tire pressure at which air is contained in cavity formed by tire and rim.This pressure of the tire is compensated to meet the specific physical env…";
CM_ SG_ 2566669054 TireLocation "Identifies which tire is associated with the parametric data in PGN 64578. Refer to SPN 929 for further details and examples. The low order 4 bits represent a p…";
CM_ SG_ 2566669054 TirePressureExtendedRange "Pressure at which air is contained in cavity formed by tire and rim. See SPN 241 for alternate tire pressure with a lower range and coarser resolution.…";
CM_ BO_ 2566669310 "Tire Configuration Status Information";
CM_ SG_ 2566669310 ColdInflationPressure "The cold inflation pressure of the tire. Cold inflation pressure is the default/reference inflation pressure suggested by the manufacturer for a specific tire.…";
CM_ SG_ 2566669310 ExtrmUndrPrssrPrntgThrshld "The percentage deviation from the set cold inflation pressure, for the extreme under tire pressure alert.…";
CM_ SG_ 2566669310 OverPressurePercentageThreshold "The percentage deviation from the set cold inflation pressure, for the over tire pressure alert.…";
CM_ SG_ 2566669310 OverTemperature "The temperature above which the over temperature alert will trigger.…";
CM_ SG_ 2566669310 TireLocation "The location of monitored tire on the vehicle.The high order 4 bits indicate the vehicle axle position of the tire sensor, counting front to back on the vehicle…";
CM_ SG_ 2566669310 UndrPrssrPrntgThrshld "The percentage deviation from the set cold inflation pressure, for the under tire pressure alert.…";
CM_ BO_ 2566669822 "Tire Wireless Signal Strength Indicator";
CM_ SG_ 2566669822 AntennaNumber "Number of the antenna used to communicate signal strength of a group of sensors.  If a single antenna is used this will default to 01h. When multiple antennas a…";
CM_ SG_ 2566669822 TireLocation "The location of monitored tire on the vehicle.The high order 4 bits indicate the vehicle axle position of the tire sensor, counting front to back on the vehicle…";
CM_ SG_ 2566669822 TireSensorNumber "The number of the monitored tire sensor that corresponds with the tire wireless signal strength indicator. The location of the numbered tire is reported in the …";
CM_ SG_ 2566669822 TotalNumberofAntennasUsed "Total count of antennas used in the specified vehicle system.…";
CM_ SG_ 2566669822 TrWrlssSgnlStrngthIndtr "The wireless signal strength between the tire pressure sensor and the specified antenna, for the tire specified in the tire sensor number or tire sensor Locatio…";
CM_ SG_ 2566669822 TtlNmrfTrSnsrsMntrd "Total number of tire sensors monitored for the specified antenna in this instance of the parameter group.…";
CM_ BO_ 2566670078 "Tire Sensor Identification Status";
CM_ SG_ 2566670078 NumberofTireSensors "Total count of monitored tire sensor identification numbers represented in this instance of the parameter group.…";
CM_ SG_ 2566670078 TireLocation "The location of monitored tire that corresponds with the Tire Sensor Identification Number (SPN 6966). In order to specify the monitored tire by tire number, us…";
CM_ SG_ 2566670078 TireNumber "The number of the monitored tire that corresponds with the Tire Sensor Identification Number (SPN 6966).  In order to specify the monitored tire by location, us…";
CM_ SG_ 2566670078 TireSensorIdentificationNumber "The identification number of the tire specified in the tire number (SPN 6964) or tire location (SPN 6965).…";
CM_ BO_ 2566670334 "Monitored Tire Information";
CM_ SG_ 2566670334 Axle10MonitoredTireCount "The number of tires on Axle 10 which are monitored by the tire monitor controller. The axle number increments from front to rear of the vehicle when facing the …";
CM_ SG_ 2566670334 Axle11MonitoredTireCount "The number of tires on Axle 11 which are monitored by the tire monitor controller. The axle number increments from front to rear of the vehicle when facing the …";
CM_ SG_ 2566670334 Axle12MonitoredTireCount "The number of tires on Axle 12 which are monitored by the tire monitor controller. The axle number increments from front to rear of the vehicle when facing the …";
CM_ SG_ 2566670334 Axle1MonitoredTireCount "The number of tires on Axle 1 which are monitored by the tire monitor controller. The axle number increments from front to rear of the vehicle when facing the v…";
CM_ SG_ 2566670334 Axle2MonitoredTireCount "The number of tires on Axle 2 which are monitored by the tire monitor controller. The axle number increments from front to rear of the vehicle when facing the v…";
CM_ SG_ 2566670334 Axle3MonitoredTireCount "The number of tires on Axle 3 which are monitored by the tire monitor controller. The axle number increments from front to rear of the vehicle when facing the v…";
CM_ SG_ 2566670334 Axle4MonitoredTireCount "The number of tires on Axle 4 which are monitored by the tire monitor controller. The axle number increments from front to rear of the vehicle when facing the v…";
CM_ SG_ 2566670334 Axle5MonitoredTireCount "The number of tires on Axle 5 which are monitored by the tire monitor controller. The axle number increments from front to rear of the vehicle when facing the v…";
CM_ SG_ 2566670334 Axle6MonitoredTireCount "The number of tires on Axle 6 which are monitored by the tire monitor controller. The axle number increments from front to rear of the vehicle when facing the v…";
CM_ SG_ 2566670334 Axle7MonitoredTireCount "The number of tires on Axle 7 which are monitored by the tire monitor controller. The axle number increments from front to rear of the vehicle when facing the v…";
CM_ SG_ 2566670334 Axle8MonitoredTireCount "The number of tires on Axle 8 which are monitored by the tire monitor controller. The axle number increments from front to rear of the vehicle when facing the v…";
CM_ SG_ 2566670334 Axle9MonitoredTireCount "The number of tires on Axle 9 which are monitored by the tire monitor controller. The axle number increments from front to rear of the vehicle when facing the v…";
CM_ SG_ 2566670334 NumberofAxlesontheVehicle "The number of axles monitored for tire parameters. A maximum of 12 axles is defined.…";
CM_ SG_ 2566670334 NumberofTiresontheVehicle "The total number of tires monitored for tire parameters. A maximum of 250 tires is defined.…";
CM_ BO_ 2566670590 "Aftertreatment 2 Historical Information 2";
CM_ SG_ 2566670590 Atttt2SCRSstAvDstBtwSstCEvts "Indicates the average distance since last reset between cleaning events for the SCR system in bank 2.If the manufacturer allows this parameter to be reset, this…";
CM_ SG_ 2566670590 Atttt2SCRSstAvTBtwSstCEvts "Indicates the average time since last reset between cleaning events for the SCR system in bank 2.If the manufacturer allows this parameter to be reset, this tim…";
CM_ SG_ 2566670590 Atttt2SCRSstTtNSstCEvts "Total number of cleaning events that have occurred on the SCR system in bank 2 over the lifetime of the device.…";
CM_ SG_ 2566670590 Atttt2SCRSstTtNSstCItRqsts "Total number of cleaning inhibit requests on the SCR system in bank 2 by the operator over the lifetime of the device.…";
CM_ SG_ 2566670590 Atttt2SCRSstTtNSstCMRqsts "Total number of manual cleaning requests on the SCR system in bank 2 by the operator over the lifetime of the device.…";
CM_ SG_ 2566670590 Atttt2SCRSstTtSstCT "Total amount of time that a cleaning event has been active in the SCR system in bank 2 over the lifetime of the device.…";
CM_ BO_ 2566670846 "Aftertreatment 1 Historical Information 2";
CM_ SG_ 2566670846 Aftrtrtmnt1SCRSstmTtlClnngTm "Total amount of time that a cleaning event has been active in the SCR system in bank 1 over the lifetime of the device.…";
CM_ SG_ 2566670846 Atttt1SCRSstAvDstBtwSstCEvts "Indicates the average distance since last reset between cleaning events for the SCR system in bank 1.If the manufacturer allows this parameter to be reset, this…";
CM_ SG_ 2566670846 Atttt1SCRSstAvTBtwSstCEvts "Indicates the average time since last reset between cleaning events for the SCR system in bank 1. If the manufacturer allows this parameter to be reset, this ti…";
CM_ SG_ 2566670846 Atttt1SCRSstTtNSstCEvts "Total number of cleaning events that have occurred on the SCR system in bank 1 over the lifetime of the device.…";
CM_ SG_ 2566670846 Atttt1SCRSstTtNSstCItRqsts "Total number of cleaning inhibit requests on the SCR system in bank 1 by the operator over the lifetime of the device.…";
CM_ SG_ 2566670846 Atttt1SCRSstTtNSstCMRqsts "Total number of manual cleaning requests on the SCR system in bank 1 by the operator over the lifetime of the device.…";
CM_ SG_ 2566670846 TtlAftrtrtmntOprtngHrs "Accumulated time of operation of aftertreatment system.  Operating hours are accumulated only when there is air flowing thru the aftertreatment system.…";
CM_ BO_ 2566671102 "SCR System Cleaning";
CM_ SG_ 2566671102 Atttt1SCRSstCdtsNtMtAtvC "Indicates that SCR System 1 is not able to begin or continue an active cleaning event at the current engine operating conditions.00b = SCR System Cleaning not I…";
CM_ SG_ 2566671102 SCRSstCItdDtAtPdOId "Indicates the state of SCR system cleaning inhibition due to the accelerator pedal being off idle.00b = not inhibited01b = inhibited10b = reserved for SAE assig…";
CM_ SG_ 2566671102 SCRSstCItdDtLwExstTpt "Indicates the state of SCR system cleaning inhibition due to the exhaust temperature being too low.  This implies that the SCR system is too cold for cleaning.0…";
CM_ SG_ 2566671102 SCRSstCItdDtPtSstLt "Indicates the state of SCR system cleaning inhibition due to a permanent system lockout.00b = not inhibited01b = inhibited10b = reserved for SAE assignment11b =…";
CM_ SG_ 2566671102 SCRSstCItdDtVSpdAvAwdSpd "Indicates the state of SCR system cleaning inhibition due to the vehicle speed being above an allowed limit.00b = not inhibited01b = inhibited10b = reserved for…";
CM_ SG_ 2566671102 SCRSstCItdDtVSpdBwAwdSpd "Indicates the state of SCR system cleaning inhibition due to the vehicle speed being less than the allowed vehicle speed.00b = not inhibited01b = inhibited10b =…";
CM_ SG_ 2566671102 SCRSstmClnngAtmtInttnCnfgrtn "Indicates the configuration of SCR system cleaning automatic initiation.00b = not enabled01b = enabled10b = reserved for SAE assignment11b = not available…";
CM_ SG_ 2566671102 SCRSstmClnngInhtdDtClthDsnggd "Indicates the state of SCR system cleaning event inhibition due to the clutch being disengaged.00b = not inhibited01b = inhibited10b = reserved for SAE assignme…";
CM_ SG_ 2566671102 SCRSstmClnngInhtdDtEngnNtWrmdUp "Indicates the state of SCR system cleaning inhibition due to the engine not being warmed up.00b = not inhibited01b = inhibited10b = reserved for SAE assignment1…";
CM_ SG_ 2566671102 SCRSstmClnngInhtdDtInhtSwth "Indicates the state of SCR system cleaning inhibition due to the SCR system cleaning Inhibit Switch.00b = not inhibited01b = inhibited10b = reserved for SAE ass…";
CM_ SG_ 2566671102 SCRSstmClnngInhtdDtOtfNtrl "Indicates the state of SCR system cleaning inhibition due to the accelerator pedal being out of neutral.00b = not inhibited01b = inhibited10b = reserved for SAE…";
CM_ SG_ 2566671102 SCRSstmClnngInhtdDtPrkngBrkNtSt "Indicates the state of SCR system cleaning inhibition due to the parking brake being not set.00b = not inhibited01b = inhibited10b = reserved for SAE assignment…";
CM_ SG_ 2566671102 SCRSstmClnngInhtdDtPTOAtv "Indicates the state of SCR system cleaning inhibition due to the PTO being active.00b = not inhibited01b = inhibited10b = reserved for SAE assignment11b = not a…";
CM_ SG_ 2566671102 SCRSstmClnngInhtdDtSrvBrkAtv "Indicates the state of SCR system cleaning inhibition due to the service brake being active.00b = not inhibited01b = inhibited10b = reserved for SAE assignment1…";
CM_ SG_ 2566671102 SCRSstmClnngInhtdDtSstmFltAtv "Indicates the state of SCR system cleaning inhibition due to a system fault being active.00b = not inhibited01b = inhibited10b = reserved for SAE assignment11b …";
CM_ SG_ 2566671102 SCRSstmClnngInhtdDtSstmTmt "Indicates the state of SCR system cleaning inhibition due to a system timeout.00b = not inhibited01b = inhibited10b = reserved for SAE assignment11b = not avail…";
CM_ SG_ 2566671102 SCRSstmClnngInhtdDtTmprrSstmLkt "Indicates the state of SCR system cleaning inhibition due to a temporary system lockout.00b = not inhibited01b = inhibited10b = reserved for SAE assignment11b =…";
CM_ SG_ 2566671102 SCRSstmClnngInhtdStts "Indicates the state of SCR system cleaning inhibition.00b = not inhibited01b = inhibited10b = reserved for SAE assignment11b = not availableThis SPN indicates t…";
CM_ SG_ 2566671102 SCRSystemCleaningForcedStatus "Indicates the forced execution status of SCR system cleaning.000b = Not Active001b = Active – Forced by Switch (See SPN 3696)010b = Active – Forced by Service T…";
CM_ SG_ 2566671102 SCRSystemCleaningLampCommand "Command to control the SCR system cleaning lamp.000b = Off001b = On – solid010b = reserved for SAE assignment 011b = reserved for SAE assignment100b = On – fast…";
CM_ SG_ 2566671102 SCRSystemCleaningStatus "Indicates the state of SCR system cleaning.  This is an aggregate of bank 1 and bank 2.  It is a system status and not individual bank status.00b = not active01…";
CM_ BO_ 2566671358 "Electronic Engine Controller 17";
CM_ SG_ 2566671358 CylinderFuelRate "Cylinder fuel rate shall indicate the amount of fuel injected into the cylinder for combustion during the most recent intake stroke of the engine.NOTE: Cylinder…";
CM_ SG_ 2566671358 EngineExhaustFlowRate "Engine Exhaust Flow Rate shall indicate the measured/calculated exhaust gas mass flow upstream of the aftertreatment system.Engine Exhaust Flow Rate shall be ca…";
CM_ SG_ 2566671358 PEMSEngineFuelMassFlowRate "PEMS Engine Fuel Mass Flow Rate shall indicate the amount of fuel consumed by the engine per unit of time (does not include fuel injected directly into the afte…";
CM_ SG_ 2566671358 VehicleFuelRate "Vehicle Fuel Rate shall indicate the amount of fuel consumed by the engine and fuel injected directly into the aftertreatment system per unit of time, in grams …";
CM_ BO_ 2566671614 "SCR Operator Inducement Information 3";
CM_ SG_ 2566671614 NSCROptIdtOvdEvtsR "During an operator inducement event, the operator may be able to override the inducement multiple times. This parameter indicates the remaining number of times …";
CM_ SG_ 2566671614 SCROprtrIndmntOvrrdEnl "Indicates if an operator inducement derate is allowed to be overridden.Note: Inducement override is only allowed under certain conditions approved by EPA/ARB.00…";
CM_ SG_ 2566671614 SCROprtrIndmntOvrrdTmRmnng "This parameter is used to indicate the time remaining during an operator inducement override event.  See also SPN 7344 for an alternate SLOT.When an operator in…";
CM_ SG_ 2566671614 TtlNmrfSCROprtrIndmntOvrrdEvnts "Indicates total number of operator inducement override events activated throughout the lifetime of engine operation.This number will remain at the maximum value…";
CM_ BO_ 2566671870 "Aftertreatment 2 SCR Dosing System Information 3";
CM_ SG_ 2566671870 Aftrtrtmnt2DslExhstFldDsr2Prssr "The SCR doser 2 diesel exhaust fluid gage pressure (measured closest to dosing valve) for aftertreatment system 2 (exhaust bank ). This is the gage equivalent t…";
CM_ SG_ 2566671870 Aftrtrtmnt2DslExhstFldDsrPrssr "The SCR dosing diesel exhaust fluid gage pressure (measured closest to dosing valve) for aftertreatment system 2 (exhaust bank 2). This is the gage equivalent t…";
CM_ SG_ 2566671870 Atttt2DsExstFdDs2AstPss "The SCR doser 2 diesel exhaust fluid absolute pressure (measured closest to dosing valve) for aftertreatment system 2 (exhaust bank 2).…";
CM_ SG_ 2566671870 Atttt2DsExstFdDs2Tpt "The temperature (measured closest to doser valve) of the second DEF doser unit for aftertreatment system 2 (exhaust bank 2).…";
CM_ BO_ 2566672126 "Aftertreatment 1 SCR Dosing System Information 3";
CM_ SG_ 2566672126 Aftrtrtmnt1DslExhstFldDsr2Prssr "The SCR doser 2 diesel exhaust fluid gage pressure (measured closest to dosing valve) for aftertreatment system 1 (exhaust bank 1). This is the gage equivalent …";
CM_ SG_ 2566672126 Aftrtrtmnt1DslExhstFldDsrPrssr "The SCR dosing diesel exhaust fluid gage pressure (measured closest to dosing valve) for aftertreatment system 1 (exhaust bank 1). This is the gage equivalent t…";
CM_ SG_ 2566672126 Atttt1DsExstFdDs2AstPss "The SCR doser 2 diesel exhaust fluid absolute pressure (measured closest to dosing valve) for aftertreatment system 1 (exhaust bank 1).…";
CM_ SG_ 2566672126 Atttt1DsExstFdDs2Tpt "The temperature (measured closest to dosing valve) of the second DEF dosing unit for aftertreatment system 1 (exhaust bank 1).…";
CM_ BO_ 2566672382 "Payload Weight Sensor Information";
CM_ SG_ 2566672382 PayloadWeightSensor1Status "Status of the payload system sensor 1 measurement.00b = Sensor fully functional01b = Sensor degraded10b = Error (Sensor failed)11b = Not available…";
CM_ SG_ 2566672382 PayloadWeightSensor2Status "Status of the payload system sensor 2 measurement.00b = Sensor fully functional01b = Sensor degraded10b = Error (Sensor failed)11b = Not available…";
CM_ SG_ 2566672382 PayloadWeightSensor3Status "Status of the payload system sensor 3 measurement.00b = Sensor fully functional01b = Sensor degraded10b = Error (Sensor failed)11b = Not available…";
CM_ SG_ 2566672382 PayloadWeightSensor4Status "Status of the payload system sensor 4 measurement.00b = Sensor fully functional01b = Sensor degraded10b = Error (Sensor failed)11b = Not available…";
CM_ SG_ 2566672382 PayloadWeightSensor5Status "Status of the payload system sensor 5 measurement.00b = Sensor fully functional01b = Sensor degraded10b = Error (Sensor failed)11b = Not available…";
CM_ SG_ 2566672382 PayloadWeightSensor6Status "Status of the payload system sensor 6 measurement.00b = Sensor fully functional01b = Sensor degraded10b = Error (Sensor failed)11b = Not available…";
CM_ SG_ 2566672382 PayloadWeightSensor7Status "Status of the payload system sensor 7 measurement.00b = Sensor fully functional01b = Sensor degraded10b = Error (Sensor failed)11b = Not available…";
CM_ SG_ 2566672382 PayloadWeightSensor8Status "Status of the payload system sensor 8 measurement.00b = Sensor fully functional01b = Sensor degraded10b = Error (Sensor failed)11b = Not available…";
CM_ BO_ 2566672638 "Payload System Status";
CM_ SG_ 2566672638 DeliveredPayloadConfidence "The level of confidence of the delivered payload weight measurement. Higher confidence values indicate greater probability the delivered payload weight is the a…";
CM_ SG_ 2566672638 DeliveredPayloadWeight "The delivered payload mass during the last haul cycle. This is the amount of material moved and delivered by a machine is a key work cycle parameter.Delivered p…";
CM_ SG_ 2566672638 HaulCycleCount "A counter incremented by 1 with each instance of a new haul cycle, defined as a dump to dump cycle. The counter shall increment from 0 to 64255, rolling over to…";
CM_ SG_ 2566672638 HaulModeStatus "The current operating state of the haul cycle.0000b = Not in Haul Mode0001b = Loading -- Payload is being added to the machine0010b = Approaching Loaded -- Mach…";
CM_ SG_ 2566672638 PldDlvrTrnstnStts "The current state of the payload delivery transaction.When a transaction is in progress, a receiving node may monitor Haul Cycle Count (SPN 6847) and Delivered …";
CM_ BO_ 2566673406 "Engine Gaseous Leakage Information";
CM_ SG_ 2566673406 GasLeakageDetection1Pressure "Pressure measured in gas leakage detection point 1. Measured media is of the gas, meaning it could be air, inert gas, fuel air mixture or charge air mixture, de…";
CM_ SG_ 2566673406 GasLeakageDetection2Pressure "Pressure measured in gas leakage detection point 2. Measured media is of the gas, meaning it could be air, inert gas, fuel air mixture or charge air mixture, de…";
CM_ SG_ 2566673406 GasLeakageDetection3Pressure "Pressure measured in gas leakage detection point 3. Measured media is of the gas, meaning it could be air, inert gas, fuel air mixture or charge air mixture, de…";
CM_ SG_ 2566673406 GssFlLkg1Cnntrtn "Percentage of detected gaseous fuel leak compared to the lower explosion limit (LEL). 100% means the measured value is on the lower explosion limit. 0% means no…";
CM_ SG_ 2566673406 GssFlLkg2Cnntrtn "Percentage of detected gaseous fuel leak compared to the lower explosion limit (LEL). 100% means the measured value is on the lower explosion limit. 0% means no…";
CM_ SG_ 2566673406 GssFlLkg3Cnntrtn "Percentage of detected gaseous fuel leak compared to the lower explosion limit (LEL). 100% means the measured value is on the lower explosion limit. 0% means no…";
CM_ BO_ 2566674174 "SCR Operator Inducement Information 2";
CM_ SG_ 2566674174 AftrtrtmntSCRMlfntnTm "Indicates the amount of time an error condition has been active due to a malfunction in the Aftertreatment SCR system.The source of the malfunction condition co…";
CM_ SG_ 2566674174 SCROperatorInducementTotalTime "Indicates the time that operator inducement has been active. This will accumulate over the life of the product and will never be reset.…";
CM_ BO_ 2566674430 "SCR Operator Inducement Information 1";
CM_ SG_ 2566674430 DslExhstFldQltMlfntnTm "Indicates the amount of time an error has been active due to detection of low Diesel Exhaust Fluid Quality. This will accumulate over the life of the product an…";
CM_ SG_ 2566674430 DslExhstFldTnk1EmptTm "Indicates the time the Diesel Exhaust Fluid Tank 1 Level is indicated as empty. This will accumulate over the life of the product and will never be reset.…";
CM_ BO_ 2566674686 "Turbocharger Information 7";
CM_ SG_ 2566674686 EngnTrhrgr2LOlPrssr "Gage pressure of oil in the lubrication system for the 2nd turbocharger.…";
CM_ SG_ 2566674686 EngnTrhrgr2OlTmprtr "Temperature of the lubricant for the second turbocharger.…";
CM_ SG_ 2566674686 EngnTrhrgr3LOlPrssr "Gage pressure of oil in the lubrication system for the 3rd turbocharger.…";
CM_ SG_ 2566674686 EngnTrhrgr4LOlPrssr "Gage pressure of oil in the lubrication system for the 4th turbocharger.…";
CM_ BO_ 2566675966 "High Voltage Energy Storage 1 Configuration";
CM_ SG_ 2566675966 HVES1CellMaximumVoltageLimit "Per the HVES manufacturer, this is the maximum cell voltage for High Voltage Energy Storage 1 pack (or system) operation.  Operating above this value may damage…";
CM_ SG_ 2566675966 HVES1CellMinimumVoltageLimit "Per the HVES manufacturer, this is the minimum cell voltage for High Voltage Energy Storage 1 pack (or system) operation.  Operating below this value may damage…";
CM_ SG_ 2566675966 HVES1NominalVoltage "Per the HVES manufacturer, this is the nominal operating voltage of the High Voltage Energy Storage 1 pack (or system), e.g. “300V” or “600V”.…";
CM_ SG_ 2566675966 HVES1RmmnddMnmmOprtngTmprtr "Per the HVES manufacturer, this is the recommended minimum temperature for High Voltage Energy Storage 1 pack (or system) operation.  Operating below this value…";
CM_ SG_ 2566675966 HVES1RmmnddMnmmOprtngVltg "Per the HVES manufacturer, this is the minimum recommended voltage level for High Voltage Energy Storage 1 pack (or system) operation.  Operating below this val…";
CM_ SG_ 2566675966 HVES1RmmnddMnmmSttOfChrg "Per the HVES manufacturer, this is the recommended minimum state of charge for High Voltage Energy Storage 1 pack (or system) operation.  Operating below this v…";
CM_ SG_ 2566675966 HVES1RmmnddMxmmOprtngTmprtr "Per the HVES manufacturer, this is the recommended maximum temperature for High Voltage Energy Storage 1 pack (or system) operation.  Operating above this value…";
CM_ SG_ 2566675966 HVES1RmmnddMxmmOprtngVltg "Per the HVES manufacturer, this is the maximum recommended voltage level for High Voltage Energy Storage 1 pack (or system) operation.  Operating above this val…";
CM_ SG_ 2566675966 HVES1RmmnddMxmmSttOfChrg "Per the HVES manufacturer, this is the recommended maximum state of charge for High Voltage Energy Storage 1 pack (or system) operation.  Operating above this v…";
CM_ BO_ 2566687742 "Aftertreatment 1 Particulate Sensor Information 2";
CM_ SG_ 2566687742 Aftrtrtmnt1PrtltSnsrDttnStts "Detection status of the particulate sensor0000b = Initialization for particulate matter detection0001b = Waiting for dew point (see SPN 6784)0010b = Particulate…";
CM_ SG_ 2566687742 Aftrtrtmnt1PrtltSnsrHtrRsstn "The resistance of the particulate sensor heater.…";
CM_ SG_ 2566687742 Aftrtrtmnt1PrtltSnsrMxmmRsstn "This is the maximum resistance that the particulate sensor can measure.…";
CM_ SG_ 2566687742 Aftrtrtmnt1PrtltSnsrPwrSppl "State signal which indicates when the Aftertreatment 1 particulate sensor has power applied to it. Note that this is referring to the power supplied to the sens…";
CM_ SG_ 2566687742 Aftrtrtmnt1PrtltSnsrTmprtr "Temperature of the particulate sensor.…";
CM_ SG_ 2566687742 Atttt1PttSsRtFdCt "This is the number of times that the particulate sensor regeneration process has been attempted but failed to complete this power cycle.…";
CM_ BO_ 2566687998 "Aftertreatment 1 Particulate Sensor Information 1";
CM_ SG_ 2566687998 Aftrtrtmnt1PrtltSnsrAtvAmltnTm "This is the amount of time since the last successful regeneration completed.  The sensor has been accumulating particulate matter since that time.…";
CM_ SG_ 2566687998 Aftrtrtmnt1PrtltSnsrHtrStt "The states of the particulate sensor heater.  The heater will change states from 11b to 10b, 10b to 01b, and 01b to 00b in a typical heating event.00b = Heater …";
CM_ SG_ 2566687998 Aftrtrtmnt1PrtltSnsrRgnrtnStt "Indicates if the particulate sensor regeneration is currently active, and if so, the reason for the regeneration.0000b = Regeneration is not active0001b = Regne…";
CM_ SG_ 2566687998 Aftrtrtmnt1PrtltSnsrRgnrtnStts "The status of the most recent attempt of this power cycle to activate the particulate sensor regeneration process. This will not be updated until the regenerati…";
CM_ SG_ 2566687998 Aftrtrtmnt1PrtltSnsrRsstn "This sensor is located in the exhaust stream somewhere after the DPF, but not necessarily immediately after the DPF.  It provides a resistance value that can be…";
CM_ SG_ 2566687998 Atttt1PttSsTBtwRts "This is the time between the last two successful regenerations of the particulate sensor for the current power cycle. This parameter reflects the time when the …";
CM_ BO_ 2566689278 "Engine Exhaust NOx";
CM_ SG_ 2566689278 EngineExhaustDesiredNOx "Desired NOx concentration in the engine exhaust, prior to any aftertreatment of the exhaust.…";
CM_ SG_ 2566689278 EngineExhaustNOx "Calculated NOx concentration for the total engine exhaust, prior to any aftertreatment of the exhaust.  This parameter is primarily intended for engines that ha…";
CM_ SG_ 2566689278 EngnExhstNOxSnsrPwrSppl "State signal which indicates when the engine exhaust NOx sensor power supply driver output is being driven. On means the ECU is powering the engine exhaust NOx …";
CM_ BO_ 2566689534 "Air Fuel Ratio";
CM_ SG_ 2566689534 EngineMainChamberAirFuelRatio "Actual air to fuel ratio of the charge entering the cylinder main chamber.…";
CM_ SG_ 2566689534 EnginePrechamberAirFuelRatio "Actual air to fuel ratio of the charge entering the cylinder prechamber.…";
CM_ SG_ 2566689534 EngnMnChmrDsrdArFlRt "Desired air to fuel ratio of the charge entering the cylinder main chamber.…";
CM_ SG_ 2566689534 EngnPrhmrDsrdArFlRt "Desired air to fuel ratio of the charge entering the cylinder prechamber.…";
CM_ BO_ 2566689790 "Gaseous Fuel Pressure 2";
CM_ SG_ 2566689790 EngnMnChmrFlAsltPrssr "Absolute pressure of the gaseous fuel for the main chamber of the cylinder. This parameter is intended for applications, which use a pre and main chamber fuel s…";
CM_ SG_ 2566689790 EngnMnChmrFlDsrdAsltPrssr "Desired absolute pressure of the gaseous fuel for the main chamber of the cylinder. This parameter is intended for applications with pre and main chamber fuel s…";
CM_ SG_ 2566689790 EngnPrhmrFlAsltPrssr "Absolute pressure of the gaseous fuel for the separate cylinder pre-chamber rail. This parameter is intended for applications, which use a pre and main chamber …";
CM_ SG_ 2566689790 EngnPrhmrFlDsrdAsltPrssr "Desired absolute pressure of the gaseous fuel in the separate cylinder pre-chamber rail. This parameter is intended for applications with pre and main chamber f…";
CM_ BO_ 2566690046 "Aftertreatment System Abuse Information";
CM_ SG_ 2566690046 AfterrunCompleteThisCycle "Indication of after-run routine completion in the current power cycle.Complete This Cycle parameters are used to indicate to the engine controller that is power…";
CM_ SG_ 2566690046 AttttDsExstFdDsCdwCptLstC "Indication of cooldown routine completion in the previous power cycle.00b = Not complete01b = Complete10b = Error11b = Not SupportedNote:  One purpose for track…";
CM_ SG_ 2566690046 AttttDsExstFdDsCdwCptTsC "Indication of cooldown routine completion in the current power cycle.Complete This Cycle parameters are used to indicate to the engine controller that is poweri…";
CM_ SG_ 2566690046 AttttDsExstFdDsCdwItptCt "Non-volatile record of the number of interrupted cooldown routines since the last clear event.  The counter shall be reset by PGN 56832 request.…";
CM_ SG_ 2566690046 AttttDsExstFdDsPCptLstC "Indication of purge routine completion in the previous power cycle00b = Not complete01b = Complete10b = Error11b = Not SupportedNote:  One purpose for tracking …";
CM_ SG_ 2566690046 AttttDsExstFdDsPCptTsC "Indication of purge routine completion in the current power cycle.Complete This Cycle parameters are used to indicate to the engine controller that is powering …";
CM_ SG_ 2566690046 AttttDsExstFdDsPItptCt "Non-volatile record of the number of interrupted purge routines since the last clear event.  The counter shall be reset by PGN 56832 request.…";
CM_ BO_ 2566690558 "Engine Information 2";
CM_ SG_ 2566690558 EngineCommonRailOilPressure "Gage pressure of oil in common rail's lubrication system as provided by oil pump.…";
CM_ SG_ 2566690558 EngineExhaustPressure2 "Gage pressure of the exhaust gasses as measured at the turbine intake of the turbocharger of exhaust bank 2. See SPN 1209 for exhaust bank 1.…";
CM_ SG_ 2566690558 EngnCmmnRlOlAsltPrssr "Absolute pressure of oil in common rail's lubrication system as provided by oil pump.…";
CM_ SG_ 2566690558 EngnExhstPrssr1ExtnddRng "Gage pressure of the exhaust gasses as measured at the turbine intake of the turbocharger. This SPN to be used for inline engines or exhaust bank 1 of multiple …";
CM_ SG_ 2566690558 EOFtItPssHRstExtddR "Gage pressure of the engine oil before the oil reaches the oil filter. See SPN 1208 for alternate resolution.…";
CM_ BO_ 2566690814 "Electronic Steering Control 2";
CM_ SG_ 2566690814 CircleSteerModeActuatorState "Signal which indicates the current state of the actuator that control the circle steering mode00b = Circle Steer Mode actuator inactive01b = Circle Steer Mode a…";
CM_ SG_ 2566690814 CrabSteerModeActuatorState "Signal which indicates the current state of the actuator that control the crab steering mode00b = Crab Steer Mode actuator inactive01b = Crab Steer Mode actuato…";
CM_ SG_ 2566690814 FrontSteeringAxleCenteredStatus "The status of the front steering axle being centered. The axle is centered if the axle's centerline is parallel to the vehicle's X-axis, where the vehicle's X-a…";
CM_ SG_ 2566690814 RearSteeringAxleCenteredStatus "The status of the rear steering axle being centered. The axle is centered if the axle's centerline is parallel to the vehicle's X-axis, where the vehicle's X-ax…";
CM_ SG_ 2566690814 SteeringModeSwitch "Switch used as an input to the electronic steering controller to determine the operator's requested steering mode000b = 2 Wheel Steer Mode001b = Circle Steer Mo…";
CM_ SG_ 2566690814 StrngCntrllrECUTmprtr "Temperature of the steering controller ECU…";
CM_ SG_ 2566690814 Wheel2SteerActuatorState "The current state of the actuator that control the 2 wheel steering mode00b = 2 Wheel Steer actuator inactive01b = 2 Wheel Steer actuator active10b = Error11b =…";
CM_ SG_ 2566690814 Wheel4SteerActuatorState "Signal which indicates the current state of the actuator that control the 4 wheel steering mode00b = 4 Wheel Steer actuator inactive01b = 4 Wheel Steer actuator…";
CM_ BO_ 2566691326 "Assembly Unit Identification";
CM_ SG_ 2566691326 AssemblyUnitIdentification "A combination of alphanumeric characters representing the Identification number of an assembly unit installed on a component.  Multiple assembly unit IDs can be…";
CM_ SG_ 2566691326 NmrfAssmlUntIdntftnFlds "Number of Assembly Unit Identification designators represented in the Assembly Unit Identification parameter group.…";
CM_ BO_ 2566691582 "Joystick 3 Lamp Status";
CM_ SG_ 2566691582 Joystick3Lamp10Status "Report the actual value of Joystick 3 Lamp 1000b = Off01b = On10b = Flashing11b = Not available…";
CM_ SG_ 2566691582 Joystick3Lamp1Status "Report the actual value of Joystick 3 Lamp 100b = Off01b = On10b = Flashing11b = Not available…";
CM_ SG_ 2566691582 Joystick3Lamp2Status "Report the actual value of Joystick 3 Lamp 200b = Off01b = On10b = Flashing11b = Not available…";
CM_ SG_ 2566691582 Joystick3Lamp3Status "Report the actual value of Joystick 3 Lamp 300b = Off01b = On10b = Flashing11b = Not available…";
CM_ SG_ 2566691582 Joystick3Lamp4Status "Report the actual value of Joystick 3 Lamp 400b = Off01b = On10b = Flashing11b = Not available…";
CM_ SG_ 2566691582 Joystick3Lamp5Status "Report the actual value of Joystick 3 Lamp 500b = Off01b = On10b = Flashing11b = Not available…";
CM_ SG_ 2566691582 Joystick3Lamp6Status "Report the actual value of Joystick 3 Lamp 600b = Off01b = On10b = Flashing11b = Not available…";
CM_ SG_ 2566691582 Joystick3Lamp7Status "Report the actual value of Joystick 3 Lamp 700b = Off01b = On10b = Flashing11b = Not available…";
CM_ SG_ 2566691582 Joystick3Lamp8Status "Report the actual value of Joystick 3 Lamp 800b = Off01b = On10b = Flashing11b = Not available…";
CM_ SG_ 2566691582 Joystick3Lamp9Status "Report the actual value of Joystick 3 Lamp 900b = Off01b = On10b = Flashing11b = Not available…";
CM_ BO_ 2566691838 "Joystick 2 Lamp Status";
CM_ SG_ 2566691838 Joystick2Lamp10Status "Report the actual value of Joystick 2 Lamp 1000b = Off01b = On10b = Flashing11b = Not available…";
CM_ SG_ 2566691838 Joystick2Lamp1Status "Report the actual value of Joystick 2 Lamp 100b = Off01b = On10b = Flashing11b = Not available…";
CM_ SG_ 2566691838 Joystick2Lamp2Status "Report the actual value of Joystick 2 Lamp 200b = Off01b = On10b = Flashing11b = Not available…";
CM_ SG_ 2566691838 Joystick2Lamp3Status "Report the actual value of Joystick 2 Lamp 300b = Off01b = On10b = Flashing11b = Not available…";
CM_ SG_ 2566691838 Joystick2Lamp4Status "Report the actual value of Joystick 2 Lamp 400b = Off01b = On10b = Flashing11b = Not available…";
CM_ SG_ 2566691838 Joystick2Lamp5Status "Report the actual value of Joystick 2 Lamp 500b = Off01b = On10b = Flashing11b = Not available…";
CM_ SG_ 2566691838 Joystick2Lamp6Status "Report the actual value of Joystick 2 Lamp 600b = Off01b = On10b = Flashing11b = Not available…";
CM_ SG_ 2566691838 Joystick2Lamp7Status "Report the actual value of Joystick 2 Lamp 700b = Off01b = On10b = Flashing11b = Not available…";
CM_ SG_ 2566691838 Joystick2Lamp8Status "Report the actual value of Joystick 2 Lamp 800b = Off01b = On10b = Flashing11b = Not available…";
CM_ SG_ 2566691838 Joystick2Lamp9Status "Report the actual value of Joystick 2 Lamp 900b = Off01b = On10b = Flashing11b = Not available…";
CM_ BO_ 2566692094 "Joystick 1 Lamp Status";
CM_ SG_ 2566692094 Joystick1Lamp10Status "Report the actual value of Joystick 1 Lamp 1000b = Off01b = On10b = Flashing11b = Not available…";
CM_ SG_ 2566692094 Joystick1Lamp1Status "Report the actual value of Joystick 1 Lamp 100b = Off01b = On10b = Flashing11b = Not available…";
CM_ SG_ 2566692094 Joystick1Lamp2Status "Report the actual value of Joystick 1 Lamp 200b = Off01b = On10b = Flashing11b = Not available…";
CM_ SG_ 2566692094 Joystick1Lamp3Status "Report the actual value of Joystick 1 Lamp 300b = Off01b = On10b = Flashing11b = Not available…";
CM_ SG_ 2566692094 Joystick1Lamp4Status "Report the actual value of Joystick 1 Lamp 400b = Off01b = On10b = Flashing11b = Not available…";
CM_ SG_ 2566692094 Joystick1Lamp5Status "Report the actual value of Joystick 1 Lamp 500b = Off01b = On10b = Flashing11b = Not available…";
CM_ SG_ 2566692094 Joystick1Lamp6Status "Report the actual value of Joystick 1 Lamp 600b = Off01b = On10b = Flashing11b = Not available…";
CM_ SG_ 2566692094 Joystick1Lamp7Status "Report the actual value of Joystick 1 Lamp 700b = Off01b = On10b = Flashing11b = Not available…";
CM_ SG_ 2566692094 Joystick1Lamp8Status "Report the actual value of Joystick 1 Lamp 800b = Off01b = On10b = Flashing11b = Not available…";
CM_ SG_ 2566692094 Joystick1Lamp9Status "Report the actual value of Joystick 1 Lamp 900b = Off01b = On10b = Flashing11b = Not available…";
CM_ BO_ 2566692862 "Dash Display 2";
CM_ SG_ 2566692862 DisplayRemainPowered "Indicates the ECU needs the display (i.e. monitor device) to continue to remain powered after ignition key off. An ECU would use this when the ECU needs the dis…";
CM_ SG_ 2566692862 EngineFuel2Tank1Level "Fuel level in tank 1 containing the second fuel type..…";
CM_ SG_ 2566692862 EngineFuel2Tank2Level "Fuel level in tank 2 containing the second fuel type.…";
CM_ SG_ 2566692862 EngineFuel2Tank3Level "Fuel level in tank 3 containing the second fuel type.…";
CM_ SG_ 2566692862 EngineFuel2Tank4Level "Fuel level in tank 4 containing the second fuel type.…";
CM_ SG_ 2566692862 EngineOilLevelHighLow "Conveys the amount of current volume of engine oil compared to recommended volume. Positive values indicate overfill.  Zero means the engine oil is filled to th…";
CM_ SG_ 2566692862 EngnOlFltrDffrntlPrssrExtnddRng "Change in engine oil differential pressure measured across the oil filter element. The differential pressure is the measured as the pressure at the filter intak…";
CM_ BO_ 2566697470 "Engine Ignition Control Module Status";
CM_ SG_ 2566697470 EngnIgntnCntrlMdl1Stt "This parameter is used to indicate the current state of Engine Ignition Control Module 1.000b = Disabled (by user)001b = Shutdown (due to alarm)010b = Stalled (…";
CM_ SG_ 2566697470 EngnIgntnCntrlMdl1Tmprtr "Measured internal temperature of the Engine Ignition Control Module 1 circuitry.…";
CM_ SG_ 2566697470 EngnIgntnCntrlMdl2Stt "This parameter is used to indicate the current state of Engine Ignition Control Module 2.000b = Disabled (by user)001b = Shutdown (due to alarm)010b = Stalled (…";
CM_ SG_ 2566697470 EngnIgntnCntrlMdl2Tmprtr "Measured internal temperature of the Engine Ignition Control Module 2 circuitry.…";
CM_ BO_ 2566697726 "Switched Power Output Current";
CM_ SG_ 2566697726 SwitchedOutput10Current "Measured electrical current flowing out of Power Distribution Module (PDM) Switched Output #10.…";
CM_ SG_ 2566697726 SwitchedOutput11Current "Measured electrical current flowing out of Power Distribution Module (PDM) Switched Output #11.…";
CM_ SG_ 2566697726 SwitchedOutput12Current "Measured electrical current flowing out of Power Distribution Module (PDM) Switched Output #12.…";
CM_ SG_ 2566697726 SwitchedOutput13Current "Measured electrical current flowing out of Power Distribution Module (PDM) Switched Output #13.…";
CM_ SG_ 2566697726 SwitchedOutput14Current "Measured electrical current flowing out of Power Distribution Module (PDM) Switched Output #14.…";
CM_ SG_ 2566697726 SwitchedOutput15Current "Measured electrical current flowing out of Power Distribution Module (PDM) Switched Output #15.…";
CM_ SG_ 2566697726 SwitchedOutput16Current "Measured electrical current flowing out of Power Distribution Module (PDM) Switched Output #16.…";
CM_ SG_ 2566697726 SwitchedOutput17Current "Measured electrical current flowing out of Power Distribution Module (PDM) Switched Output #17.…";
CM_ SG_ 2566697726 SwitchedOutput18Current "Measured electrical current flowing out of Power Distribution Module (PDM) Switched Output #18.…";
CM_ SG_ 2566697726 SwitchedOutput19Current "Measured electrical current flowing out of Power Distribution Module (PDM) Switched Output #19.…";
CM_ SG_ 2566697726 SwitchedOutput1Current "Measured electrical current flowing out of Power Distribution Module (PDM) Switched Output #1.…";
CM_ SG_ 2566697726 SwitchedOutput20Current "Measured electrical current flowing out of Power Distribution Module (PDM) Switched Output #20.…";
CM_ SG_ 2566697726 SwitchedOutput21Current "Measured electrical current flowing out of Power Distribution Module (PDM) Switched Output #21.…";
CM_ SG_ 2566697726 SwitchedOutput22Current "Measured electrical current flowing out of Power Distribution Module (PDM) Switched Output #22.…";
CM_ SG_ 2566697726 SwitchedOutput23Current "Measured electrical current flowing out of Power Distribution Module (PDM) Switched Output #23.…";
CM_ SG_ 2566697726 SwitchedOutput24Current "Measured electrical current flowing out of Power Distribution Module (PDM) Switched Output #24.…";
CM_ SG_ 2566697726 SwitchedOutput25Current "Measured electrical current flowing out of Power Distribution Module (PDM) Switched Output #25.…";
CM_ SG_ 2566697726 SwitchedOutput26Current "Measured electrical current flowing out of Power Distribution Module (PDM) Switched Output #26.…";
CM_ SG_ 2566697726 SwitchedOutput27Current "Measured electrical current flowing out of Power Distribution Module (PDM) Switched Output #27.…";
CM_ SG_ 2566697726 SwitchedOutput28Current "Measured electrical current flowing out of Power Distribution Module (PDM) Switched Output #28.…";
CM_ SG_ 2566697726 SwitchedOutput29Current "Measured electrical current flowing out of Power Distribution Module (PDM) Switched Output #29.…";
CM_ SG_ 2566697726 SwitchedOutput2Current "Measured electrical current flowing out of Power Distribution Module (PDM) Switched Output #2.…";
CM_ SG_ 2566697726 SwitchedOutput30Current "Measured electrical current flowing out of Power Distribution Module (PDM) Switched Output #30.…";
CM_ SG_ 2566697726 SwitchedOutput31Current "Measured electrical current flowing out of Power Distribution Module (PDM) Switched Output #31.…";
CM_ SG_ 2566697726 SwitchedOutput32Current "Measured electrical current flowing out of Power Distribution Module (PDM) Switched Output #32.…";
CM_ SG_ 2566697726 SwitchedOutput3Current "Measured electrical current flowing out of Power Distribution Module (PDM) Switched Output #3.…";
CM_ SG_ 2566697726 SwitchedOutput4Current "Measured electrical current flowing out of Power Distribution Module (PDM) Switched Output #4.…";
CM_ SG_ 2566697726 SwitchedOutput5Current "Measured electrical current flowing out of Power Distribution Module (PDM) Switched Output #5.…";
CM_ SG_ 2566697726 SwitchedOutput6Current "Measured electrical current flowing out of Power Distribution Module (PDM) Switched Output #6.…";
CM_ SG_ 2566697726 SwitchedOutput7Current "Measured electrical current flowing out of Power Distribution Module (PDM) Switched Output #7.…";
CM_ SG_ 2566697726 SwitchedOutput8Current "Measured electrical current flowing out of Power Distribution Module (PDM) Switched Output #8.…";
CM_ SG_ 2566697726 SwitchedOutput9Current "Measured electrical current flowing out of Power Distribution Module (PDM) Switched Output #9.…";
BA_DEF_ SG_  "SPN" INT 0 524287;
BA_DEF_ BO_  "VFrameFormat" ENUM  "StandardCAN","ExtendedCAN","reserved","J1939PG";
BA_DEF_DEF_  "SPN" 0;
BA_DEF_DEF_  "VFrameFormat" "J1939PG";
BA_ "SPN" SG_ 2566642942 EnableStatusofDoor21 8527;
BA_ "SPN" SG_ 2566642942 EnableStatusofDoor22 8530;
BA_ "SPN" SG_ 2566642942 EnableStatusofDoor23 8533;
BA_ "SPN" SG_ 2566642942 EnableStatusofDoor24 8536;
BA_ "SPN" SG_ 2566642942 EnableStatusofDoor25 8539;
BA_ "SPN" SG_ 2566642942 EnableStatusofDoor26 8542;
BA_ "SPN" SG_ 2566642942 EnableStatusofDoor27 8545;
BA_ "SPN" SG_ 2566642942 EnableStatusofDoor28 8548;
BA_ "SPN" SG_ 2566642942 EnableStatusofDoor29 8551;
BA_ "SPN" SG_ 2566642942 EnableStatusofDoor30 8554;
BA_ "SPN" SG_ 2566642942 LockStatusofDoor21 8525;
BA_ "SPN" SG_ 2566642942 LockStatusofDoor22 8528;
BA_ "SPN" SG_ 2566642942 LockStatusofDoor23 8531;
BA_ "SPN" SG_ 2566642942 LockStatusofDoor24 8534;
BA_ "SPN" SG_ 2566642942 LockStatusofDoor25 8537;
BA_ "SPN" SG_ 2566642942 LockStatusofDoor26 8540;
BA_ "SPN" SG_ 2566642942 LockStatusofDoor27 8543;
BA_ "SPN" SG_ 2566642942 LockStatusofDoor28 8546;
BA_ "SPN" SG_ 2566642942 LockStatusofDoor29 8549;
BA_ "SPN" SG_ 2566642942 LockStatusofDoor30 8552;
BA_ "SPN" SG_ 2566642942 OpenStatusofDoor21 8526;
BA_ "SPN" SG_ 2566642942 OpenStatusofDoor22 8529;
BA_ "SPN" SG_ 2566642942 OpenStatusofDoor23 8532;
BA_ "SPN" SG_ 2566642942 OpenStatusofDoor24 8535;
BA_ "SPN" SG_ 2566642942 OpenStatusofDoor25 8538;
BA_ "SPN" SG_ 2566642942 OpenStatusofDoor26 8541;
BA_ "SPN" SG_ 2566642942 OpenStatusofDoor27 8544;
BA_ "SPN" SG_ 2566642942 OpenStatusofDoor28 8547;
BA_ "SPN" SG_ 2566642942 OpenStatusofDoor29 8550;
BA_ "SPN" SG_ 2566642942 OpenStatusofDoor30 8553;
BA_ "SPN" SG_ 2566643198 EnableStatusofDoor11 8497;
BA_ "SPN" SG_ 2566643198 EnableStatusofDoor12 8500;
BA_ "SPN" SG_ 2566643198 EnableStatusofDoor13 8503;
BA_ "SPN" SG_ 2566643198 EnableStatusofDoor14 8506;
BA_ "SPN" SG_ 2566643198 EnableStatusofDoor15 8509;
BA_ "SPN" SG_ 2566643198 EnableStatusofDoor16 8512;
BA_ "SPN" SG_ 2566643198 EnableStatusofDoor17 8515;
BA_ "SPN" SG_ 2566643198 EnableStatusofDoor18 8518;
BA_ "SPN" SG_ 2566643198 EnableStatusofDoor19 8521;
BA_ "SPN" SG_ 2566643198 EnableStatusofDoor20 8524;
BA_ "SPN" SG_ 2566643198 LockStatusofDoor11 8495;
BA_ "SPN" SG_ 2566643198 LockStatusofDoor12 8498;
BA_ "SPN" SG_ 2566643198 LockStatusofDoor13 8501;
BA_ "SPN" SG_ 2566643198 LockStatusofDoor14 8504;
BA_ "SPN" SG_ 2566643198 LockStatusofDoor15 8507;
BA_ "SPN" SG_ 2566643198 LockStatusofDoor16 8510;
BA_ "SPN" SG_ 2566643198 LockStatusofDoor17 8513;
BA_ "SPN" SG_ 2566643198 LockStatusofDoor18 8516;
BA_ "SPN" SG_ 2566643198 LockStatusofDoor19 8519;
BA_ "SPN" SG_ 2566643198 LockStatusofDoor20 8522;
BA_ "SPN" SG_ 2566643198 OpenStatusofDoor11 8496;
BA_ "SPN" SG_ 2566643198 OpenStatusofDoor12 8499;
BA_ "SPN" SG_ 2566643198 OpenStatusofDoor13 8502;
BA_ "SPN" SG_ 2566643198 OpenStatusofDoor14 8505;
BA_ "SPN" SG_ 2566643198 OpenStatusofDoor15 8508;
BA_ "SPN" SG_ 2566643198 OpenStatusofDoor16 8511;
BA_ "SPN" SG_ 2566643198 OpenStatusofDoor17 8514;
BA_ "SPN" SG_ 2566643198 OpenStatusofDoor18 8517;
BA_ "SPN" SG_ 2566643198 OpenStatusofDoor19 8520;
BA_ "SPN" SG_ 2566643198 OpenStatusofDoor20 8523;
BA_ "SPN" SG_ 2566643454 EngineIntakeCoolantTemperature 8489;
BA_ "SPN" SG_ 2566643454 EngnChrgArClrIntkClntTmprtr 8487;
BA_ "SPN" SG_ 2566643454 EngnChrgArClrOtltClntTmprtr 8488;
BA_ "SPN" SG_ 2566643710 EngineMixer1IntakePressure 8477;
BA_ "SPN" SG_ 2566643710 EngineMixer2IntakePressure 8607;
BA_ "SPN" SG_ 2566644990 DrvrSdFlRptl1CvrStts 8415;
BA_ "SPN" SG_ 2566644990 DrvrSdFlRptl2CvrStts 8416;
BA_ "SPN" SG_ 2566644990 FlStrgCmprtmnt1Tmprtr1 8420;
BA_ "SPN" SG_ 2566644990 FlStrgCmprtmnt1Tmprtr2 8421;
BA_ "SPN" SG_ 2566644990 FlStrgCmprtmnt2Tmprtr1 8422;
BA_ "SPN" SG_ 2566644990 FlStrgCmprtmnt2Tmprtr2 8423;
BA_ "SPN" SG_ 2566644990 FlStrgCmprtmnt3Tmprtr1 8424;
BA_ "SPN" SG_ 2566644990 FlStrgCmprtmnt3Tmprtr2 8425;
BA_ "SPN" SG_ 2566644990 FrontFuelReceptacleCoverStatus 8419;
BA_ "SPN" SG_ 2566644990 PssngrSdFlRptl1CvrStts 8417;
BA_ "SPN" SG_ 2566644990 PssngrSdFlRptl2CvrStts 8418;
BA_ "SPN" SG_ 2566645246 HVESFanCommandStatus 8405;
BA_ "SPN" SG_ 2566645246 HVESFanEnableStatus 8403;
BA_ "SPN" SG_ 2566645246 HVESFanInstance 8411;
BA_ "SPN" SG_ 2566645246 HVESFanMediumTemperature 8407;
BA_ "SPN" SG_ 2566645246 HVESFanOperatingStatus 8410;
BA_ "SPN" SG_ 2566645246 HVESFanPower 8408;
BA_ "SPN" SG_ 2566645246 HVESFanServiceIndicator 8409;
BA_ "SPN" SG_ 2566645246 HVESFanSpeed 8406;
BA_ "SPN" SG_ 2566645246 HVESFanStatusReasonCode 8404;
BA_ "SPN" SG_ 2566646782 OlDrsMntrFrrsBn1Cnt 8168;
BA_ "SPN" SG_ 2566646782 OlDrsMntrFrrsBn2Cnt 8169;
BA_ "SPN" SG_ 2566646782 OlDrsMntrFrrsBns1nd2IdntftnNmr 8167;
BA_ "SPN" SG_ 2566647038 OlDrsMntrFrrsBn3Cnt 8171;
BA_ "SPN" SG_ 2566647038 OlDrsMntrFrrsBn4Cnt 8172;
BA_ "SPN" SG_ 2566647038 OlDrsMntrFrrsBns3nd4IdntftnNmr 8170;
BA_ "SPN" SG_ 2566647294 OlDrsMntrFrrsBn5Cnt 8174;
BA_ "SPN" SG_ 2566647294 OlDrsMntrFrrsBn6Cnt 8175;
BA_ "SPN" SG_ 2566647294 OlDrsMntrFrrsBns5nd6IdntftnNmr 8173;
BA_ "SPN" SG_ 2566647550 ODsMtNFsBs1d2IdttN 8176;
BA_ "SPN" SG_ 2566647550 OlDrsMntrNnFrrsBn1Cnt 8177;
BA_ "SPN" SG_ 2566647550 OlDrsMntrNnFrrsBn2Cnt 8178;
BA_ "SPN" SG_ 2566647806 ODsMtNFsBs3d4IdttN 8179;
BA_ "SPN" SG_ 2566647806 OlDrsMntrNnFrrsBn3Cnt 8180;
BA_ "SPN" SG_ 2566647806 OlDrsMntrNnFrrsBn4Cnt 8181;
BA_ "SPN" SG_ 2566648062 ODsMtNFsBs5d6IdttN 8182;
BA_ "SPN" SG_ 2566648062 OlDrsMntrNnFrrsBn5Cnt 8183;
BA_ "SPN" SG_ 2566648062 OlDrsMntrNnFrrsBn6Cnt 8184;
BA_ "SPN" SG_ 2566648318 OlDrsMntrEltrnsTmprtrStts 8190;
BA_ "SPN" SG_ 2566648318 OlDrsMntrEnvrnmntStts 8187;
BA_ "SPN" SG_ 2566648318 OlDrsMntrSgnlPrssngEltrnsStts 8189;
BA_ "SPN" SG_ 2566648318 OlDrsMntrSnsngElmntStts 8188;
BA_ "SPN" SG_ 2566648318 OlDrsMntrSttsIdntftnNmr 8185;
BA_ "SPN" SG_ 2566648318 OlDrsMntrTtlnmrfSnsrs 8186;
BA_ "SPN" SG_ 2566649086 Atttt2DOCIttDPFOttDtPss 8165;
BA_ "SPN" SG_ 2566649086 Atttt2DsOxdtCtstItPss 8163;
BA_ "SPN" SG_ 2566649086 Atttt2DsOxdtCtstOttPss 8164;
BA_ "SPN" SG_ 2566649342 Atttt1DOCIttDPFOttDtPss 8162;
BA_ "SPN" SG_ 2566649342 Atttt1DsOxdtCtstItPss 8160;
BA_ "SPN" SG_ 2566649342 Atttt1DsOxdtCtstOttPss 8161;
BA_ "SPN" SG_ 2566649598 HorizontalDilutionofPrecision 8129;
BA_ "SPN" SG_ 2566649598 PositionDilutionofPrecision 8131;
BA_ "SPN" SG_ 2566649598 TimeDilutionofPrecision 8132;
BA_ "SPN" SG_ 2566649598 TotalNumberofSatellitesinView 8128;
BA_ "SPN" SG_ 2566649598 VerticalDilutionofPrecision 8130;
BA_ "SPN" SG_ 2566649854 PpsMtCtF3CtCdStts 8069;
BA_ "SPN" SG_ 2566649854 PpsMtCtF3CtSttsRsCd 8068;
BA_ "SPN" SG_ 2566649854 PropulsionMotorCoolantFan3Power 8072;
BA_ "SPN" SG_ 2566649854 PrplsnMtrClntFn3CntrlTmprtr 8071;
BA_ "SPN" SG_ 2566649854 PrplsnMtrClntFn3EnlStts 8067;
BA_ "SPN" SG_ 2566649854 PrplsnMtrClntFn3MtrSpd 8070;
BA_ "SPN" SG_ 2566649854 PrplsnMtrClntFn3OprtngStts 8074;
BA_ "SPN" SG_ 2566649854 PrplsnMtrClntFn3SrvIndtr 8073;
BA_ "SPN" SG_ 2566650110 PpsMtCtF2CtCdStts 8057;
BA_ "SPN" SG_ 2566650110 PpsMtCtF2CtSttsRsCd 8056;
BA_ "SPN" SG_ 2566650110 PropulsionMotorCoolantFan2Power 8060;
BA_ "SPN" SG_ 2566650110 PrplsnMtrClntFn2CntrlTmprtr 8059;
BA_ "SPN" SG_ 2566650110 PrplsnMtrClntFn2EnlStts 8055;
BA_ "SPN" SG_ 2566650110 PrplsnMtrClntFn2MtrSpd 8058;
BA_ "SPN" SG_ 2566650110 PrplsnMtrClntFn2OprtngStts 8062;
BA_ "SPN" SG_ 2566650110 PrplsnMtrClntFn2SrvIndtr 8061;
BA_ "SPN" SG_ 2566650366 PpsMtCtF1CtCdStts 8045;
BA_ "SPN" SG_ 2566650366 PpsMtCtF1CtSttsRsCd 8044;
BA_ "SPN" SG_ 2566650366 PropulsionMotorCoolantFan1Power 8048;
BA_ "SPN" SG_ 2566650366 PrplsnMtrClntFn1CntrlTmprtr 8047;
BA_ "SPN" SG_ 2566650366 PrplsnMtrClntFn1EnlStts 8043;
BA_ "SPN" SG_ 2566650366 PrplsnMtrClntFn1MtrSpd 8046;
BA_ "SPN" SG_ 2566650366 PrplsnMtrClntFn1OprtngStts 8050;
BA_ "SPN" SG_ 2566650366 PrplsnMtrClntFn1SrvIndtr 8049;
BA_ "SPN" SG_ 2566650622 PwEtsCtF3CtCdStts 8033;
BA_ "SPN" SG_ 2566650622 PwEtsCtF3CtSttsRsCd 8032;
BA_ "SPN" SG_ 2566650622 PwrEltrnsClntFn3CntrlTmprtr 8035;
BA_ "SPN" SG_ 2566650622 PwrEltrnsClntFn3EnlStts 8031;
BA_ "SPN" SG_ 2566650622 PwrEltrnsClntFn3MtrSpd 8034;
BA_ "SPN" SG_ 2566650622 PwrEltrnsClntFn3OprtngStts 8038;
BA_ "SPN" SG_ 2566650622 PwrEltrnsClntFn3Pwr 8036;
BA_ "SPN" SG_ 2566650622 PwrEltrnsClntFn3SrvIndtr 8037;
BA_ "SPN" SG_ 2566650878 PwEtsCtF2CtCdStts 8021;
BA_ "SPN" SG_ 2566650878 PwEtsCtF2CtSttsRsCd 8020;
BA_ "SPN" SG_ 2566650878 PwrEltrnsClntFn2CntrlTmprtr 8023;
BA_ "SPN" SG_ 2566650878 PwrEltrnsClntFn2EnlStts 8019;
BA_ "SPN" SG_ 2566650878 PwrEltrnsClntFn2MtrSpd 8022;
BA_ "SPN" SG_ 2566650878 PwrEltrnsClntFn2OprtngStts 8026;
BA_ "SPN" SG_ 2566650878 PwrEltrnsClntFn2Pwr 8024;
BA_ "SPN" SG_ 2566650878 PwrEltrnsClntFn2SrvIndtr 8025;
BA_ "SPN" SG_ 2566651134 PwEtsCtF1CtCdStts 8009;
BA_ "SPN" SG_ 2566651134 PwEtsCtF1CtSttsRsCd 8008;
BA_ "SPN" SG_ 2566651134 PwrEltrnsClntFn1CntrlTmprtr 8011;
BA_ "SPN" SG_ 2566651134 PwrEltrnsClntFn1EnlStts 8007;
BA_ "SPN" SG_ 2566651134 PwrEltrnsClntFn1MtrSpd 8010;
BA_ "SPN" SG_ 2566651134 PwrEltrnsClntFn1OprtngStts 8014;
BA_ "SPN" SG_ 2566651134 PwrEltrnsClntFn1Pwr 8012;
BA_ "SPN" SG_ 2566651134 PwrEltrnsClntFn1SrvIndtr 8013;
BA_ "SPN" SG_ 2566651390 PropulsionMotorOilPumpPower 8000;
BA_ "SPN" SG_ 2566651390 PrplsnMtrOlPmpCntrllrCmmndStts 7997;
BA_ "SPN" SG_ 2566651390 PrplsnMtrOlPmpCntrllrSttsRsnCd 7996;
BA_ "SPN" SG_ 2566651390 PrplsnMtrOlPmpCntrlTmprtr 7999;
BA_ "SPN" SG_ 2566651390 PrplsnMtrOlPmpEnlStts 7995;
BA_ "SPN" SG_ 2566651390 PrplsnMtrOlPmpMtrSpd 7998;
BA_ "SPN" SG_ 2566651390 PrplsnMtrOlPmpOprtngStts 8002;
BA_ "SPN" SG_ 2566651390 PrplsnMtrOlPmpSrvIndtr 8001;
BA_ "SPN" SG_ 2566651646 PpsMtCtPpCtCdStts 7985;
BA_ "SPN" SG_ 2566651646 PpsMtCtPpCtSttsRsCd 7984;
BA_ "SPN" SG_ 2566651646 PropulsionMotorCoolantPumpPower 7988;
BA_ "SPN" SG_ 2566651646 PrplsnMtrClntPmpCntrlTmprtr 7987;
BA_ "SPN" SG_ 2566651646 PrplsnMtrClntPmpEnlStts 7983;
BA_ "SPN" SG_ 2566651646 PrplsnMtrClntPmpMtrSpd 7986;
BA_ "SPN" SG_ 2566651646 PrplsnMtrClntPmpOprtngStts 7990;
BA_ "SPN" SG_ 2566651646 PrplsnMtrClntPmpSrvIndtr 7989;
BA_ "SPN" SG_ 2566651902 PwEtsCtPpCtCdStts 7973;
BA_ "SPN" SG_ 2566651902 PwEtsCtPpCtSttsRsCd 7972;
BA_ "SPN" SG_ 2566651902 PwrEltrnsClntPmpCntrlTmprtr 7975;
BA_ "SPN" SG_ 2566651902 PwrEltrnsClntPmpEnlStts 7971;
BA_ "SPN" SG_ 2566651902 PwrEltrnsClntPmpMtrSpd 7974;
BA_ "SPN" SG_ 2566651902 PwrEltrnsClntPmpOprtngStts 7978;
BA_ "SPN" SG_ 2566651902 PwrEltrnsClntPmpPwr 7976;
BA_ "SPN" SG_ 2566651902 PwrEltrnsClntPmpSrvIndtr 7977;
BA_ "SPN" SG_ 2566652414 ElectrifiedAccessoryMotorPower 7952;
BA_ "SPN" SG_ 2566652414 ElectrifiedAccessoryMotorSpeed 7950;
BA_ "SPN" SG_ 2566652414 EltrfdAssrMtrCntrllrCmmndStts 7949;
BA_ "SPN" SG_ 2566652414 EltrfdAssrMtrCntrllrSttsRsnCd 7948;
BA_ "SPN" SG_ 2566652414 EltrfdAssrMtrEnlStts 7947;
BA_ "SPN" SG_ 2566652414 EltrfdAssrMtrInstn 8308;
BA_ "SPN" SG_ 2566652414 EltrfdAssrMtrMdmTmprtr 7951;
BA_ "SPN" SG_ 2566652414 EltrfdAssrMtrOprtngStts 7954;
BA_ "SPN" SG_ 2566652414 EltrfdAssrMtrSrvIndtr 7953;
BA_ "SPN" SG_ 2566652670 Aftrtrtmnt1SCRSstmHdrrn 7934;
BA_ "SPN" SG_ 2566652670 Aftrtrtmnt2SCRSstmHdrrn 7935;
BA_ "SPN" SG_ 2566652670 Atttt1DsExstFdDsSstFz 6802;
BA_ "SPN" SG_ 2566652670 Atttt2DsExstFdDsSstFz 6803;
BA_ "SPN" SG_ 2566652670 DieselExhaustFluidFrozenTime 7938;
BA_ "SPN" SG_ 2566652926 SLIBatteryPack1Battery4Capacity 7928;
BA_ "SPN" SG_ 2566652926 SLIBatteryPack1Battery4Health 7929;
BA_ "SPN" SG_ 2566652926 SLIBttP1Btt4PdtdMCVt 7930;
BA_ "SPN" SG_ 2566652926 SLIBttrPk1Bttr4SttfChrg 7927;
BA_ "SPN" SG_ 2566652926 SLIBttrPk1Snsr4IntlztnStts 7931;
BA_ "SPN" SG_ 2566653182 SLIBatteryPack1Battery4Voltage 7926;
BA_ "SPN" SG_ 2566653182 SLIBttrPk1Bttr4NtCrrnt 7924;
BA_ "SPN" SG_ 2566653182 SLIBttrPk1Bttr4Tmprtr 7925;
BA_ "SPN" SG_ 2566653438 SLIBatteryPack1Battery3Capacity 7920;
BA_ "SPN" SG_ 2566653438 SLIBatteryPack1Battery3Health 7921;
BA_ "SPN" SG_ 2566653438 SLIBttP1Btt3PdtdMCVt 7922;
BA_ "SPN" SG_ 2566653438 SLIBttrPk1Bttr3SttfChrg 7919;
BA_ "SPN" SG_ 2566653438 SLIBttrPk1Snsr3IntlztnStts 7923;
BA_ "SPN" SG_ 2566653694 SLIBatteryPack1Battery3Voltage 7918;
BA_ "SPN" SG_ 2566653694 SLIBttrPk1Bttr3NtCrrnt 7916;
BA_ "SPN" SG_ 2566653694 SLIBttrPk1Bttr3Tmprtr 7917;
BA_ "SPN" SG_ 2566653950 SLIBatteryPack1Battery2Capacity 7912;
BA_ "SPN" SG_ 2566653950 SLIBatteryPack1Battery2Health 7913;
BA_ "SPN" SG_ 2566653950 SLIBttP1Btt2PdtdMCVt 7914;
BA_ "SPN" SG_ 2566653950 SLIBttrPk1Bttr2SttfChrg 7911;
BA_ "SPN" SG_ 2566653950 SLIBttrPk1Snsr2IntlztnStts 7915;
BA_ "SPN" SG_ 2566654206 SLIBatteryPack1Battery2Voltage 7910;
BA_ "SPN" SG_ 2566654206 SLIBttrPk1Bttr2NtCrrnt 7908;
BA_ "SPN" SG_ 2566654206 SLIBttrPk1Bttr2Tmprtr 7909;
BA_ "SPN" SG_ 2566654462 SLIBatteryPack1Battery1Capacity 7904;
BA_ "SPN" SG_ 2566654462 SLIBatteryPack1Battery1Health 7905;
BA_ "SPN" SG_ 2566654462 SLIBttP1Btt1PdtdMCVt 7906;
BA_ "SPN" SG_ 2566654462 SLIBttrPk1Bttr1SttfChrg 7903;
BA_ "SPN" SG_ 2566654462 SLIBttrPk1Snsr1IntlztnStts 7907;
BA_ "SPN" SG_ 2566654718 SLIBatteryPack1Battery1Voltage 7902;
BA_ "SPN" SG_ 2566654718 SLIBttrPk1Bttr1NtCrrnt 7900;
BA_ "SPN" SG_ 2566654718 SLIBttrPk1Bttr1Tmprtr 7901;
BA_ "SPN" SG_ 2566654974 AtlMxmmAvllEngnPrntFl 8630;
BA_ "SPN" SG_ 2566654974 EsttdEPstLsssPtTqHRst 7837;
BA_ "SPN" SG_ 2566655742 RearHitchPitchSensitivity 7813;
BA_ "SPN" SG_ 2566655742 RearHitchRollSensitivity 7812;
BA_ "SPN" SG_ 2566656254 BarometricAbsolutePressure2 7781;
BA_ "SPN" SG_ 2566656254 EngineIntake2AirTemperature 7850;
BA_ "SPN" SG_ 2566656510 EngnTtlGssFlVlmUsd 7455;
BA_ "SPN" SG_ 2566656510 EngnTtlGssIdlFlVlmUsd 7456;
BA_ "SPN" SG_ 2566658302 TotalPayloadTransactionCount 7701;
BA_ "SPN" SG_ 2566658558 TotalDeliveredPayloadWeight 7699;
BA_ "SPN" SG_ 2566658558 TotalHaulCycleCount 7700;
BA_ "SPN" SG_ 2566661118 EngineTotalDieselFuelDemand 7597;
BA_ "SPN" SG_ 2566661374 Aftrtrtmnt2DslExhstFldTnkHtr2 7575;
BA_ "SPN" SG_ 2566661374 Aftrtrtmnt2DslExhstFldTnkVlm2 7531;
BA_ "SPN" SG_ 2566661374 Atttt2DsExstFdTTpt2 7574;
BA_ "SPN" SG_ 2566661630 Aftrtrtmnt1DslExhstFldTnkHtr2 7573;
BA_ "SPN" SG_ 2566661630 Aftrtrtmnt1DslExhstFldTnkVlm2 7530;
BA_ "SPN" SG_ 2566661630 Atttt1DsExstFdTTpt2 7572;
BA_ "SPN" SG_ 2566661886 Atttt2DsExstFdCt2Tpt 7535;
BA_ "SPN" SG_ 2566661886 Atttt2DsExstFdCtTpt 7529;
BA_ "SPN" SG_ 2566662142 Atttt1DsExstFdCt1Tpt 5480;
BA_ "SPN" SG_ 2566662142 Atttt1DsExstFdCt2Tpt 7528;
BA_ "SPN" SG_ 2566662654 LaneDepartureAngleLeft 7479;
BA_ "SPN" SG_ 2566662654 LaneDepartureAngleRight 7480;
BA_ "SPN" SG_ 2566662654 LaneMarkQualityontheLeftSide 7481;
BA_ "SPN" SG_ 2566662654 LaneMarkQualityontheRightSide 7482;
BA_ "SPN" SG_ 2566662654 LeftLaneMarkerType 8144;
BA_ "SPN" SG_ 2566662654 LftDstntLnMrkfrmVhlsMddl 7476;
BA_ "SPN" SG_ 2566662654 RghtDstntLnMrkfrmVhlsMddl 7477;
BA_ "SPN" SG_ 2566662654 RightLaneMarkerType 8143;
BA_ "SPN" SG_ 2566662654 RoadCurvatureBasedonLaneMarks 7478;
BA_ "SPN" SG_ 2566662910 OprtrIndmntTmtFnlIndmntAtn 7719;
BA_ "SPN" SG_ 2566662910 OprtrIndmntTmtTrqDrtLvl1 7426;
BA_ "SPN" SG_ 2566662910 OprtrIndmntTmtTrqDrtLvl2 7428;
BA_ "SPN" SG_ 2566662910 OprtrIndmntTrqDrtLvl1 7425;
BA_ "SPN" SG_ 2566662910 OprtrIndmntTrqDrtLvl2 7427;
BA_ "SPN" SG_ 2566663166 AppldVhlSpdLmtHghRsltn 7420;
BA_ "SPN" SG_ 2566663166 CrsCntrlAdjstdMxmmSpd 7495;
BA_ "SPN" SG_ 2566663166 EngnExtrnlIdlRqstFdk 8441;
BA_ "SPN" SG_ 2566663166 SAddssCtDvSttCsCt 9844;
BA_ "SPN" SG_ 2566663422 TrlrBrkClprLnngClrnAxl1Lft 7406;
BA_ "SPN" SG_ 2566663422 TrlrBrkClprLnngClrnAxl1Rght 7407;
BA_ "SPN" SG_ 2566663422 TrlrBrkClprLnngClrnAxl2Lft 7408;
BA_ "SPN" SG_ 2566663422 TrlrBrkClprLnngClrnAxl2Rght 7409;
BA_ "SPN" SG_ 2566663422 TrlrBrkClprLnngClrnAxl3Lft 7410;
BA_ "SPN" SG_ 2566663422 TrlrBrkClprLnngClrnAxl3Rght 7411;
BA_ "SPN" SG_ 2566663422 TrlrBrkClprLnngClrnAxl4Lft 7412;
BA_ "SPN" SG_ 2566663422 TrlrBrkClprLnngClrnAxl4Rght 7413;
BA_ "SPN" SG_ 2566663422 TrlrBrkClprLnngClrnAxl5Lft 7414;
BA_ "SPN" SG_ 2566663422 TrlrBrkClprLnngClrnAxl5Rght 7415;
BA_ "SPN" SG_ 2566663422 TrtrBrkClprLnngClrnAxl1Lft 7396;
BA_ "SPN" SG_ 2566663422 TrtrBrkClprLnngClrnAxl1Rght 7397;
BA_ "SPN" SG_ 2566663422 TrtrBrkClprLnngClrnAxl2Lft 7398;
BA_ "SPN" SG_ 2566663422 TrtrBrkClprLnngClrnAxl2Rght 7399;
BA_ "SPN" SG_ 2566663422 TrtrBrkClprLnngClrnAxl3Lft 7400;
BA_ "SPN" SG_ 2566663422 TrtrBrkClprLnngClrnAxl3Rght 7401;
BA_ "SPN" SG_ 2566663422 TrtrBrkClprLnngClrnAxl4Lft 7402;
BA_ "SPN" SG_ 2566663422 TrtrBrkClprLnngClrnAxl4Rght 7403;
BA_ "SPN" SG_ 2566663422 TrtrBrkClprLnngClrnAxl5Lft 7404;
BA_ "SPN" SG_ 2566663422 TrtrBrkClprLnngClrnAxl5Rght 7405;
BA_ "SPN" SG_ 2566663678 EngnFl2InjtrMtrngRl1Tmprtr2 7514;
BA_ "SPN" SG_ 2566663678 LNGTank1VaporPressure 6787;
BA_ "SPN" SG_ 2566663678 LNGTank2VaporPressure 6788;
BA_ "SPN" SG_ 2566663934 EngnClndrHdBpssAttr1MtrCrrntDsl 7382;
BA_ "SPN" SG_ 2566663934 EngnThrttlVlv1MtrCrrntDsl 7383;
BA_ "SPN" SG_ 2566663934 EngnTrhrgrWstgtAttr1MtrCrrntDsl 7381;
BA_ "SPN" SG_ 2566663934 EngnTrhrgrWstgtAttr2MtrCrrntDsl 7710;
BA_ "SPN" SG_ 2566663934 ETCpssBpssAtt1MtCtDs 7708;
BA_ "SPN" SG_ 2566663934 ETCpssBpssAtt2MtCtDs 7709;
BA_ "SPN" SG_ 2566663934 ETCpssBwAtt1MtCtDs 7380;
BA_ "SPN" SG_ 2566664702 AftertreatmentEngineLoadRequest 7503;
BA_ "SPN" SG_ 2566664702 AftrtrtmntAmntArTmprtr 7441;
BA_ "SPN" SG_ 2566664702 AftrtrtmntDslExhstFldHtrCrtBrkr 7588;
BA_ "SPN" SG_ 2566664702 AftrtrtmntDslExhstFldTnkTmprtr 7607;
BA_ "SPN" SG_ 2566664702 AftrtrtmntDslExhstFldTnkVlm 7606;
BA_ "SPN" SG_ 2566664702 AftrtrtmntEngnSpdInrsrqst 7502;
BA_ "SPN" SG_ 2566664702 AftrtrtmntThrmlMngmntStts 7332;
BA_ "SPN" SG_ 2566664702 AttttAtvRtItdDtLwExstPss 7440;
BA_ "SPN" SG_ 2566664702 DslExhstFldQltMlfntnEvltnPrdAtv 7899;
BA_ "SPN" SG_ 2566664702 AftrtrtmntSCRDsngMdStts 9176;
BA_ "SPN" SG_ 2566664702 DPFAtvRgnrtnTmRmnng 10156;
BA_ "SPN" SG_ 2566665726 Aftrtrtmnt2DslExhstFldPmpHtr 7086;
BA_ "SPN" SG_ 2566665726 Atttt2DsExstFdPp2MtSpd 7466;
BA_ "SPN" SG_ 2566667262 EngineEndBearing17Temperature 7059;
BA_ "SPN" SG_ 2566667262 EngineEndBearing18Temperature 7060;
BA_ "SPN" SG_ 2566667262 EngineEndBearing19Temperature 7061;
BA_ "SPN" SG_ 2566667262 EngineEndBearing20Temperature 7062;
BA_ "SPN" SG_ 2566667518 EngineEndBearing10Temperature 7052;
BA_ "SPN" SG_ 2566667518 EngineEndBearing11Temperature 7053;
BA_ "SPN" SG_ 2566667518 EngineEndBearing12Temperature 7054;
BA_ "SPN" SG_ 2566667518 EngineEndBearing13Temperature 7055;
BA_ "SPN" SG_ 2566667518 EngineEndBearing14Temperature 7056;
BA_ "SPN" SG_ 2566667518 EngineEndBearing15Temperature 7057;
BA_ "SPN" SG_ 2566667518 EngineEndBearing16Temperature 7058;
BA_ "SPN" SG_ 2566667518 EngineEndBearing9Temperature 7051;
BA_ "SPN" SG_ 2566667774 EngineEndBearing1Temperature 7043;
BA_ "SPN" SG_ 2566667774 EngineEndBearing2Temperature 7044;
BA_ "SPN" SG_ 2566667774 EngineEndBearing3Temperature 7045;
BA_ "SPN" SG_ 2566667774 EngineEndBearing4Temperature 7046;
BA_ "SPN" SG_ 2566667774 EngineEndBearing5Temperature 7047;
BA_ "SPN" SG_ 2566667774 EngineEndBearing6Temperature 7048;
BA_ "SPN" SG_ 2566667774 EngineEndBearing7Temperature 7049;
BA_ "SPN" SG_ 2566667774 EngineEndBearing8Temperature 7050;
BA_ "SPN" SG_ 2566668030 HeatExchangerDebrisPurgeStatus 7035;
BA_ "SPN" SG_ 2566668030 HtExhngrDrsPrgApprhng 7036;
BA_ "SPN" SG_ 2566668286 EngnStgdTrhrgrSlndStts 7025;
BA_ "SPN" SG_ 2566668542 EngnFl2PmpHdrlDrtnlVlv 7018;
BA_ "SPN" SG_ 2566668542 EngnFl2PmpHdrlFlwCntrlVlv 7016;
BA_ "SPN" SG_ 2566668542 EngnFl2PmpHdrlPrssr 7019;
BA_ "SPN" SG_ 2566668542 EngnFl2PmpHdrlSwshPltAngl 7017;
BA_ "SPN" SG_ 2566668798 EngnFl2InjtrMtrngRl1Prssr 7021;
BA_ "SPN" SG_ 2566668798 EngnFl2InjtrMtrngRl1Prssr2 7513;
BA_ "SPN" SG_ 2566668798 EngnFl2InjtrMtrngRl1Tmprtr 7023;
BA_ "SPN" SG_ 2566668798 EngnFl2InjtrMtrngRl2Prssr 7022;
BA_ "SPN" SG_ 2566668798 EngnFl2InjtrMtrngRl2Tmprtr 7024;
BA_ "SPN" SG_ 2566669054 RequiredTirePressure 6989;
BA_ "SPN" SG_ 2566669054 TireLocation 6987;
BA_ "SPN" SG_ 2566669054 TirePressureExtendedRange 6988;
BA_ "SPN" SG_ 2566669310 ColdInflationPressure 6980;
BA_ "SPN" SG_ 2566669310 ExtrmUndrPrssrPrntgThrshld 6982;
BA_ "SPN" SG_ 2566669310 OverPressurePercentageThreshold 6983;
BA_ "SPN" SG_ 2566669310 OverTemperature 6984;
BA_ "SPN" SG_ 2566669310 TireLocation 6979;
BA_ "SPN" SG_ 2566669310 UndrPrssrPrntgThrshld 6981;
BA_ "SPN" SG_ 2566669822 AntennaNumber 6968;
BA_ "SPN" SG_ 2566669822 TireLocation 6971;
BA_ "SPN" SG_ 2566669822 TireSensorNumber 6970;
BA_ "SPN" SG_ 2566669822 TotalNumberofAntennasUsed 6967;
BA_ "SPN" SG_ 2566669822 TrWrlssSgnlStrngthIndtr 6972;
BA_ "SPN" SG_ 2566669822 TtlNmrfTrSnsrsMntrd 6969;
BA_ "SPN" SG_ 2566670078 NumberofTireSensors 6963;
BA_ "SPN" SG_ 2566670078 TireLocation 6965;
BA_ "SPN" SG_ 2566670078 TireNumber 6964;
BA_ "SPN" SG_ 2566670078 TireSensorIdentificationNumber 6966;
BA_ "SPN" SG_ 2566670334 Axle10MonitoredTireCount 6960;
BA_ "SPN" SG_ 2566670334 Axle11MonitoredTireCount 6961;
BA_ "SPN" SG_ 2566670334 Axle12MonitoredTireCount 6962;
BA_ "SPN" SG_ 2566670334 Axle1MonitoredTireCount 6951;
BA_ "SPN" SG_ 2566670334 Axle2MonitoredTireCount 6952;
BA_ "SPN" SG_ 2566670334 Axle3MonitoredTireCount 6953;
BA_ "SPN" SG_ 2566670334 Axle4MonitoredTireCount 6954;
BA_ "SPN" SG_ 2566670334 Axle5MonitoredTireCount 6955;
BA_ "SPN" SG_ 2566670334 Axle6MonitoredTireCount 6956;
BA_ "SPN" SG_ 2566670334 Axle7MonitoredTireCount 6957;
BA_ "SPN" SG_ 2566670334 Axle8MonitoredTireCount 6958;
BA_ "SPN" SG_ 2566670334 Axle9MonitoredTireCount 6959;
BA_ "SPN" SG_ 2566670334 NumberofAxlesontheVehicle 6949;
BA_ "SPN" SG_ 2566670334 NumberofTiresontheVehicle 6950;
BA_ "SPN" SG_ 2566670590 Atttt2SCRSstAvDstBtwSstCEvts 6947;
BA_ "SPN" SG_ 2566670590 Atttt2SCRSstAvTBtwSstCEvts 6946;
BA_ "SPN" SG_ 2566670590 Atttt2SCRSstTtNSstCEvts 6943;
BA_ "SPN" SG_ 2566670590 Atttt2SCRSstTtNSstCItRqsts 6944;
BA_ "SPN" SG_ 2566670590 Atttt2SCRSstTtNSstCMRqsts 6945;
BA_ "SPN" SG_ 2566670590 Atttt2SCRSstTtSstCT 6942;
BA_ "SPN" SG_ 2566670846 Aftrtrtmnt1SCRSstmTtlClnngTm 6935;
BA_ "SPN" SG_ 2566670846 Atttt1SCRSstAvDstBtwSstCEvts 6940;
BA_ "SPN" SG_ 2566670846 Atttt1SCRSstAvTBtwSstCEvts 6939;
BA_ "SPN" SG_ 2566670846 Atttt1SCRSstTtNSstCEvts 6936;
BA_ "SPN" SG_ 2566670846 Atttt1SCRSstTtNSstCItRqsts 6937;
BA_ "SPN" SG_ 2566670846 Atttt1SCRSstTtNSstCMRqsts 6938;
BA_ "SPN" SG_ 2566670846 TtlAftrtrtmntOprtngHrs 8629;
BA_ "SPN" SG_ 2566671102 Atttt1SCRSstCdtsNtMtAtvC 7848;
BA_ "SPN" SG_ 2566671102 SCRSstCItdDtAtPdOId 6922;
BA_ "SPN" SG_ 2566671102 SCRSstCItdDtLwExstTpt 6926;
BA_ "SPN" SG_ 2566671102 SCRSstCItdDtPtSstLt 6930;
BA_ "SPN" SG_ 2566671102 SCRSstCItdDtVSpdAvAwdSpd 6924;
BA_ "SPN" SG_ 2566671102 SCRSstCItdDtVSpdBwAwdSpd 6932;
BA_ "SPN" SG_ 2566671102 SCRSstmClnngAtmtInttnCnfgrtn 6933;
BA_ "SPN" SG_ 2566671102 SCRSstmClnngInhtdDtClthDsnggd 6919;
BA_ "SPN" SG_ 2566671102 SCRSstmClnngInhtdDtEngnNtWrmdUp 6931;
BA_ "SPN" SG_ 2566671102 SCRSstmClnngInhtdDtInhtSwth 6918;
BA_ "SPN" SG_ 2566671102 SCRSstmClnngInhtdDtOtfNtrl 6923;
BA_ "SPN" SG_ 2566671102 SCRSstmClnngInhtdDtPrkngBrkNtSt 6925;
BA_ "SPN" SG_ 2566671102 SCRSstmClnngInhtdDtPTOAtv 6921;
BA_ "SPN" SG_ 2566671102 SCRSstmClnngInhtdDtSrvBrkAtv 6920;
BA_ "SPN" SG_ 2566671102 SCRSstmClnngInhtdDtSstmFltAtv 6927;
BA_ "SPN" SG_ 2566671102 SCRSstmClnngInhtdDtSstmTmt 6928;
BA_ "SPN" SG_ 2566671102 SCRSstmClnngInhtdDtTmprrSstmLkt 6929;
BA_ "SPN" SG_ 2566671102 SCRSstmClnngInhtdStts 6917;
BA_ "SPN" SG_ 2566671102 SCRSystemCleaningForcedStatus 6934;
BA_ "SPN" SG_ 2566671102 SCRSystemCleaningLampCommand 6915;
BA_ "SPN" SG_ 2566671102 SCRSystemCleaningStatus 6916;
BA_ "SPN" SG_ 2566671358 CylinderFuelRate 7333;
BA_ "SPN" SG_ 2566671358 EngineExhaustFlowRate 6895;
BA_ "SPN" SG_ 2566671358 PEMSEngineFuelMassFlowRate 6893;
BA_ "SPN" SG_ 2566671358 VehicleFuelRate 6894;
BA_ "SPN" SG_ 2566671614 NSCROptIdtOvdEvtsR 6879;
BA_ "SPN" SG_ 2566671614 SCROprtrIndmntOvrrdEnl 6877;
BA_ "SPN" SG_ 2566671614 SCROprtrIndmntOvrrdTmRmnng 6878;
BA_ "SPN" SG_ 2566671614 TtlNmrfSCROprtrIndmntOvrrdEvnts 6880;
BA_ "SPN" SG_ 2566671870 Aftrtrtmnt2DslExhstFldDsr2Prssr 8153;
BA_ "SPN" SG_ 2566671870 Aftrtrtmnt2DslExhstFldDsrPrssr 6876;
BA_ "SPN" SG_ 2566671870 Atttt2DsExstFdDs2AstPss 7464;
BA_ "SPN" SG_ 2566671870 Atttt2DsExstFdDs2Tpt 7465;
BA_ "SPN" SG_ 2566672126 Aftrtrtmnt1DslExhstFldDsr2Prssr 8152;
BA_ "SPN" SG_ 2566672126 Aftrtrtmnt1DslExhstFldDsrPrssr 6875;
BA_ "SPN" SG_ 2566672126 Atttt1DsExstFdDs2AstPss 7459;
BA_ "SPN" SG_ 2566672126 Atttt1DsExstFdDs2Tpt 7460;
BA_ "SPN" SG_ 2566672382 PayloadWeightSensor1Status 6855;
BA_ "SPN" SG_ 2566672382 PayloadWeightSensor2Status 6856;
BA_ "SPN" SG_ 2566672382 PayloadWeightSensor3Status 6857;
BA_ "SPN" SG_ 2566672382 PayloadWeightSensor4Status 6858;
BA_ "SPN" SG_ 2566672382 PayloadWeightSensor5Status 6859;
BA_ "SPN" SG_ 2566672382 PayloadWeightSensor6Status 6860;
BA_ "SPN" SG_ 2566672382 PayloadWeightSensor7Status 6861;
BA_ "SPN" SG_ 2566672382 PayloadWeightSensor8Status 6862;
BA_ "SPN" SG_ 2566672638 DeliveredPayloadConfidence 6850;
BA_ "SPN" SG_ 2566672638 DeliveredPayloadWeight 6849;
BA_ "SPN" SG_ 2566672638 HaulCycleCount 6847;
BA_ "SPN" SG_ 2566672638 HaulModeStatus 6848;
BA_ "SPN" SG_ 2566672638 PldDlvrTrnstnStts 7702;
BA_ "SPN" SG_ 2566673406 GasLeakageDetection1Pressure 6837;
BA_ "SPN" SG_ 2566673406 GasLeakageDetection2Pressure 6838;
BA_ "SPN" SG_ 2566673406 GasLeakageDetection3Pressure 6839;
BA_ "SPN" SG_ 2566673406 GssFlLkg1Cnntrtn 6834;
BA_ "SPN" SG_ 2566673406 GssFlLkg2Cnntrtn 6835;
BA_ "SPN" SG_ 2566673406 GssFlLkg3Cnntrtn 6836;
BA_ "SPN" SG_ 2566674174 AftrtrtmntSCRMlfntnTm 6819;
BA_ "SPN" SG_ 2566674174 SCROperatorInducementTotalTime 7095;
BA_ "SPN" SG_ 2566674430 DslExhstFldQltMlfntnTm 6818;
BA_ "SPN" SG_ 2566674430 DslExhstFldTnk1EmptTm 6817;
BA_ "SPN" SG_ 2566674686 EngnTrhrgr2LOlPrssr 6811;
BA_ "SPN" SG_ 2566674686 EngnTrhrgr2OlTmprtr 8850;
BA_ "SPN" SG_ 2566674686 EngnTrhrgr3LOlPrssr 6812;
BA_ "SPN" SG_ 2566674686 EngnTrhrgr4LOlPrssr 6813;
BA_ "SPN" SG_ 2566675966 HVES1CellMaximumVoltageLimit 8209;
BA_ "SPN" SG_ 2566675966 HVES1CellMinimumVoltageLimit 8210;
BA_ "SPN" SG_ 2566675966 HVES1NominalVoltage 8115;
BA_ "SPN" SG_ 2566675966 HVES1RmmnddMnmmOprtngTmprtr 8208;
BA_ "SPN" SG_ 2566675966 HVES1RmmnddMnmmOprtngVltg 8116;
BA_ "SPN" SG_ 2566675966 HVES1RmmnddMnmmSttOfChrg 8118;
BA_ "SPN" SG_ 2566675966 HVES1RmmnddMxmmOprtngTmprtr 8120;
BA_ "SPN" SG_ 2566675966 HVES1RmmnddMxmmOprtngVltg 8117;
BA_ "SPN" SG_ 2566675966 HVES1RmmnddMxmmSttOfChrg 8119;
BA_ "SPN" SG_ 2566687742 Aftrtrtmnt1PrtltSnsrDttnStts 6777;
BA_ "SPN" SG_ 2566687742 Aftrtrtmnt1PrtltSnsrHtrRsstn 7070;
BA_ "SPN" SG_ 2566687742 Aftrtrtmnt1PrtltSnsrMxmmRsstn 6781;
BA_ "SPN" SG_ 2566687742 Aftrtrtmnt1PrtltSnsrPwrSppl 6778;
BA_ "SPN" SG_ 2566687742 Aftrtrtmnt1PrtltSnsrTmprtr 6780;
BA_ "SPN" SG_ 2566687742 Atttt1PttSsRtFdCt 6779;
BA_ "SPN" SG_ 2566687998 Aftrtrtmnt1PrtltSnsrAtvAmltnTm 6775;
BA_ "SPN" SG_ 2566687998 Aftrtrtmnt1PrtltSnsrHtrStt 6772;
BA_ "SPN" SG_ 2566687998 Aftrtrtmnt1PrtltSnsrRgnrtnStt 6774;
BA_ "SPN" SG_ 2566687998 Aftrtrtmnt1PrtltSnsrRgnrtnStts 6773;
BA_ "SPN" SG_ 2566687998 Aftrtrtmnt1PrtltSnsrRsstn 6771;
BA_ "SPN" SG_ 2566687998 Atttt1PttSsTBtwRts 6776;
BA_ "SPN" SG_ 2566689278 EngineExhaustDesiredNOx 6580;
BA_ "SPN" SG_ 2566689278 EngineExhaustNOx 6579;
BA_ "SPN" SG_ 2566689278 EngnExhstNOxSnsrPwrSppl 9812;
BA_ "SPN" SG_ 2566689534 EngineMainChamberAirFuelRatio 6575;
BA_ "SPN" SG_ 2566689534 EnginePrechamberAirFuelRatio 6577;
BA_ "SPN" SG_ 2566689534 EngnMnChmrDsrdArFlRt 6576;
BA_ "SPN" SG_ 2566689534 EngnPrhmrDsrdArFlRt 6578;
BA_ "SPN" SG_ 2566689790 EngnMnChmrFlAsltPrssr 6571;
BA_ "SPN" SG_ 2566689790 EngnMnChmrFlDsrdAsltPrssr 6572;
BA_ "SPN" SG_ 2566689790 EngnPrhmrFlAsltPrssr 6573;
BA_ "SPN" SG_ 2566689790 EngnPrhmrFlDsrdAsltPrssr 6574;
BA_ "SPN" SG_ 2566690046 AfterrunCompleteThisCycle 6482;
BA_ "SPN" SG_ 2566690046 AttttDsExstFdDsCdwCptLstC 6479;
BA_ "SPN" SG_ 2566690046 AttttDsExstFdDsCdwCptTsC 6478;
BA_ "SPN" SG_ 2566690046 AttttDsExstFdDsCdwItptCt 6476;
BA_ "SPN" SG_ 2566690046 AttttDsExstFdDsPCptLstC 6481;
BA_ "SPN" SG_ 2566690046 AttttDsExstFdDsPCptTsC 6480;
BA_ "SPN" SG_ 2566690046 AttttDsExstFdDsPItptCt 6477;
BA_ "SPN" SG_ 2566690558 EngineCommonRailOilPressure 7720;
BA_ "SPN" SG_ 2566690558 EngineExhaustPressure2 5749;
BA_ "SPN" SG_ 2566690558 EngnCmmnRlOlAsltPrssr 7721;
BA_ "SPN" SG_ 2566690558 EngnExhstPrssr1ExtnddRng 6384;
BA_ "SPN" SG_ 2566690558 EOFtItPssHRstExtddR 7470;
BA_ "SPN" SG_ 2566690814 CircleSteerModeActuatorState 6380;
BA_ "SPN" SG_ 2566690814 CrabSteerModeActuatorState 6381;
BA_ "SPN" SG_ 2566690814 FrontSteeringAxleCenteredStatus 6376;
BA_ "SPN" SG_ 2566690814 RearSteeringAxleCenteredStatus 6377;
BA_ "SPN" SG_ 2566690814 SteeringModeSwitch 6375;
BA_ "SPN" SG_ 2566690814 StrngCntrllrECUTmprtr 6374;
BA_ "SPN" SG_ 2566690814 Wheel2SteerActuatorState 6378;
BA_ "SPN" SG_ 2566690814 Wheel4SteerActuatorState 6379;
BA_ "SPN" SG_ 2566691326 AssemblyUnitIdentification 6369;
BA_ "SPN" SG_ 2566691326 NmrfAssmlUntIdntftnFlds 6368;
BA_ "SPN" SG_ 2566691582 Joystick3Lamp10Status 6367;
BA_ "SPN" SG_ 2566691582 Joystick3Lamp1Status 6358;
BA_ "SPN" SG_ 2566691582 Joystick3Lamp2Status 6359;
BA_ "SPN" SG_ 2566691582 Joystick3Lamp3Status 6360;
BA_ "SPN" SG_ 2566691582 Joystick3Lamp4Status 6361;
BA_ "SPN" SG_ 2566691582 Joystick3Lamp5Status 6362;
BA_ "SPN" SG_ 2566691582 Joystick3Lamp6Status 6363;
BA_ "SPN" SG_ 2566691582 Joystick3Lamp7Status 6364;
BA_ "SPN" SG_ 2566691582 Joystick3Lamp8Status 6365;
BA_ "SPN" SG_ 2566691582 Joystick3Lamp9Status 6366;
BA_ "SPN" SG_ 2566691838 Joystick2Lamp10Status 6357;
BA_ "SPN" SG_ 2566691838 Joystick2Lamp1Status 6348;
BA_ "SPN" SG_ 2566691838 Joystick2Lamp2Status 6349;
BA_ "SPN" SG_ 2566691838 Joystick2Lamp3Status 6350;
BA_ "SPN" SG_ 2566691838 Joystick2Lamp4Status 6351;
BA_ "SPN" SG_ 2566691838 Joystick2Lamp5Status 6352;
BA_ "SPN" SG_ 2566691838 Joystick2Lamp6Status 6353;
BA_ "SPN" SG_ 2566691838 Joystick2Lamp7Status 6354;
BA_ "SPN" SG_ 2566691838 Joystick2Lamp8Status 6355;
BA_ "SPN" SG_ 2566691838 Joystick2Lamp9Status 6356;
BA_ "SPN" SG_ 2566692094 Joystick1Lamp10Status 6347;
BA_ "SPN" SG_ 2566692094 Joystick1Lamp1Status 6338;
BA_ "SPN" SG_ 2566692094 Joystick1Lamp2Status 6339;
BA_ "SPN" SG_ 2566692094 Joystick1Lamp3Status 6340;
BA_ "SPN" SG_ 2566692094 Joystick1Lamp4Status 6341;
BA_ "SPN" SG_ 2566692094 Joystick1Lamp5Status 6342;
BA_ "SPN" SG_ 2566692094 Joystick1Lamp6Status 6343;
BA_ "SPN" SG_ 2566692094 Joystick1Lamp7Status 6344;
BA_ "SPN" SG_ 2566692094 Joystick1Lamp8Status 6345;
BA_ "SPN" SG_ 2566692094 Joystick1Lamp9Status 6346;
BA_ "SPN" SG_ 2566692862 DisplayRemainPowered 6846;
BA_ "SPN" SG_ 2566692862 EngineFuel2Tank1Level 6642;
BA_ "SPN" SG_ 2566692862 EngineFuel2Tank2Level 6643;
BA_ "SPN" SG_ 2566692862 EngineFuel2Tank3Level 6644;
BA_ "SPN" SG_ 2566692862 EngineFuel2Tank4Level 6645;
BA_ "SPN" SG_ 2566692862 EngineOilLevelHighLow 8856;
BA_ "SPN" SG_ 2566692862 EngnOlFltrDffrntlPrssrExtnddRng 6321;
BA_ "SPN" SG_ 2566697470 EngnIgntnCntrlMdl1Stt 6216;
BA_ "SPN" SG_ 2566697470 EngnIgntnCntrlMdl1Tmprtr 6214;
BA_ "SPN" SG_ 2566697470 EngnIgntnCntrlMdl2Stt 6217;
BA_ "SPN" SG_ 2566697470 EngnIgntnCntrlMdl2Tmprtr 6215;
BA_ "SPN" SG_ 2566697726 SwitchedOutput10Current 6121;
BA_ "SPN" SG_ 2566697726 SwitchedOutput11Current 6122;
BA_ "SPN" SG_ 2566697726 SwitchedOutput12Current 6123;
BA_ "SPN" SG_ 2566697726 SwitchedOutput13Current 6124;
BA_ "SPN" SG_ 2566697726 SwitchedOutput14Current 6125;
BA_ "SPN" SG_ 2566697726 SwitchedOutput15Current 6126;
BA_ "SPN" SG_ 2566697726 SwitchedOutput16Current 6127;
BA_ "SPN" SG_ 2566697726 SwitchedOutput17Current 6128;
BA_ "SPN" SG_ 2566697726 SwitchedOutput18Current 6129;
BA_ "SPN" SG_ 2566697726 SwitchedOutput19Current 6130;
BA_ "SPN" SG_ 2566697726 SwitchedOutput1Current 6112;
BA_ "SPN" SG_ 2566697726 SwitchedOutput20Current 6131;
BA_ "SPN" SG_ 2566697726 SwitchedOutput21Current 6132;
BA_ "SPN" SG_ 2566697726 SwitchedOutput22Current 6133;
BA_ "SPN" SG_ 2566697726 SwitchedOutput23Current 6134;
BA_ "SPN" SG_ 2566697726 SwitchedOutput24Current 6135;
BA_ "SPN" SG_ 2566697726 SwitchedOutput25Current 6136;
BA_ "SPN" SG_ 2566697726 SwitchedOutput26Current 6137;
BA_ "SPN" SG_ 2566697726 SwitchedOutput27Current 6138;
BA_ "SPN" SG_ 2566697726 SwitchedOutput28Current 6139;
BA_ "SPN" SG_ 2566697726 SwitchedOutput29Current 6140;
BA_ "SPN" SG_ 2566697726 SwitchedOutput2Current 6113;
BA_ "SPN" SG_ 2566697726 SwitchedOutput30Current 6141;
BA_ "SPN" SG_ 2566697726 SwitchedOutput31Current 6142;
BA_ "SPN" SG_ 2566697726 SwitchedOutput32Current 6143;
BA_ "SPN" SG_ 2566697726 SwitchedOutput3Current 6114;
BA_ "SPN" SG_ 2566697726 SwitchedOutput4Current 6115;
BA_ "SPN" SG_ 2566697726 SwitchedOutput5Current 6116;
BA_ "SPN" SG_ 2566697726 SwitchedOutput6Current 6117;
BA_ "SPN" SG_ 2566697726 SwitchedOutput7Current 6118;
BA_ "SPN" SG_ 2566697726 SwitchedOutput8Current 6119;
BA_ "SPN" SG_ 2566697726 SwitchedOutput9Current 6120;
